VERSION "dbc-export 1 2026.26.6.5"

NS_ :

BS_:

BU_: ADSP APB APP APS APSB BB BMS CC CMP CMPD CP DAS DI DIF DIR DPB EPAS3P EPAS3S EPASTP EPASTS EPBL EPBR ESP EVSE FC GTW HCML HCMR HVP IBST ICR IDB LS OCS1P ODIN PARK PCS PCS2 PLG PM PMF PMR PNCD PTC RADC RCM RCM2 RCM3 RCU SCCM SCM SCS SDCR TAS TCU TCU2 TPMS TRCM UDS UI UIS UMC USM V2G VC VCBATT VCBATT0 VCBATT1 VCBATT2 VCCC VCFRONT VCFRONT1 VCFRONT2 VCLEFT VCRIGHT VCSEAT2L VCSEAT2R VCSEC VEH

BO_ 1056 UIS_log: 8 UIS
 SG_ UIS_logMux M : 0|32@1+ (1,0) [0|4294967295] "" Vector__XXX
 SG_ UIS_zramWriteTicks m0 : 32|32@1+ (1,0) [0|4294967295] "" Vector__XXX
 SG_ UIS_zramWriteIO m1 : 32|32@1+ (1,0) [0|4294967295] "" Vector__XXX
 SG_ UIS_zramReadTicks m2 : 32|32@1+ (1,0) [0|4294967295] "" Vector__XXX
 SG_ UIS_zramReadIO m3 : 32|32@1+ (1,0) [0|4294967295] "" Vector__XXX
 SG_ UIS_zramOriginalSize m4 : 32|32@1+ (1,0) [0|4294967295] "" Vector__XXX
 SG_ UIS_zramNotifyFree m5 : 32|32@1+ (1,0) [0|4294967295] "" Vector__XXX
 SG_ UIS_zramInvalidIO m6 : 32|32@1+ (1,0) [0|4294967295] "" Vector__XXX
 SG_ UIS_zramFailedWrites m7 : 32|32@1+ (1,0) [0|4294967295] "" Vector__XXX
 SG_ UIS_zramFailedReads m8 : 32|32@1+ (1,0) [0|4294967295] "" Vector__XXX
 SG_ UIS_zramCompressionRatio m9 : 32|32@1+ (1,0) [0|4294967295] "" Vector__XXX
 SG_ UIS_zramCompressedSize m10 : 32|32@1+ (1,0) [0|4294967295] "" Vector__XXX
 SG_ UIS_wifiTemperature m11 : 32|32@1+ (1,0) [0|4294967295] "" Vector__XXX
 SG_ UIS_wifiStackState m12 : 32|32@1+ (1,0) [0|4294967295] "" Vector__XXX
 SG_ UIS_wifiStackReady m13 : 32|32@1+ (1,0) [0|4294967295] "" Vector__XXX
 SG_ UIS_wifiBars m14 : 32|32@1+ (1,0) [0|4294967295] "" Vector__XXX
 SG_ UIS_wifiAutoJoinLowRSSI m15 : 32|32@1+ (1,0) [0|1] "" Vector__XXX
 SG_ UIS_webbrowserMemUsage m16 : 32|32@1+ (1,0) [0|4294967295] "" Vector__XXX
 SG_ UIS_webbrowserCPUUsage m17 : 32|32@1+ (1,0) [0|4294967295] "" Vector__XXX
 SG_ UIS_vmtouchMemUsage m18 : 32|32@1+ (1,0) [0|4294967295] "" Vector__XXX
 SG_ UIS_vmtouchCPUUsage m19 : 32|32@1+ (1,0) [0|4294967295] "" Vector__XXX
 SG_ UIS_videodMemUsage m20 : 32|32@1+ (1,0) [0|4294967295] "" Vector__XXX
 SG_ UIS_videodCPUUsage m21 : 32|32@1+ (1,0) [0|4294967295] "" Vector__XXX
 SG_ UIS_vehicleMemUsage m22 : 32|32@1+ (1,0) [0|4294967295] "" Vector__XXX
 SG_ UIS_vehicleCPUUsage m23 : 32|32@1+ (1,0) [0|4294967295] "" Vector__XXX
 SG_ UIS_valhallaserverMemUsage m24 : 32|32@1+ (1,0) [0|4294967295] "" Vector__XXX
 SG_ UIS_valhallaserverCPUUsage m25 : 32|32@1+ (1,0) [0|4294967295] "" Vector__XXX
 SG_ UIS_valetMode m26 : 32|32@1+ (1,0) [0|1] "" Vector__XXX
 SG_ UIS_uiQtCarUptime m27 : 32|32@1+ (1,0) [0|4294967295] "" Vector__XXX
 SG_ UIS_uiQtCarSwapUsage m28 : 32|32@1+ (1,0) [0|4294967295] "" Vector__XXX
 SG_ UIS_uiMeanFPS m29 : 32|32@1+ (1,0) [0|4294967295] "" Vector__XXX
 SG_ UIS_uiMaxFrametime m30 : 32|32@1+ (1,0) [0|4294967295] "" Vector__XXX
 SG_ UIS_uiFrametimeGearShiftPToR m31 : 32|32@1+ (1,0) [0|4294967295] "" Vector__XXX
 SG_ UIS_uiFrametimeGearShiftDToR m32 : 32|32@1+ (1,0) [0|4294967295] "" Vector__XXX
 SG_ UIS_uiFramesOver200Ms m33 : 32|32@1+ (1,0) [0|4294967295] "" Vector__XXX
 SG_ UIS_uiFramesOver100Ms m34 : 32|32@1+ (1,0) [0|4294967295] "" Vector__XXX
 SG_ UIS_tunerVoltageUBatt m35 : 32|32@1+ (1,0) [0|4294967295] "" Vector__XXX
 SG_ UIS_tunerVoltageOperation m36 : 32|32@1+ (1,0) [0|4294967295] "" Vector__XXX
 SG_ UIS_tunerVoltageMQS m37 : 32|32@1+ (1,0) [0|4294967295] "" Vector__XXX
 SG_ UIS_tunerVoltageAntenna2 m38 : 32|32@1+ (1,0) [0|4294967295] "" Vector__XXX
 SG_ UIS_tunerVoltageAntenna1 m39 : 32|32@1+ (1,0) [0|4294967295] "" Vector__XXX
 SG_ UIS_tunerVoltage3V3 m40 : 32|32@1+ (1,0) [0|4294967295] "" Vector__XXX
 SG_ UIS_tunerVoltage1V8 m41 : 32|32@1+ (1,0) [0|4294967295] "" Vector__XXX
 SG_ UIS_tunerTemperatureFahrenheit m42 : 32|32@1+ (1,0) [0|4294967295] "" Vector__XXX
 SG_ UIS_tunerTemperatureCelsius m43 : 32|32@1+ (1,0) [0|4294967295] "" Vector__XXX
 SG_ UIS_tunerCurrentAntenna2 m44 : 32|32@1+ (1,0) [0|4294967295] "" Vector__XXX
 SG_ UIS_tunerCurrentAntenna1 m45 : 32|32@1+ (1,0) [0|4294967295] "" Vector__XXX
 SG_ UIS_touchEventsAggCount m46 : 32|32@1+ (1,0) [0|4294967295] "" Vector__XXX
 SG_ UIS_tmserverMemUsage m47 : 32|32@1+ (1,0) [0|4294967295] "" Vector__XXX
 SG_ UIS_tmserverCPUUsage m48 : 32|32@1+ (1,0) [0|4294967295] "" Vector__XXX
 SG_ UIS_thermalResistance m49 : 32|32@1+ (1,0) [0|4294967295] "C/W" Vector__XXX
 SG_ UIS_thermalProfile m50 : 32|32@1+ (1,0) [1|4294967295] "" Vector__XXX
 SG_ UIS_testDriveMode m51 : 32|32@1+ (1,0) [0|4294967295] "" Vector__XXX
 SG_ UIS_teslachromiumMemUsage m52 : 32|32@1+ (1,0) [0|4294967295] "" Vector__XXX
 SG_ UIS_teslachromiumCPUUsage m53 : 32|32@1+ (1,0) [0|4294967295] "" Vector__XXX
 SG_ UIS_teslaMediaCacheSize m54 : 32|32@1+ (1,0) [0|4294967295] "" Vector__XXX
 SG_ UIS_teslaMediaCacheCost m55 : 32|32@1+ (1,0) [0|4294967295] "" Vector__XXX
 SG_ UIS_teleopStreamXrunCount m56 : 32|32@1+ (1,0) [0|4294967295] "" Vector__XXX
 SG_ UIS_teleopPhoneCallActive m57 : 32|32@1+ (1,0) [0|4294967295] "" Vector__XXX
 SG_ UIS_teleopPacketDrops m58 : 32|32@1+ (1,0) [0|4294967295] "" Vector__XXX
 SG_ UIS_teleopMinPacketDelta m59 : 32|32@1+ (0.0001,0) [0|429496.7295] "ms" Vector__XXX
 SG_ UIS_teleopMaxPacketDelta m60 : 32|32@1+ (0.0001,0) [0|429496.7295] "ms" Vector__XXX
 SG_ UIS_teleopAvgPacketDelta m61 : 32|32@1+ (0.0001,0) [0|429496.7295] "ms" Vector__XXX
 SG_ UIS_tegraModemManState m62 : 32|32@1+ (1,0) [0|4294967295] "" Vector__XXX
 SG_ UIS_systemWakeTime m63 : 32|32@1+ (1,0) [0|4294967295] "" Vector__XXX
 SG_ UIS_systemUptime m64 : 32|32@1+ (1,0) [0|4294967295] "" Vector__XXX
 SG_ UIS_systemMemSwapUsage m65 : 32|32@1+ (1,0) [0|4294967295] "" Vector__XXX
 SG_ UIS_suspensionGeofence m66 : 32|32@1+ (1,0) [0|1] "" Vector__XXX
 SG_ UIS_superchargePaymentNeeded m67 : 32|32@1+ (1,0) [0|4294967295] "" Vector__XXX
 SG_ UIS_sudokuMemUsage m68 : 32|32@1+ (1,0) [0|4294967295] "" Vector__XXX
 SG_ UIS_sudokuCPUUsage m69 : 32|32@1+ (1,0) [0|4294967295] "" Vector__XXX
 SG_ UIS_spotifyserverMemUsage m70 : 32|32@1+ (1,0) [0|4294967295] "" Vector__XXX
 SG_ UIS_spotifyserverCPUUsage m71 : 32|32@1+ (1,0) [0|4294967295] "" Vector__XXX
 SG_ UIS_speechrecoMemUsage m72 : 32|32@1+ (1,0) [0|4294967295] "" Vector__XXX
 SG_ UIS_speechrecoCPUUsage m73 : 32|32@1+ (1,0) [0|4294967295] "" Vector__XXX
 SG_ UIS_solitaireMemUsage m74 : 32|32@1+ (1,0) [0|4294967295] "" Vector__XXX
 SG_ UIS_solitaireCPUUsage m75 : 32|32@1+ (1,0) [0|4294967295] "" Vector__XXX
 SG_ UIS_softwareUpdateState m76 : 32|32@1+ (1,0) [0|4294967295] "" Vector__XXX
 SG_ UIS_softwareUpdatePrimDownload m77 : 32|32@1+ (1,0) [0|4294967295] "" Vector__XXX
 SG_ UIS_softwareInstallPopupStatus m78 : 32|32@1+ (1,0) [0|4294967295] "" Vector__XXX
 SG_ UIS_sleepType m79 : 32|32@1+ (1,0) [0|4294967295] "" Vector__XXX
 SG_ UIS_sleepTime m80 : 32|32@1+ (1,0) [0|4294967295] "" Vector__XXX
 SG_ UIS_sleepState m81 : 32|32@1+ (1,0) [0|4294967295] "" Vector__XXX
 SG_ UIS_sleepCount m82 : 32|32@1+ (1,0) [0|4294967295] "" Vector__XXX
 SG_ UIS_slackerLoginResult m83 : 32|32@1+ (1,0) [0|4294967295] "" Vector__XXX
 SG_ UIS_settingsAutoTurnSignal m84 : 32|32@1+ (1,0) [0|4294967295] "" Vector__XXX
 SG_ UIS_serviceModePlus m85 : 32|32@1+ (1,0) [0|4294967295] "" Vector__XXX
 SG_ UIS_serviceMode m86 : 32|32@1+ (1,0) [0|4294967295] "" Vector__XXX
 SG_ UIS_serverMemUsage m87 : 32|32@1+ (1,0) [0|4294967295] "" Vector__XXX
 SG_ UIS_serverCPUUsage m88 : 32|32@1+ (1,0) [0|4294967295] "" Vector__XXX
 SG_ UIS_sentryState m89 : 32|32@1+ (1,0) [0|4294967295] "" Vector__XXX
 SG_ UIS_sentryNeedsNap m90 : 32|32@1+ (1,0) [0|4294967295] "" Vector__XXX
 SG_ UIS_sentryIncidentCount m91 : 32|32@1+ (1,0) [0|4294967295] "" Vector__XXX
 SG_ UIS_scheduledChargingMode m92 : 32|32@1+ (1,0) [0|4294967295] "" Vector__XXX
 SG_ UIS_scheduleChargeStartTime m93 : 32|32@1+ (1,0) [0|4294967295] "" Vector__XXX
 SG_ UIS_scheduleChargeEndTime m94 : 32|32@1+ (1,0) [0|4294967295] "" Vector__XXX
 SG_ UIS_robotaxiModeActive m95 : 32|32@1+ (1,0) [0|4294967295] "" Vector__XXX
 SG_ UIS_remoteRequestType m96 : 32|32@1+ (1,0) [0|4294967295] "" Vector__XXX
 SG_ UIS_releasenotesMemUsage m97 : 32|32@1+ (1,0) [0|4294967295] "" Vector__XXX
 SG_ UIS_releasenotesCPUUsage m98 : 32|32@1+ (1,0) [0|4294967295] "" Vector__XXX
 SG_ UIS_rearDisplayUserPresent m99 : 32|32@1+ (1,0) [0|1] "" Vector__XXX
 SG_ UIS_rearDisplayState m100 : 32|32@1+ (1,0) [0|4294967295] "" Vector__XXX
 SG_ UIS_radioserveMemUsage m101 : 32|32@1+ (1,0) [0|4294967295] "" Vector__XXX
 SG_ UIS_radioserveCPUUsage m102 : 32|32@1+ (1,0) [0|4294967295] "" Vector__XXX
 SG_ UIS_qtcarMemUsage m103 : 32|32@1+ (1,0) [0|4294967295] "" Vector__XXX
 SG_ UIS_qtcarCPUUsage m104 : 32|32@1+ (1,0) [0|4294967295] "" Vector__XXX
 SG_ UIS_psiMemSome m105 : 32|32@1+ (1,0) [0|4294967295] "" Vector__XXX
 SG_ UIS_psiMemFull m106 : 32|32@1+ (1,0) [0|4294967295] "" Vector__XXX
 SG_ UIS_psiIOSome m107 : 32|32@1+ (1,0) [0|4294967295] "" Vector__XXX
 SG_ UIS_psiIOFull m108 : 32|32@1+ (1,0) [0|4294967295] "" Vector__XXX
 SG_ UIS_psiCpuSome m109 : 32|32@1+ (1,0) [0|4294967295] "" Vector__XXX
 SG_ UIS_powerManagerState m110 : 32|5@1+ (1,0) [0|31] "" Vector__XXX
 SG_ UIS_polytopiax8664MemUsage m111 : 32|32@1+ (1,0) [0|4294967295] "" Vector__XXX
 SG_ UIS_polytopiax8664CPUUsage m112 : 32|32@1+ (1,0) [0|4294967295] "" Vector__XXX
 SG_ UIS_odinStatusCmdResult m113 : 32|32@1+ (1,0) [0|4294967295] "" Vector__XXX
 SG_ UIS_odinStatusCmdDurationMs m114 : 32|32@1+ (1,0) [0|4294967295] "" Vector__XXX
 SG_ UIS_odinProcessState m115 : 32|32@1+ (1,0) [0|4294967295] "" Vector__XXX
 SG_ UIS_odinPeriodicTaskState m116 : 32|32@1+ (1,0) [0|4294967295] "" Vector__XXX
 SG_ UIS_odinOrchestratorStartCount m117 : 32|32@1+ (1,0) [0|4294967295] "" Vector__XXX
 SG_ UIS_odinOrchestratorFailCount m118 : 32|32@1+ (1,0) [0|4294967295] "" Vector__XXX
 SG_ UIS_odinNetworkStartCount m119 : 32|32@1+ (1,0) [0|4294967295] "" Vector__XXX
 SG_ UIS_odinNetworkFailCount m120 : 32|32@1+ (1,0) [0|4294967295] "" Vector__XXX
 SG_ UIS_odinMemUsage m121 : 32|32@1+ (1,0) [0|4294967295] "" Vector__XXX
 SG_ UIS_odinListTasksCmdResult m122 : 32|32@1+ (1,0) [0|4294967295] "" Vector__XXX
 SG_ UIS_odinListTasksCmdDurationMs m123 : 32|32@1+ (1,0) [0|4294967295] "" Vector__XXX
 SG_ UIS_odinHrlUploadLimits m124 : 32|32@1+ (1,0) [0|4294967295] "" Vector__XXX
 SG_ UIS_odinHrlLogUploadState m125 : 32|32@1+ (1,0) [0|4294967295] "" Vector__XXX
 SG_ UIS_odinHermesConnectionState m126 : 32|32@1+ (1,0) [0|4294967295] "" Vector__XXX
 SG_ UIS_odinGatewayConnectionState m127 : 32|32@1+ (1,0) [0|4294967295] "" Vector__XXX
 SG_ UIS_odinFileSystemState m128 : 32|32@1+ (1,0) [0|4294967295] "" Vector__XXX
 SG_ UIS_odinEcuLogUploadState m129 : 32|32@1+ (1,0) [0|4294967295] "" Vector__XXX
 SG_ UIS_odinEcuLogForceTriggerUpload m130 : 32|32@1+ (1,0) [0|4294967295] "" Vector__XXX
 SG_ UIS_odinCPUUsage m131 : 32|32@1+ (1,0) [0|4294967295] "" Vector__XXX
 SG_ UIS_odinAuthFailCount m132 : 32|32@1+ (1,0) [0|4294967295] "" Vector__XXX
 SG_ UIS_odinAuthCount m133 : 32|32@1+ (1,0) [0|4294967295] "" Vector__XXX
 SG_ UIS_nvmeTemperature m134 : 32|32@1+ (1,0) [0|4294967295] "" Vector__XXX
 SG_ UIS_nvmePercentLifetimeUsed m135 : 32|32@1+ (1,0) [0|4294967295] "" Vector__XXX
 SG_ UIS_nvmeDataUnitsWritten100mb m136 : 32|32@1+ (1,0) [0|4294967295] "" Vector__XXX
 SG_ UIS_numUncorrMemErrorsECC m137 : 32|32@1+ (1,0) [0|4294967295] "" Vector__XXX
 SG_ UIS_numCorrMemErrorsECC m138 : 32|32@1+ (1,0) [0|4294967295] "" Vector__XXX
 SG_ UIS_nuanceserverMemUsage m139 : 32|32@1+ (1,0) [0|4294967295] "" Vector__XXX
 SG_ UIS_nuanceserverCPUUsage m140 : 32|32@1+ (1,0) [0|4294967295] "" Vector__XXX
 SG_ UIS_netWifiTxRate m141 : 32|32@1+ (0.001,0) [0|4294967.295] "Megabytes per second (MBps)" Vector__XXX
 SG_ UIS_netWifiTxCount m142 : 32|32@1+ (0.001,0) [0|4294967.295] "Megabytes" Vector__XXX
 SG_ UIS_netWifiRxRate m143 : 32|32@1+ (0.001,0) [0|4294967.295] "Megabytes per second (MBps)" Vector__XXX
 SG_ UIS_netWifiRxCount m144 : 32|32@1+ (0.001,0) [0|4294967.295] "Megabytes" Vector__XXX
 SG_ UIS_netEthTxRate m145 : 32|32@1+ (0.001,0) [0|4294967.295] "Megabytes per second (MBps)" Vector__XXX
 SG_ UIS_netEthTxCount m146 : 32|32@1+ (0.001,0) [0|4294967.295] "Megabytes" Vector__XXX
 SG_ UIS_netEthRxRate m147 : 32|32@1+ (0.001,0) [0|4294967.295] "Megabytes per second (MBps)" Vector__XXX
 SG_ UIS_netEthRxErrorRate m148 : 32|32@1+ (1,0) [0|4294967295] "" Vector__XXX
 SG_ UIS_netEthRxErrorCount m149 : 32|32@1+ (1,0) [0|4294967295] "" Vector__XXX
 SG_ UIS_netEthRxDroppedRate m150 : 32|32@1+ (1,0) [0|4294967295] "" Vector__XXX
 SG_ UIS_netEthRxDroppedCount m151 : 32|32@1+ (1,0) [0|4294967295] "" Vector__XXX
 SG_ UIS_netEthRxCount m152 : 32|32@1+ (0.001,0) [0|4294967.295] "Megabytes" Vector__XXX
 SG_ UIS_netCellTxRate m153 : 32|32@1+ (0.001,0) [0|4294967.295] "Megabytes per second (MBps)" Vector__XXX
 SG_ UIS_netCellTxCount m154 : 32|32@1+ (0.001,0) [0|4294967.295] "Megabytes" Vector__XXX
 SG_ UIS_netCellRxRate m155 : 32|32@1+ (0.001,0) [0|4294967.295] "Megabytes per second (MBps)" Vector__XXX
 SG_ UIS_netCellRxCount m156 : 32|32@1+ (0.001,0) [0|4294967.295] "Megabytes" Vector__XXX
 SG_ UIS_navServiceError m157 : 32|32@1+ (1,0) [0|4294967295] "" Vector__XXX
 SG_ UIS_navAudioVolume m158 : 32|32@1+ (1,0) [0|4294967295] "" Vector__XXX
 SG_ UIS_muteNavVolume m159 : 32|32@1+ (1,0) [0|4294967295] "" Vector__XXX
 SG_ UIS_mounterdState m160 : 32|32@1+ (1,0) [0|4294967295] "" Vector__XXX
 SG_ UIS_mounterdMountCountTotal m161 : 32|32@1+ (1,0) [0|4294967295] "" Vector__XXX
 SG_ UIS_mounterdFrontHubDisconnected m162 : 32|32@1+ (1,0) [0|4294967295] "" Vector__XXX
 SG_ UIS_mounterdFrontHubConnected m163 : 32|32@1+ (1,0) [0|4294967295] "" Vector__XXX
 SG_ UIS_mounterdFilesystemCountFat32 m164 : 32|32@1+ (1,0) [0|4294967295] "" Vector__XXX
 SG_ UIS_mounterdFilesystemCountExt4 m165 : 32|32@1+ (1,0) [0|4294967295] "" Vector__XXX
 SG_ UIS_mounterdFilesystemCountExt3 m166 : 32|32@1+ (1,0) [0|4294967295] "" Vector__XXX
 SG_ UIS_mounterdFilesystemCountExfat m167 : 32|32@1+ (1,0) [0|4294967295] "" Vector__XXX
 SG_ UIS_mounterdEncryptionCapacityGB m168 : 32|32@1+ (1,0) [0|4294967295] "" Vector__XXX
 SG_ UIS_mounterdDeviceCount m169 : 32|32@1+ (1,0) [0|4294967295] "" Vector__XXX
 SG_ UIS_mounterdDashcamCapacityGB m170 : 32|32@1+ (1,0) [0|4294967295] "" Vector__XXX
 SG_ UIS_modemECallppAvail m171 : 32|32@1+ (1,0) [0|1] "" Vector__XXX
 SG_ UIS_modemBusyActive m172 : 32|32@1+ (1,0) [0|1] "" Vector__XXX
 SG_ UIS_mirrorGeofenceActive m173 : 32|32@1+ (1,0) [0|1] "" Vector__XXX
 SG_ UIS_mediaserveMemUsage m174 : 32|32@1+ (1,0) [0|4294967295] "" Vector__XXX
 SG_ UIS_mediaserveCPUUsage m175 : 32|32@1+ (1,0) [0|4294967295] "" Vector__XXX
 SG_ UIS_mediaPlaybackStatus m176 : 32|32@1+ (1,0) [0|4294967295] "" Vector__XXX
 SG_ UIS_mediaNeedAuthToken m177 : 32|32@1+ (1,0) [0|1] "" Vector__XXX
 SG_ UIS_mediaImageCacheSize m178 : 32|32@1+ (1,0) [0|4294967295] "" Vector__XXX
 SG_ UIS_mediaImageCacheCost m179 : 32|32@1+ (1,0) [0|4294967295] "" Vector__XXX
 SG_ UIS_limex8664MemUsage m180 : 32|32@1+ (1,0) [0|4294967295] "" Vector__XXX
 SG_ UIS_limex8664CPUUsage m181 : 32|32@1+ (1,0) [0|4294967295] "" Vector__XXX
 SG_ UIS_inSuperchargerGeofence m182 : 32|32@1+ (1,0) [0|1] "" Vector__XXX
 SG_ UIS_igpuTemperature m183 : 32|32@1+ (1,0) [0|4294967295] "" Vector__XXX
 SG_ UIS_homelinkState m184 : 32|32@1+ (1,0) [0|4294967295] "" Vector__XXX
 SG_ UIS_hicarServiceState m185 : 32|32@1+ (1,0) [0|4294967295] "" Vector__XXX
 SG_ UIS_hicarEventCode m186 : 32|32@1+ (1,0) [0|4294967295] "" Vector__XXX
 SG_ UIS_hicarErrorCode m187 : 32|32@1+ (1,0) [0|4294967295] "" Vector__XXX
 SG_ UIS_hicarDataReceiveType m188 : 32|32@1+ (1,0) [0|4294967295] "" Vector__XXX
 SG_ UIS_hicarConnectionState m189 : 32|32@1+ (1,0) [0|4294967295] "" Vector__XXX
 SG_ UIS_hicarCallState m190 : 32|32@1+ (1,0) [0|4294967295] "" Vector__XXX
 SG_ UIS_hicarAudioTeardownState m191 : 32|32@1+ (1,0) [0|4294967295] "" Vector__XXX
 SG_ UIS_hicarAudioSetupState m192 : 32|32@1+ (1,0) [0|4294967295] "" Vector__XXX
 SG_ UIS_hermesdynamicMemUsage m193 : 32|32@1+ (1,0) [0|4294967295] "" Vector__XXX
 SG_ UIS_hermesdynamicCPUUsage m194 : 32|32@1+ (1,0) [0|4294967295] "" Vector__XXX
 SG_ UIS_hermesclientMemUsage m195 : 32|32@1+ (1,0) [0|4294967295] "" Vector__XXX
 SG_ UIS_hermesclientCPUUsage m196 : 32|32@1+ (1,0) [0|4294967295] "" Vector__XXX
 SG_ UIS_headsetPairResult m197 : 32|32@1+ (1,0) [0|4294967295] "" Vector__XXX
 SG_ UIS_headsetConnectionState m198 : 32|32@1+ (1,0) [0|4294967295] "" Vector__XXX
 SG_ UIS_gtwSocUartTxStatTimeouts m199 : 32|32@1+ (1,0) [0|4294967295] "" Vector__XXX
 SG_ UIS_gtwSocUartTxStatPackets m200 : 32|32@1+ (1,0) [0|4294967295] "" Vector__XXX
 SG_ UIS_gtwSocUartTxStatNacks m201 : 32|32@1+ (1,0) [0|4294967295] "" Vector__XXX
 SG_ UIS_gtwSocUartTxStatBadTooBig m202 : 32|32@1+ (1,0) [0|4294967295] "" Vector__XXX
 SG_ UIS_gtwSocUartTxStatAnsMismatch m203 : 32|32@1+ (1,0) [0|4294967295] "" Vector__XXX
 SG_ UIS_gtwSocUartRxStatValidPackets m204 : 32|32@1+ (1,0) [0|4294967295] "" Vector__XXX
 SG_ UIS_gtwSocUartRxStatUnhandled m205 : 32|32@1+ (1,0) [0|4294967295] "" Vector__XXX
 SG_ UIS_gtwSocUartRxStatMsgErr m206 : 32|32@1+ (1,0) [0|4294967295] "" Vector__XXX
 SG_ UIS_gtwSocUartRxStatHeartbeats m207 : 32|32@1+ (1,0) [0|4294967295] "" Vector__XXX
 SG_ UIS_gtwSocUartRxStatHandleErr m208 : 32|32@1+ (1,0) [0|4294967295] "" Vector__XXX
 SG_ UIS_gtwSocUartRxStatBadTooSmall m209 : 32|32@1+ (1,0) [0|4294967295] "" Vector__XXX
 SG_ UIS_gtwSocUartRxStatBadTooBig m210 : 32|32@1+ (1,0) [0|4294967295] "" Vector__XXX
 SG_ UIS_gtwSocUartRxStatBadChecksum m211 : 32|32@1+ (1,0) [0|4294967295] "" Vector__XXX
 SG_ UIS_gpsmanagerMemUsage m212 : 32|32@1+ (1,0) [0|4294967295] "" Vector__XXX
 SG_ UIS_gpsmanagerCPUUsage m213 : 32|32@1+ (1,0) [0|4294967295] "" Vector__XXX
 SG_ UIS_godot_TIME_PROCESS m214 : 32|32@1+ (1,0) [0|4294967295] "" Vector__XXX
 SG_ UIS_godot_TIME_FPS m215 : 32|32@1+ (1,0) [0|4294967295] "" Vector__XXX
 SG_ UIS_godot_MEMORY_STATIC m216 : 32|32@1+ (1,0) [0|4294967295] "" Vector__XXX
 SG_ UIS_godot_MEMORY_DYNAMIC m217 : 32|32@1+ (1,0) [0|4294967295] "" Vector__XXX
 SG_ UIS_godotMemUsage m218 : 32|32@1+ (1,0) [0|4294967295] "" Vector__XXX
 SG_ UIS_godotCPUUsage m219 : 32|32@1+ (1,0) [0|4294967295] "" Vector__XXX
 SG_ UIS_firmwareReleaseScope m220 : 32|32@1+ (1,0) [0|4294967295] "" Vector__XXX
 SG_ UIS_featureSuperchargingEnabled m221 : 32|32@1+ (1,0) [0|4294967295] "" Vector__XXX
 SG_ UIS_estimatedOccupancyCount m222 : 32|32@1+ (1,0) [0|4294967295] "" Vector__XXX
 SG_ UIS_embeddedGameState m223 : 32|32@1+ (1,0) [0|4294967295] "" Vector__XXX
 SG_ UIS_embeddedGameName m224 : 32|32@1+ (1,0) [0|4294967295] "" Vector__XXX
 SG_ UIS_dynamicTriggersTelemetryServ m225 : 32|32@1+ (1,0) [0|4294967295] "" Vector__XXX
 SG_ UIS_dynamicTriggersOutputManager m226 : 32|32@1+ (1,0) [0|4294967295] "" Vector__XXX
 SG_ UIS_dynamicTriggersHRLServiceSta m227 : 32|32@1+ (1,0) [0|4294967295] "" Vector__XXX
 SG_ UIS_dynamicTriggersCampaignState m228 : 32|32@1+ (1,0) [1|4294967295] "" Vector__XXX
 SG_ UIS_dumTclipUploadState m229 : 32|32@1+ (1,0) [0|4294967295] "" Vector__XXX
 SG_ UIS_dumTclipUploadActive m230 : 32|32@1+ (1,0) [0|4294967295] "" Vector__XXX
 SG_ UIS_dumTclipTransferCount m231 : 32|32@1+ (1,0) [0|4294967295] "" Vector__XXX
 SG_ UIS_dumTclipSuccessfulUploadCoun m232 : 32|32@1+ (1,0) [0|4294967295] "" Vector__XXX
 SG_ UIS_dumTclipClipCount m233 : 32|32@1+ (1,0) [0|4294967295] "" Vector__XXX
 SG_ UIS_dmRearTouchDeviceExists m234 : 32|32@1+ (1,0) [0|4294967295] "" Vector__XXX
 SG_ UIS_dmRearPowerState m235 : 32|32@1+ (1,0) [0|1] "" Vector__XXX
 SG_ UIS_dmRearLinkCheckOk m236 : 32|32@1+ (1,0) [0|1] "" Vector__XXX
 SG_ UIS_dmRearEnabled m237 : 32|32@1+ (1,0) [0|4294967295] "" Vector__XXX
 SG_ UIS_dmRearConnected m238 : 32|32@1+ (1,0) [0|4294967295] "" Vector__XXX
 SG_ UIS_dmRearBacklightPowerLevel m239 : 32|32@1+ (1,0) [0|4294967295] "" Vector__XXX
 SG_ UIS_dmRearBacklightNits m240 : 32|32@1+ (1,0) [0|4294967295] "" Vector__XXX
 SG_ UIS_dmRearBacklightFault m241 : 32|32@1+ (1,0) [0|4294967295] "" Vector__XXX
 SG_ UIS_dmRearBacklightDutyCycle m242 : 32|32@1+ (1,0) [0|4294967295] "" Vector__XXX
 SG_ UIS_dmRearBacklightDevExists m243 : 32|32@1+ (1,0) [0|1] "" Vector__XXX
 SG_ UIS_dmRearAsilStatusMsb m244 : 32|32@1+ (1,0) [0|4294967295] "" Vector__XXX
 SG_ UIS_dmRearAsilStatusLsb m245 : 32|32@1+ (1,0) [0|4294967295] "" Vector__XXX
 SG_ UIS_dmIcuTouchIrqCount m246 : 32|32@1+ (1,0) [0|4294967295] "" Vector__XXX
 SG_ UIS_dmIcuPowerState m247 : 32|32@1+ (1,0) [0|1] "" Vector__XXX
 SG_ UIS_dmIcuLinkCheckOk m248 : 32|32@1+ (1,0) [0|1] "" Vector__XXX
 SG_ UIS_dmIcuEnabled m249 : 32|32@1+ (1,0) [0|4294967295] "" Vector__XXX
 SG_ UIS_dmIcuConnected m250 : 32|32@1+ (1,0) [0|4294967295] "" Vector__XXX
 SG_ UIS_dmIcuBacklightPowerLevel m251 : 32|32@1+ (1,0) [0|4294967295] "" Vector__XXX
 SG_ UIS_dmIcuBacklightNits m252 : 32|32@1+ (1,0) [0|4294967295] "" Vector__XXX
 SG_ UIS_dmIcuBacklightFault m253 : 32|32@1+ (1,0) [0|4294967295] "" Vector__XXX
 SG_ UIS_dmIcuBacklightDutyCycle m254 : 32|32@1+ (1,0) [0|4294967295] "" Vector__XXX
 SG_ UIS_dmIcuBacklightDevExists m255 : 32|32@1+ (1,0) [0|1] "" Vector__XXX
 SG_ UIS_dmIcuAsilShortFlag m256 : 32|32@1+ (1,0) [0|4294967295] "" Vector__XXX
 SG_ UIS_dmIcuAsilResumeFlag m257 : 32|32@1+ (1,0) [0|4294967295] "" Vector__XXX
 SG_ UIS_dmIcuAsilOpenFlag m258 : 32|32@1+ (1,0) [0|4294967295] "" Vector__XXX
 SG_ UIS_dmIcuAsilFirmwareStatus m259 : 32|32@1+ (1,0) [0|4294967295] "" Vector__XXX
 SG_ UIS_dmGatewayLinkWedged m260 : 32|32@1+ (1,0) [0|4294967295] "" Vector__XXX
 SG_ UIS_dmCenterTouchIrqCount m261 : 32|32@1+ (1,0) [0|4294967295] "" Vector__XXX
 SG_ UIS_dmCenterTouchDeviceExists m262 : 32|32@1+ (1,0) [0|4294967295] "" Vector__XXX
 SG_ UIS_dmCenterSOsdVideoCrcData m263 : 32|32@1+ (1,0) [0|4294967295] "" Vector__XXX
 SG_ UIS_dmCenterSOsdExactCrcCheck m264 : 32|32@1+ (1,0) [0|4294967295] "" Vector__XXX
 SG_ UIS_dmCenterPowerState m265 : 32|32@1+ (1,0) [0|1] "" Vector__XXX
 SG_ UIS_dmCenterOsdDisplayedState m266 : 32|32@1+ (1,0) [0|1] "" Vector__XXX
 SG_ UIS_dmCenterOsdDayNightState m267 : 32|32@1+ (1,0) [0|4294967295] "" Vector__XXX
 SG_ UIS_dmCenterModeSettingStatus m268 : 32|32@1+ (1,0) [0|4294967295] "" Vector__XXX
 SG_ UIS_dmCenterMOsdVideoCrcData m269 : 32|32@1+ (1,0) [0|4294967295] "" Vector__XXX
 SG_ UIS_dmCenterMOsdExactCrcCheck m270 : 32|32@1+ (1,0) [0|4294967295] "" Vector__XXX
 SG_ UIS_dmCenterLinkCheckOk m271 : 32|32@1+ (1,0) [0|1] "" Vector__XXX
 SG_ UIS_dmCenterEnabled m272 : 32|32@1+ (1,0) [0|4294967295] "" Vector__XXX
 SG_ UIS_dmCenterConnected m273 : 32|32@1+ (1,0) [0|4294967295] "" Vector__XXX
 SG_ UIS_dmCenterBacklightPowerLevel m274 : 32|32@1+ (1,0) [0|4294967295] "" Vector__XXX
 SG_ UIS_dmCenterBacklightNits m275 : 32|32@1+ (1,0) [0|4294967295] "" Vector__XXX
 SG_ UIS_dmCenterBacklightFault m276 : 32|32@1+ (1,0) [0|4294967295] "" Vector__XXX
 SG_ UIS_dmCenterBacklightDutyCycle m277 : 32|32@1+ (1,0) [0|4294967295] "" Vector__XXX
 SG_ UIS_dmCenterBacklightDevExists m278 : 32|32@1+ (1,0) [0|1] "" Vector__XXX
 SG_ UIS_dmCenterBacklightControlDefe m279 : 32|32@1+ (1,0) [0|4294967295] "" Vector__XXX
 SG_ UIS_dmCenterAsilShortFlag m280 : 32|32@1+ (1,0) [0|4294967295] "" Vector__XXX
 SG_ UIS_dmCenterAsilResumeFlag m281 : 32|32@1+ (1,0) [0|4294967295] "" Vector__XXX
 SG_ UIS_dmCenterAsilOpenFlag m282 : 32|32@1+ (1,0) [0|4294967295] "" Vector__XXX
 SG_ UIS_dmCenterAsilFirmwareStatus m283 : 32|32@1+ (1,0) [0|4294967295] "" Vector__XXX
 SG_ UIS_dmCenterAsilCalibrationSync m284 : 32|32@1+ (1,0) [0|4294967295] "" Vector__XXX
 SG_ UIS_dgpuTemperature m285 : 32|32@1+ (1,0) [0|4294967295] "" Vector__XXX
 SG_ UIS_developerMode m286 : 32|32@1+ (1,0) [0|4294967295] "" Vector__XXX
 SG_ UIS_dashcamviewerMemUsage m287 : 32|32@1+ (1,0) [0|4294967295] "" Vector__XXX
 SG_ UIS_dashcamviewerCPUUsage m288 : 32|32@1+ (1,0) [0|4294967295] "" Vector__XXX
 SG_ UIS_dashcamTransferTimeMs m289 : 32|32@1+ (1,0) [0|4294967295] "" Vector__XXX
 SG_ UIS_dashcamTransferSizeMB m290 : 32|32@1+ (1,0) [0|4294967295] "" Vector__XXX
 SG_ UIS_dashcamTransferRateMBps m291 : 32|32@1+ (1,0) [0|4294967295] "" Vector__XXX
 SG_ UIS_dashcamTransferFileCount m292 : 32|32@1+ (1,0) [0|4294967295] "" Vector__XXX
 SG_ UIS_dashcamTransferCount m293 : 32|32@1+ (1,0) [0|4294967295] "" Vector__XXX
 SG_ UIS_dashcamStorageState m294 : 32|32@1+ (1,0) [0|4294967295] "" Vector__XXX
 SG_ UIS_dashcamStorageSentryMB m295 : 32|32@1+ (1,0) [0|4294967295] "" Vector__XXX
 SG_ UIS_dashcamStorageSavedMB m296 : 32|32@1+ (1,0) [0|4294967295] "" Vector__XXX
 SG_ UIS_dashcamStorageRecentMB m297 : 32|32@1+ (1,0) [0|4294967295] "" Vector__XXX
 SG_ UIS_dashcamStorageAvailableMB m298 : 32|32@1+ (1,0) [0|4294967295] "" Vector__XXX
 SG_ UIS_dashcamState m299 : 32|32@1+ (1,0) [0|4294967295] "" Vector__XXX
 SG_ UIS_dashcamSavedToSentryCount m300 : 32|32@1+ (1,0) [0|4294967295] "" Vector__XXX
 SG_ UIS_dashcamSavedToSavedCount m301 : 32|32@1+ (1,0) [0|4294967295] "" Vector__XXX
 SG_ UIS_dashcamSavedToOnboardCount m302 : 32|32@1+ (1,0) [0|4294967295] "" Vector__XXX
 SG_ UIS_dashcamOnboardTransferCount m303 : 32|32@1+ (1,0) [0|4294967295] "" Vector__XXX
 SG_ UIS_dashcamOnboardSavePressCount m304 : 32|32@1+ (1,0) [0|4294967295] "" Vector__XXX
 SG_ UIS_dashcamOnboardMB m305 : 32|32@1+ (1,0) [0|4294967295] "" Vector__XXX
 SG_ UIS_dashcamOnboardAvailableMB m306 : 32|32@1+ (1,0) [0|4294967295] "" Vector__XXX
 SG_ UIS_dasAutonomyControlMessageMia m307 : 32|32@1+ (1,0) [0|4294967295] "" Vector__XXX
 SG_ UIS_cpuTemperature m308 : 32|32@1+ (1,0) [0|4294967295] "" Vector__XXX
 SG_ UIS_connectedToInternet m309 : 32|32@1+ (1,0) [0|4294967295] "" Vector__XXX
 SG_ UIS_compositorRenderMinRenderTim m310 : 32|32@1+ (1,0) [0|4294967295] "" Vector__XXX
 SG_ UIS_compositorRenderMinFrameTime m311 : 32|32@1+ (1,0) [0|4294967295] "" Vector__XXX
 SG_ UIS_compositorRenderMaxRenderTim m312 : 32|32@1+ (1,0) [0|4294967295] "" Vector__XXX
 SG_ UIS_compositorRenderMaxFrameTime m313 : 32|32@1+ (1,0) [0|4294967295] "" Vector__XXX
 SG_ UIS_compositorRenderGpuPercentag m314 : 32|32@1+ (1,0) [0|4294967295] "" Vector__XXX
 SG_ UIS_compositorRenderFrameRate m315 : 32|32@1+ (1,0) [0|4294967295] "" Vector__XXX
 SG_ UIS_compositorRenderFrameCount m316 : 32|32@1+ (1,0) [0|4294967295] "" Vector__XXX
 SG_ UIS_compositorRenderAvgRenderTim m317 : 32|32@1+ (1,0) [0|4294967295] "" Vector__XXX
 SG_ UIS_compositorFrameMonitorState m318 : 32|32@1+ (1,0) [0|4294967295] "" Vector__XXX
 SG_ UIS_cobaltlinuxMemUsage m319 : 32|32@1+ (1,0) [0|4294967295] "" Vector__XXX
 SG_ UIS_cobaltlinuxCPUUsage m320 : 32|32@1+ (1,0) [0|4294967295] "" Vector__XXX
 SG_ UIS_clusterMemUsage m321 : 32|32@1+ (1,0) [0|4294967295] "" Vector__XXX
 SG_ UIS_clusterMeanFPS m322 : 32|32@1+ (1,0) [0|4294967295] "" Vector__XXX
 SG_ UIS_clusterMaxFrametime m323 : 32|32@1+ (1,0) [0|4294967295] "" Vector__XXX
 SG_ UIS_clusterFramesOver200Ms m324 : 32|32@1+ (1,0) [0|4294967295] "" Vector__XXX
 SG_ UIS_clusterFramesOver100Ms m325 : 32|32@1+ (1,0) [0|4294967295] "" Vector__XXX
 SG_ UIS_clusterDisplayState m326 : 32|32@1+ (1,0) [0|4294967295] "" Vector__XXX
 SG_ UIS_clusterCPUUsage m327 : 32|32@1+ (1,0) [0|4294967295] "" Vector__XXX
 SG_ UIS_chromiumadapterMemUsage m328 : 32|32@1+ (1,0) [0|4294967295] "" Vector__XXX
 SG_ UIS_chromiumadapterCPUUsage m329 : 32|32@1+ (1,0) [0|4294967295] "" Vector__XXX
 SG_ UIS_chargeOnSolarNoChargeReason m330 : 32|32@1+ (1,0) [0|4294967295] "" Vector__XXX
 SG_ UIS_chargeLocationId m331 : 32|32@1+ (1,0) [0|4294967295] "" Vector__XXX
 SG_ UIS_ceruleanx8664MemUsage m332 : 32|32@1+ (1,0) [0|4294967295] "" Vector__XXX
 SG_ UIS_ceruleanx8664CPUUsage m333 : 32|32@1+ (1,0) [0|4294967295] "" Vector__XXX
 SG_ UIS_centerDisplayState m334 : 32|32@1+ (1,0) [0|4294967295] "" Vector__XXX
 SG_ UIS_centerDisplayEvent m335 : 32|32@1+ (1,0) [0|4294967295] "" Vector__XXX
 SG_ UIS_centerDispAsilB_msb m336 : 32|32@1+ (1,0) [0|4294967295] "" Vector__XXX
 SG_ UIS_centerDispAsilB_lsb m337 : 32|32@1+ (1,0) [0|4294967295] "" Vector__XXX
 SG_ UIS_centerDispAsilA_msb m338 : 32|32@1+ (1,0) [0|4294967295] "" Vector__XXX
 SG_ UIS_centerDispAsilA_lsb m339 : 32|32@1+ (1,0) [0|4294967295] "" Vector__XXX
 SG_ UIS_cellularLinkManagerState m340 : 32|32@1+ (1,0) [0|4294967295] "" Vector__XXX
 SG_ UIS_cellularConnectivityStatus m341 : 32|32@1+ (1,0) [0|1] "" Vector__XXX
 SG_ UIS_carAssistState m369 : 32|32@1+ (1,0) [0|4294967295] "" Vector__XXX
 SG_ UIS_carAssistSessionCount m370 : 32|32@1+ (1,0) [0|4294967295] "" Vector__XXX
 SG_ UIS_carAssistMicMuted m371 : 32|32@1+ (1,0) [0|1] "" Vector__XXX
 SG_ UIS_carAssistMicAlsaRms m372 : 32|32@1+ (1,0) [0|4294967295] "" Vector__XXX
 SG_ UIS_carAssistErrorCode m373 : 32|32@1+ (1,0) [0|4294967295] "" Vector__XXX
 SG_ UIS_cameraSelectableRenderState m374 : 32|32@1+ (1,0) [0|4294967295] "" Vector__XXX
 SG_ UIS_cameraSelectablePipeline m375 : 32|32@1+ (1,0) [0|4294967295] "" Vector__XXX
 SG_ UIS_cameraSelectablePacketState m376 : 32|32@1+ (1,0) [0|4294967295] "" Vector__XXX
 SG_ UIS_cameraRearViewStreamMissing m377 : 32|32@1+ (1,0) [0|4294967295] "" Vector__XXX
 SG_ UIS_cameraRearViewRenderState m378 : 32|32@1+ (1,0) [0|4294967295] "" Vector__XXX
 SG_ UIS_cameraRearViewPopup m379 : 32|32@1+ (1,0) [0|4294967295] "" Vector__XXX
 SG_ UIS_cameraRearViewPipeline m380 : 32|32@1+ (1,0) [0|4294967295] "" Vector__XXX
 SG_ UIS_cameraRearViewPacketState m381 : 32|32@1+ (1,0) [0|4294967295] "" Vector__XXX
 SG_ UIS_cameraRRepeaterStreamMissing m382 : 32|32@1+ (1,0) [0|1] "" Vector__XXX
 SG_ UIS_cameraRRepeaterRenderState m383 : 32|32@1+ (1,0) [0|4294967295] "" Vector__XXX
 SG_ UIS_cameraRRepeaterPopup m384 : 32|32@1+ (1,0) [0|1] "" Vector__XXX
 SG_ UIS_cameraRRepeaterPipeline m385 : 32|32@1+ (1,0) [0|4294967295] "" Vector__XXX
 SG_ UIS_cameraRRepeaterPacketState m386 : 32|32@1+ (1,0) [0|4294967295] "" Vector__XXX
 SG_ UIS_cameraRRepeaterMaxFrametime m387 : 32|32@1+ (1,0) [0|4294967295] "" Vector__XXX
 SG_ UIS_cameraRRepeaterLateFrames m388 : 32|32@1+ (1,0) [0|4294967295] "" Vector__XXX
 SG_ UIS_cameraRRepeaterFramerate m389 : 32|32@1+ (1,0) [0|4294967295] "" Vector__XXX
 SG_ UIS_cameraRDownwardRenderState m390 : 32|32@1+ (1,0) [0|4294967295] "" Vector__XXX
 SG_ UIS_cameraRDownwardPipeline m391 : 32|32@1+ (1,0) [0|4294967295] "" Vector__XXX
 SG_ UIS_cameraRDownwardPacketState m392 : 32|32@1+ (1,0) [0|4294967295] "" Vector__XXX
 SG_ UIS_cameraLRepeaterStreamMissing m393 : 32|32@1+ (1,0) [0|1] "" Vector__XXX
 SG_ UIS_cameraLRepeaterRenderState m394 : 32|32@1+ (1,0) [0|4294967295] "" Vector__XXX
 SG_ UIS_cameraLRepeaterPopup m395 : 32|32@1+ (1,0) [0|1] "" Vector__XXX
 SG_ UIS_cameraLRepeaterPipeline m396 : 32|32@1+ (1,0) [0|4294967295] "" Vector__XXX
 SG_ UIS_cameraLRepeaterPacketState m397 : 32|32@1+ (1,0) [0|4294967295] "" Vector__XXX
 SG_ UIS_cameraLRepeaterMaxFrametime m398 : 32|32@1+ (1,0) [0|4294967295] "" Vector__XXX
 SG_ UIS_cameraLRepeaterLateFrames m399 : 32|32@1+ (1,0) [0|4294967295] "" Vector__XXX
 SG_ UIS_cameraLRepeaterFramerate m400 : 32|32@1+ (1,0) [0|4294967295] "" Vector__XXX
 SG_ UIS_cameraLDownwardRenderState m401 : 32|32@1+ (1,0) [0|4294967295] "" Vector__XXX
 SG_ UIS_cameraLDownwardPipeline m402 : 32|32@1+ (1,0) [0|4294967295] "" Vector__XXX
 SG_ UIS_cameraLDownwardPacketState m403 : 32|32@1+ (1,0) [0|4294967295] "" Vector__XXX
 SG_ UIS_cameraFrontStreamMissing m404 : 32|32@1+ (1,0) [0|4294967295] "" Vector__XXX
 SG_ UIS_cameraFrontRenderState m405 : 32|32@1+ (1,0) [0|4294967295] "" Vector__XXX
 SG_ UIS_cameraFrontPopup m406 : 32|32@1+ (1,0) [0|4294967295] "" Vector__XXX
 SG_ UIS_cameraFrontPipeline m407 : 32|32@1+ (1,0) [0|4294967295] "" Vector__XXX
 SG_ UIS_cameraFrontPacketState m408 : 32|32@1+ (1,0) [0|4294967295] "" Vector__XXX
 SG_ UIS_cameraBackupStreamQuality m409 : 32|32@1+ (1,0) [0|4294967295] "" Vector__XXX
 SG_ UIS_cameraBackupStreamMissing m410 : 32|32@1+ (1,0) [0|1] "" Vector__XXX
 SG_ UIS_cameraBackupRenderState m411 : 32|32@1+ (1,0) [0|4294967295] "" Vector__XXX
 SG_ UIS_cameraBackupPopup m412 : 32|32@1+ (1,0) [0|1] "" Vector__XXX
 SG_ UIS_cameraBackupPipeline m413 : 32|32@1+ (1,0) [0|4294967295] "" Vector__XXX
 SG_ UIS_cameraBackupPacketState m414 : 32|32@1+ (1,0) [0|4294967295] "" Vector__XXX
 SG_ UIS_cameraBackupMaxFrametime m415 : 32|32@1+ (1,0) [0|4294967295] "" Vector__XXX
 SG_ UIS_pmSuspendHookIndex m416 : 32|32@1+ (1,0) [0|4294967295] "" Vector__XXX
 SG_ UIS_cameraBackupLateFrames m417 : 32|32@1+ (1,0) [0|4294967295] "" Vector__XXX
 SG_ UIS_cameraBackupFramerate m418 : 32|32@1+ (1,0) [0|4294967295] "" Vector__XXX
 SG_ UIS_camBackupDecodeMinFrametime m419 : 32|32@1+ (1,0) [0|4294967295] "" Vector__XXX
 SG_ UIS_camBackupDecodeMaxFrametime m420 : 32|32@1+ (1,0) [0|4294967295] "" Vector__XXX
 SG_ UIS_camBackupDecodeFramecount m421 : 32|32@1+ (1,0) [0|4294967295] "" Vector__XXX
 SG_ UIS_camBackupDecodeAvgFrametime m422 : 32|32@1+ (1,0) [0|4294967295] "" Vector__XXX
 SG_ UIS_bootCount m423 : 32|32@1+ (1,0) [0|4294967295] "" Vector__XXX
 SG_ UIS_boardTemperature m424 : 32|32@1+ (1,0) [0|4294967295] "" Vector__XXX
 SG_ UIS_bluetoothState m425 : 32|32@1+ (1,0) [0|4294967295] "" Vector__XXX
 SG_ UIS_bluetoothStackState m426 : 32|32@1+ (1,0) [0|4294967295] "" Vector__XXX
 SG_ UIS_bluetoothStackRearState m427 : 32|32@1+ (1,0) [0|4294967295] "" Vector__XXX
 SG_ UIS_bluetoothPairResult m428 : 32|32@1+ (1,0) [0|4294967295] "" Vector__XXX
 SG_ UIS_bluetoothMemUsage m429 : 32|32@1+ (1,0) [0|4294967295] "" Vector__XXX
 SG_ UIS_bluetoothConnectionState m430 : 32|32@1+ (1,0) [0|4294967295] "" Vector__XXX
 SG_ UIS_bluetoothCPUUsage m431 : 32|32@1+ (1,0) [0|4294967295] "" Vector__XXX
 SG_ UIS_bluetoothAutoconnectAttempts m432 : 32|32@1+ (1,0) [0|4294967295] "" Vector__XXX
 SG_ UIS_bluetoothAutoconnectActive m433 : 32|32@1+ (1,0) [0|4294967295] "" Vector__XXX
 SG_ UIS_bluetoothAutoConnectionState m434 : 32|32@1+ (1,0) [0|4294967295] "" Vector__XXX
 SG_ UIS_bifrostOdinEngineUp m435 : 32|32@1+ (1,0) [0|4294967295] "" Vector__XXX
 SG_ UIS_bifrostOdinEngineRequests m436 : 32|32@1+ (1,0) [0|4294967295] "" Vector__XXX
 SG_ UIS_bifrostMemUsage m437 : 32|32@1+ (1,0) [0|4294967295] "" Vector__XXX
 SG_ UIS_bifrostCPUUsage m438 : 32|32@1+ (1,0) [0|4294967295] "" Vector__XXX
 SG_ UIS_backlightUserRequest m439 : 32|32@1+ (1,0) [0|4294967295] "" Vector__XXX
 SG_ UIS_audioVolumeLevel m440 : 32|32@1+ (1,0) [0|4294967295] "" Vector__XXX
 SG_ UIS_audioType m441 : 32|32@1+ (1,0) [0|4294967295] "" Vector__XXX
 SG_ UIS_audioState m442 : 32|32@1+ (1,0) [0|4294967295] "" Vector__XXX
 SG_ UIS_audioSource m443 : 32|32@1+ (1,0) [0|4294967295] "" Vector__XXX
 SG_ UIS_audioPWSGain m444 : 32|32@1+ (1,0) [0|4294967295] "" Vector__XXX
 SG_ UIS_audioMediaPlaying m445 : 32|32@1+ (1,0) [0|4294967295] "" Vector__XXX
 SG_ UIS_audioMediaBrowsing m446 : 32|32@1+ (1,0) [0|4294967295] "" Vector__XXX
 SG_ UIS_audioA2BRediscoveryCount m447 : 32|32@1+ (1,0) [0|4294967295] "" Vector__XXX
 SG_ UIS_apeHardwareMinorVersion m448 : 32|32@1+ (1,0) [0|4294967295] "" Vector__XXX
 SG_ UIS_amdSocPkgPower m449 : 32|32@1+ (1,0) [0|4294967295] "" Vector__XXX
 SG_ UIS_activeAppView m450 : 32|32@1+ (1,0) [0|4294967295] "" Vector__XXX
 SG_ UIS_CamViewerServiceEnabled m451 : 32|32@1+ (1,0) [0|4294967295] "" Vector__XXX

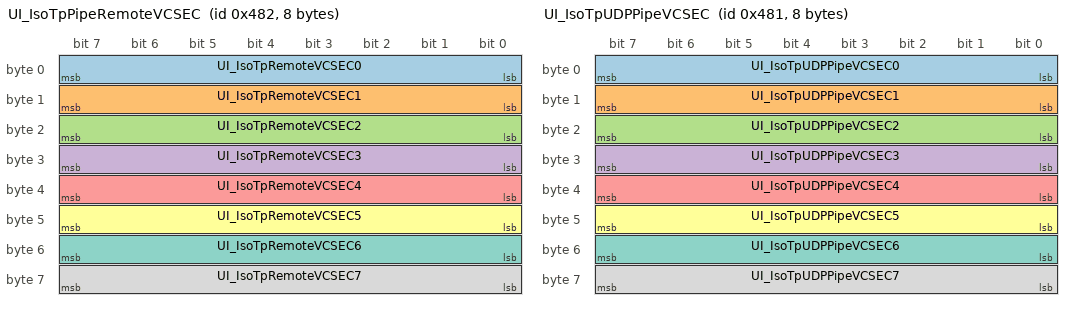
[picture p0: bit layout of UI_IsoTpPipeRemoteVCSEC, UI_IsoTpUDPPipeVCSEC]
BO_ 1154 UI_IsoTpPipeRemoteVCSEC: 8 UI
 SG_ UI_IsoTpRemoteVCSEC0 : 0|8@1+ (1,0) [0|255] "" Vector__XXX
 SG_ UI_IsoTpRemoteVCSEC1 : 8|8@1+ (1,0) [0|255] "" Vector__XXX
 SG_ UI_IsoTpRemoteVCSEC2 : 16|8@1+ (1,0) [0|255] "" Vector__XXX
 SG_ UI_IsoTpRemoteVCSEC3 : 24|8@1+ (1,0) [0|255] "" Vector__XXX
 SG_ UI_IsoTpRemoteVCSEC4 : 32|8@1+ (1,0) [0|255] "" Vector__XXX
 SG_ UI_IsoTpRemoteVCSEC5 : 40|8@1+ (1,0) [0|255] "" Vector__XXX
 SG_ UI_IsoTpRemoteVCSEC6 : 48|8@1+ (1,0) [0|255] "" Vector__XXX
 SG_ UI_IsoTpRemoteVCSEC7 : 56|8@1+ (1,0) [0|255] "" Vector__XXX

BO_ 1153 UI_IsoTpUDPPipeVCSEC: 8 UI
 SG_ UI_IsoTpUDPPipeVCSEC0 : 0|8@1+ (1,0) [0|255] "" Vector__XXX
 SG_ UI_IsoTpUDPPipeVCSEC1 : 8|8@1+ (1,0) [0|255] "" Vector__XXX
 SG_ UI_IsoTpUDPPipeVCSEC2 : 16|8@1+ (1,0) [0|255] "" Vector__XXX
 SG_ UI_IsoTpUDPPipeVCSEC3 : 24|8@1+ (1,0) [0|255] "" Vector__XXX
 SG_ UI_IsoTpUDPPipeVCSEC4 : 32|8@1+ (1,0) [0|255] "" Vector__XXX
 SG_ UI_IsoTpUDPPipeVCSEC5 : 40|8@1+ (1,0) [0|255] "" Vector__XXX
 SG_ UI_IsoTpUDPPipeVCSEC6 : 48|8@1+ (1,0) [0|255] "" Vector__XXX
 SG_ UI_IsoTpUDPPipeVCSEC7 : 56|8@1+ (1,0) [0|255] "" Vector__XXX

BO_ 979 UI_airbagCutoffStatus: 1 UI
 SG_ UI_airbagCutoffSwState : 0|2@1+ (1,0) [0|3] "" Vector__XXX
 SG_ UI_warningIndicatorStatus : 2|2@1+ (1,0) [0|2] "" Vector__XXX

BO_ 1523 UI_alertLog: 8 UI
 SG_ UI_alertID M : 0|9@1+ (1,0) [0|511] "" Vector__XXX
 SG_ UI_alertState : 15|1@1+ (1,0) [0|1] "" Vector__XXX
 SG_ UI_a006_remoteServiceAlertCode m6 : 16|32@1+ (1,0) [0|4294967295] "" Vector__XXX
 SG_ UI_a009_squashfsDevice m9 : 16|4@1+ (1,0) [0|15] "" Vector__XXX
 SG_ UI_a009_squashfsErrorCount m9 : 24|16@1+ (1,0) [0|65535] "" Vector__XXX
 SG_ UI_a034_BackupCamera m34 : 16|1@1+ (1,0) [0|1] "" Vector__XXX
 SG_ UI_a034_Tuner m34 : 17|1@1+ (1,0) [0|1] "" Vector__XXX
 SG_ UI_a034_Bluetooth m34 : 18|1@1+ (1,0) [0|1] "" Vector__XXX
 SG_ UI_a034_WiFi m34 : 19|1@1+ (1,0) [0|1] "" Vector__XXX
 SG_ UI_a034_Cellular m34 : 20|1@1+ (1,0) [0|1] "" Vector__XXX
 SG_ UI_a034_TouchScreen m34 : 21|1@1+ (1,0) [0|1] "" Vector__XXX
 SG_ UI_a034_Display m34 : 22|1@1+ (1,0) [0|1] "" Vector__XXX
 SG_ UI_a034_Audio m34 : 23|1@1+ (1,0) [0|1] "" Vector__XXX
 SG_ UI_a034_FatalWakeup m34 : 24|1@1+ (1,0) [0|1] "" Vector__XXX
 SG_ UI_a034_UnknownWakeupError m34 : 25|1@1+ (1,0) [0|1] "" Vector__XXX
 SG_ UI_a036_audioWatchdogReason m36 : 16|8@1+ (1,0) [0|255] "" Vector__XXX
 SG_ UI_a045_ManualECallDisabled m45 : 16|1@1+ (1,0) [0|1] "" Vector__XXX
 SG_ UI_a045_ManualECallButtonDisconn m45 : 17|1@1+ (1,0) [0|1] "" Vector__XXX
 SG_ UI_a045_CellAntenna m45 : 18|1@1+ (1,0) [0|1] "" Vector__XXX
 SG_ UI_a045_GPSAntenna m45 : 19|1@1+ (1,0) [0|1] "" Vector__XXX
 SG_ UI_a045_ECallSpeaker m45 : 20|1@1+ (1,0) [0|1] "" Vector__XXX
 SG_ UI_a045_ECallMic m45 : 21|1@1+ (1,0) [0|1] "" Vector__XXX
 SG_ UI_a045_SIMTest m45 : 22|1@1+ (1,0) [0|1] "" Vector__XXX
 SG_ UI_a045_ENSTest m45 : 23|1@1+ (1,0) [0|1] "" Vector__XXX
 SG_ UI_a045_CellularTest m45 : 24|1@1+ (1,0) [0|1] "" Vector__XXX
 SG_ UI_a045_ModemFirmwareTest m45 : 25|1@1+ (1,0) [0|1] "" Vector__XXX
 SG_ UI_a052_kernelPanicSignature m52 : 16|32@1+ (1,0) [0|4294967295] "" Vector__XXX
 SG_ UI_a065_wifiRecoveryReason m65 : 16|8@1+ (1,0) [0|255] "" Vector__XXX
 SG_ UI_a066_ProcessId m66 : 16|8@1+ (1,0) [0|255] "" Vector__XXX
 SG_ UI_a066_RingBlitter m66 : 24|1@1+ (1,0) [0|1] "" Vector__XXX
 SG_ UI_a066_RingBSD m66 : 25|1@1+ (1,0) [0|1] "" Vector__XXX
 SG_ UI_a066_RingRender m66 : 26|1@1+ (1,0) [0|1] "" Vector__XXX
 SG_ UI_a066_RingVideoEnhancement m66 : 27|1@1+ (1,0) [0|1] "" Vector__XXX
 SG_ UI_a066_EnginesHung m66 : 28|1@1+ (1,0) [0|1] "" Vector__XXX
 SG_ UI_a066_EnginesWedged m66 : 29|1@1+ (1,0) [0|1] "" Vector__XXX
 SG_ UI_a066_RecoveryFailed m66 : 30|1@1+ (1,0) [0|1] "" Vector__XXX
 SG_ UI_a066_FlipDoneTimedOut m66 : 31|1@1+ (1,0) [0|1] "" Vector__XXX
 SG_ UI_a066_TimedoutSoftRecovered m66 : 32|1@1+ (1,0) [0|1] "" Vector__XXX
 SG_ UI_a087_BmpResetType m87 : 16|3@1+ (1,0) [0|7] "" Vector__XXX
 SG_ UI_a096_PipelineId m96 : 16|8@1+ (1,0) [0|255] "" Vector__XXX
 SG_ UI_a096_UdpTimeout m96 : 24|1@1+ (1,0) [0|1] "" Vector__XXX
 SG_ UI_a096_PipelineWarning m96 : 25|1@1+ (1,0) [0|1] "" Vector__XXX
 SG_ UI_a096_PipelineError m96 : 26|1@1+ (1,0) [0|1] "" Vector__XXX
 SG_ UI_a096_UnexpectedExit m96 : 27|1@1+ (1,0) [0|1] "" Vector__XXX
 SG_ UI_a096_PipelineOverrun m96 : 28|1@1+ (1,0) [0|1] "" Vector__XXX
 SG_ UI_a096_MissingXWindow m96 : 29|1@1+ (1,0) [0|1] "" Vector__XXX
 SG_ UI_a099_emmcStatusRegister m99 : 16|32@1+ (1,0) [0|4294967295] "" Vector__XXX
 SG_ UI_a100_emmcFTLCounter m100 : 16|32@1+ (1,0) [0|4294967295] "" Vector__XXX
 SG_ UI_a131_DisplayPortFailureType m131 : 16|1@1+ (1,0) [0|1] "" Vector__XXX
 SG_ UI_a147_whichASIL m147 : 16|1@1+ (1,0) [0|1] "" Vector__XXX
 SG_ UI_a147_errorCode m147 : 24|8@1+ (1,0) [0|255] "" Vector__XXX
 SG_ UI_a148_sleepType m148 : 16|3@1+ (1,0) [0|7] "" Vector__XXX
 SG_ UI_a148_lastFailedDev m148 : 24|32@1+ (1,0) [0|4294967295] "" Vector__XXX
 SG_ UI_a148_lastFailedPmSuspendDev m148 : 56|5@1+ (1,0) [0|31] "" Vector__XXX
 SG_ UI_a149_displayType m149 : 16|8@1+ (1,0) [0|255] "" Vector__XXX
 SG_ UI_a149_displaySeat m149 : 24|4@1+ (1,0) [0|15] "" Vector__XXX
 SG_ UI_a149_errorCode m149 : 32|32@1+ (1,0) [0|4294967295] "" Vector__XXX
 SG_ UI_a151_cpuAmbientDeltaTemp m151 : 16|16@1+ (1,0) [0|65535] "" Vector__XXX
 SG_ UI_a151_socThermalResistance m151 : 32|16@1+ (1,0) [0|65535] "" Vector__XXX
 SG_ UI_a153_processName m153 : 16|8@1+ (1,0) [0|255] "" Vector__XXX
 SG_ UI_a153_restartReason m153 : 24|8@1+ (1,0) [0|255] "" Vector__XXX
 SG_ UI_a158_UsbDeviceMountErrorCode m158 : 16|32@1+ (1,0) [0|4294967295] "" Vector__XXX
 SG_ UI_a160_WatchdogStarving m160 : 16|1@1+ (1,0) [0|1] "" Vector__XXX
 SG_ UI_a160_MemoryPressureCritical m160 : 17|1@1+ (1,0) [0|1] "" Vector__XXX
 SG_ UI_a160_MemoryUsageCritical m160 : 18|1@1+ (1,0) [0|1] "" Vector__XXX
 SG_ UI_a160_SlabUsageCritical m160 : 19|1@1+ (1,0) [0|1] "" Vector__XXX
 SG_ UI_a165_fsCorruptedDevice m165 : 16|4@1+ (1,0) [0|15] "" Vector__XXX
 SG_ UI_a166_fsErrorDevice m166 : 16|4@1+ (1,0) [0|15] "" Vector__XXX
 SG_ UI_a167_processId m167 : 16|5@1+ (1,0) [0|31] "" Vector__XXX
 SG_ UI_a173_errorCode m173 : 16|2@1+ (1,0) [0|3] "" Vector__XXX
 SG_ UI_a173_hookIndex m173 : 18|4@1+ (1,0) [0|15] "" Vector__XXX
 SG_ UI_a173_lastFailedPmSuspendDev m173 : 24|5@1+ (1,0) [0|31] "" Vector__XXX
 SG_ UI_a176_PrimaryAntenna m176 : 16|3@1+ (1,0) [0|7] "" Vector__XXX
 SG_ UI_a176_SecondaryAntenna m176 : 19|3@1+ (1,0) [0|7] "" Vector__XXX
 SG_ UI_a176_TertiaryAntenna m176 : 24|3@1+ (1,0) [0|7] "" Vector__XXX
 SG_ UI_a177_errorCode m177 : 16|5@1+ (1,0) [0|31] "" Vector__XXX
 SG_ UI_a177_errorSource m177 : 24|6@1+ (1,0) [0|63] "" Vector__XXX
 SG_ UI_a178_irqNumber m178 : 16|16@1+ (1,0) [0|65535] "" Vector__XXX
 SG_ UI_a178_irqSourceId m178 : 32|32@1+ (1,0) [0|4294967295] "" Vector__XXX
 SG_ UI_a192_AudioRebootState m192 : 16|4@1+ (1,0) [0|15] "" Vector__XXX
 SG_ UI_a204_ModemSleepFailureReason m204 : 16|3@1+ (1,0) [0|7] "" Vector__XXX
 SG_ UI_a208_mqttClientDisconnectReas m208 : 16|8@1+ (1,0) [0|255] "" Vector__XXX
 SG_ UI_a214_errorCode m214 : 16|8@1+ (1,0) [0|255] "" Vector__XXX
 SG_ UI_a214_lastFailedDev m214 : 24|32@1+ (1,0) [0|4294967295] "" Vector__XXX
 SG_ UI_a214_lastFailedPmSuspendDev m214 : 56|5@1+ (1,0) [0|31] "" Vector__XXX
 SG_ UI_a216_circuitProblem m216 : 16|8@1+ (1,0) [0|255] "" Vector__XXX
 SG_ UI_a216_circuitNode m216 : 24|8@1+ (1,0) [0|255] "" Vector__XXX
 SG_ UI_a217_cgroupName m217 : 16|5@1+ (1,0) [0|31] "" Vector__XXX
 SG_ UI_a220_errorCode m220 : 16|4@1+ (1,0) [0|15] "" Vector__XXX
 SG_ UI_a221_errorCode m221 : 16|4@1+ (1,0) [0|15] "" Vector__XXX
 SG_ UI_a221_networkErrorCode m221 : 20|9@1+ (1,0) [0|511] "" Vector__XXX
 SG_ UI_a221_serverErrorCode m221 : 32|16@1+ (1,0) [0|65535] "" Vector__XXX
 SG_ UI_a222_errorCode m222 : 16|4@1+ (1,0) [0|15] "" Vector__XXX
 SG_ UI_a223_database m223 : 16|6@1+ (1,0) [0|63] "" Vector__XXX
 SG_ UI_a226_count m226 : 16|16@1+ (1,0) [0|65535] "" Vector__XXX
 SG_ UI_a229_errorCode m229 : 16|8@1+ (1,0) [0|255] "" Vector__XXX
 SG_ UI_a231_sleepType m231 : 16|3@1+ (1,0) [0|7] "" Vector__XXX
 SG_ UI_a232_processExited m232 : 16|8@1+ (1,0) [0|255] "" Vector__XXX
 SG_ UI_a232_processSignal m232 : 24|8@1+ (1,0) [0|255] "" Vector__XXX
 SG_ UI_a240_ethErrorType m240 : 16|8@1+ (1,0) [0|255] "" Vector__XXX
 SG_ UI_a241_errorCode m241 : 16|8@1+ (1,0) [0|255] "" Vector__XXX
 SG_ UI_a242_CenterDispFaultInjected m242 : 16|1@1+ (1,0) [0|1] "" Vector__XXX
 SG_ UI_a242_ConnectivityFaultInjecte m242 : 17|1@1+ (1,0) [0|1] "" Vector__XXX
 SG_ UI_a242_ConnectivityHWFaultInjec m242 : 18|1@1+ (1,0) [0|1] "" Vector__XXX
 SG_ UI_a242_QtCarFaultInjected m242 : 19|1@1+ (1,0) [0|1] "" Vector__XXX
 SG_ UI_a242_RearDispFaultInjected m242 : 20|1@1+ (1,0) [0|1] "" Vector__XXX
 SG_ UI_a242_QtCarRearFaultInjected m242 : 21|1@1+ (1,0) [0|1] "" Vector__XXX
 SG_ UI_a242_DASServerFaultInjected m242 : 22|1@1+ (1,0) [0|1] "" Vector__XXX
 SG_ UI_a242_CenterDispStatusFaultInj m242 : 23|1@1+ (1,0) [0|1] "" Vector__XXX
 SG_ UI_a242_FaultCode m242 : 24|16@1+ (1,0) [0|65535] "" Vector__XXX
 SG_ UI_a247_displayType m247 : 16|8@1+ (1,0) [0|255] "" Vector__XXX
 SG_ UI_a247_displaySeat m247 : 24|4@1+ (1,0) [0|15] "" Vector__XXX
 SG_ UI_a253_correctionCode m253 : 16|48@1+ (1,0) [0|281474976710655] "" Vector__XXX
 SG_ UI_a257_ModemRebootReason m257 : 16|3@1+ (1,0) [0|7] "" Vector__XXX
 SG_ UI_a257_ModemRebootEthPresent m257 : 19|1@1+ (1,0) [0|1] "" Vector__XXX
 SG_ UI_a261_bluetoothStackPanicReaso m261 : 16|6@1+ (1,0) [0|63] "" Vector__XXX
 SG_ UI_a263_hermesUploadFailure m263 : 16|1@1+ (1,0) [0|1] "" Vector__XXX
 SG_ UI_a263_udsUploadFailure m263 : 17|1@1+ (1,0) [0|1] "" Vector__XXX
 SG_ UI_a274_hintCardType m274 : 16|4@1+ (1,0) [0|15] "" Vector__XXX
 SG_ UI_a274_hintCardDismissOutcome m274 : 20|3@1+ (1,0) [0|7] "" Vector__XXX

BO_ 291 UI_alertMatrix1: 8 UI
 SG_ UI_a001_DriverDoorOpen : 0|1@1+ (1,0) [0|1] "" Vector__XXX
 SG_ UI_a002_DoorOpen : 1|1@1+ (1,0) [0|1] "" Vector__XXX
 SG_ UI_a003_TrunkOpen : 2|1@1+ (1,0) [0|1] "" Vector__XXX
 SG_ UI_a004_FrunkOpen : 3|1@1+ (1,0) [0|1] "" Vector__XXX
 SG_ UI_a005_HeadlightsOnDoorOpen : 4|1@1+ (1,0) [0|1] "" Vector__XXX
 SG_ UI_a006_RemoteServiceAlert : 5|1@1+ (1,0) [0|1] "" Vector__XXX
 SG_ UI_a007_SoftPackConfigMismatch : 6|1@1+ (1,0) [0|1] "" Vector__XXX
 SG_ UI_a008_TouchScreenError : 7|1@1+ (1,0) [0|1] "" Vector__XXX
 SG_ UI_a009_SquashfsError : 8|1@1+ (1,0) [0|1] "" Vector__XXX
 SG_ UI_a010_MapsMissing : 9|1@1+ (1,0) [0|1] "" Vector__XXX
 SG_ UI_a011_IncorrectMap : 10|1@1+ (1,0) [0|1] "" Vector__XXX
 SG_ UI_a012_NotOnPrivateProperty : 11|1@1+ (1,0) [0|1] "" Vector__XXX
 SG_ UI_a013_TPMSHardWarning : 12|1@1+ (1,0) [0|1] "" Vector__XXX
 SG_ UI_a014_TPMSSoftWarning : 13|1@1+ (1,0) [0|1] "" Vector__XXX
 SG_ UI_a015_TPMSOverPressureWarning : 14|1@1+ (1,0) [0|1] "" Vector__XXX
 SG_ UI_a016_TPMSTemperatureWarning : 15|1@1+ (1,0) [0|1] "" Vector__XXX
 SG_ UI_a017_TPMSSystemFault : 16|1@1+ (1,0) [0|1] "" Vector__XXX
 SG_ UI_a018_SlipStartOn : 17|1@1+ (1,0) [0|1] "" Vector__XXX
 SG_ UI_a019_ParkBrakeFault : 18|1@1+ (1,0) [0|1] "" Vector__XXX
 SG_ UI_a020_SteeringReduced : 19|1@1+ (1,0) [0|1] "" Vector__XXX
 SG_ UI_a021_RearSeatbeltUnbuckled : 20|1@1+ (1,0) [0|1] "" Vector__XXX
 SG_ UI_a022_ApeFusesEtc : 21|1@1+ (1,0) [0|1] "" Vector__XXX
 SG_ UI_a023_CellInternetCheckFailed : 22|1@1+ (1,0) [0|1] "" Vector__XXX
 SG_ UI_a024_WifiInternetCheckFailed : 23|1@1+ (1,0) [0|1] "" Vector__XXX
 SG_ UI_a026_ModemResetLoopDetected : 25|1@1+ (1,0) [0|1] "" Vector__XXX
 SG_ UI_a027_AutoSteerMIA : 26|1@1+ (1,0) [0|1] "" Vector__XXX
 SG_ UI_a028_FrontTrunkPopupClosed : 27|1@1+ (1,0) [0|1] "" Vector__XXX
 SG_ UI_a029_ModemMIA : 28|1@1+ (1,0) [0|1] "" Vector__XXX
 SG_ UI_a030_ModemVMCrash : 29|1@1+ (1,0) [0|1] "" Vector__XXX
 SG_ UI_a031_BrakeFluidLow : 30|1@1+ (1,0) [0|1] "" Vector__XXX
 SG_ UI_a032_CellModemRecoveryResets : 31|1@1+ (1,0) [0|1] "" Vector__XXX
 SG_ UI_a033_ApTrialExpired : 32|1@1+ (1,0) [0|1] "" Vector__XXX
 SG_ UI_a034_WakeupProblem : 33|1@1+ (1,0) [0|1] "" Vector__XXX
 SG_ UI_a035_FrunkOpenChime : 34|1@1+ (1,0) [0|1] "" Vector__XXX
 SG_ UI_a036_AudioWatchdog : 35|1@1+ (1,0) [0|1] "" Vector__XXX
 SG_ UI_a037_AudioWatchdogXrunStormEr : 36|1@1+ (1,0) [0|1] "" Vector__XXX
 SG_ UI_a038_AudioWatchdogA2bI2cLocku : 37|1@1+ (1,0) [0|1] "" Vector__XXX
 SG_ UI_a039_AudioA2bNeedRediscovery : 38|1@1+ (1,0) [0|1] "" Vector__XXX
 SG_ UI_a040_HomelinkTransmit : 39|1@1+ (1,0) [0|1] "" Vector__XXX
 SG_ UI_a041_AudioDmesgXrun : 40|1@1+ (1,0) [0|1] "" Vector__XXX
 SG_ UI_a042_AudioDmesgRtThrottling : 41|1@1+ (1,0) [0|1] "" Vector__XXX
 SG_ UI_a043_InvalidMapDataOverride : 42|1@1+ (1,0) [0|1] "" Vector__XXX
 SG_ UI_a044_AudioDmesgDspException : 43|1@1+ (1,0) [0|1] "" Vector__XXX
 SG_ UI_a045_ECallSystemCheckFailed : 44|1@1+ (1,0) [0|1] "" Vector__XXX
 SG_ UI_a046_BackupCameraStreamError : 45|1@1+ (1,0) [0|1] "" Vector__XXX
 SG_ UI_a047_CellRoamingDisallowed : 46|1@1+ (1,0) [0|1] "" Vector__XXX
 SG_ UI_a048_AudioPremiumAmpCheckFail : 47|1@1+ (1,0) [0|1] "" Vector__XXX
 SG_ UI_a049_BrakeShiftRequired : 48|1@1+ (1,0) [0|1] "" Vector__XXX
 SG_ UI_a050_BackupCameraIPUTimeout : 49|1@1+ (1,0) [0|1] "" Vector__XXX
 SG_ UI_a051_BackupCameraFrameTimeout : 50|1@1+ (1,0) [0|1] "" Vector__XXX
 SG_ UI_a052_KernelPanicReported : 51|1@1+ (1,0) [0|1] "" Vector__XXX
 SG_ UI_a053_QtCarExitError : 52|1@1+ (1,0) [0|1] "" Vector__XXX
 SG_ UI_a054_AudioBoostPowerBad : 53|1@1+ (1,0) [0|1] "" Vector__XXX
 SG_ UI_a055_ManualECallDisabled : 54|1@1+ (1,0) [0|1] "" Vector__XXX
 SG_ UI_a056_ManualECallButtonDisconn : 55|1@1+ (1,0) [0|1] "" Vector__XXX
 SG_ UI_a057_CellAntennaDisconnected : 56|1@1+ (1,0) [0|1] "" Vector__XXX
 SG_ UI_a058_GPSAntennaDisconnected : 57|1@1+ (1,0) [0|1] "" Vector__XXX
 SG_ UI_a059_ECallSpeakerDisconnected : 58|1@1+ (1,0) [0|1] "" Vector__XXX
 SG_ UI_a060_ECallMicDisconnected : 59|1@1+ (1,0) [0|1] "" Vector__XXX
 SG_ UI_a061_SIMTestFailed : 60|1@1+ (1,0) [0|1] "" Vector__XXX
 SG_ UI_a062_ENSTestFailed : 61|1@1+ (1,0) [0|1] "" Vector__XXX
 SG_ UI_a063_CellularTestFailed : 62|1@1+ (1,0) [0|1] "" Vector__XXX
 SG_ UI_a064_ModemFirmwareTestFailed : 63|1@1+ (1,0) [0|1] "" Vector__XXX

BO_ 292 UI_alertMatrix2: 8 UI
 SG_ UI_a065_WiFiRecoveryReset : 0|1@1+ (1,0) [0|1] "" Vector__XXX
 SG_ UI_a066_GpuHangDetected : 1|1@1+ (1,0) [0|1] "" Vector__XXX
 SG_ UI_a067_WarnOnI915 : 2|1@1+ (1,0) [0|1] "" Vector__XXX
 SG_ UI_a068_VideoUnexpectedExit : 3|1@1+ (1,0) [0|1] "" Vector__XXX
 SG_ UI_a069_VideoUDPTimeout : 4|1@1+ (1,0) [0|1] "" Vector__XXX
 SG_ UI_a070_VideoPipelineWarning : 5|1@1+ (1,0) [0|1] "" Vector__XXX
 SG_ UI_a071_VideoPipelineError : 6|1@1+ (1,0) [0|1] "" Vector__XXX
 SG_ UI_a072_ECallAnalogMicFailed : 7|1@1+ (1,0) [0|1] "" Vector__XXX
 SG_ UI_a073_ECallDigitalMicFailed : 8|1@1+ (1,0) [0|1] "" Vector__XXX
 SG_ UI_a074_EMMCHangDetected : 9|1@1+ (1,0) [0|1] "" Vector__XXX
 SG_ UI_a075_BackupCameraInitError : 10|1@1+ (1,0) [0|1] "" Vector__XXX
 SG_ UI_a076_NumFalseManualECalls : 11|1@1+ (1,0) [0|1] "" Vector__XXX
 SG_ UI_a077_AudioA2bMicChannelSwap : 12|1@1+ (1,0) [0|1] "" Vector__XXX
 SG_ UI_a078_DashcamUsbDriveUnmountab : 13|1@1+ (1,0) [0|1] "" Vector__XXX
 SG_ UI_a079_DashcamUsbDriveFull : 14|1@1+ (1,0) [0|1] "" Vector__XXX
 SG_ UI_a080_DashcamUsbDriveSlow : 15|1@1+ (1,0) [0|1] "" Vector__XXX
 SG_ UI_a081_CellModemSearchExpired : 16|1@1+ (1,0) [0|1] "" Vector__XXX
 SG_ UI_a082_NumModemRebootStuckInECa : 17|1@1+ (1,0) [0|1] "" Vector__XXX
 SG_ UI_a083_ECallProxyWatchdogTrigge : 18|1@1+ (1,0) [0|1] "" Vector__XXX
 SG_ UI_a084_SerializerError : 19|1@1+ (1,0) [0|1] "" Vector__XXX
 SG_ UI_a085_DeserializerError : 20|1@1+ (1,0) [0|1] "" Vector__XXX
 SG_ UI_a086_TouchEnumerationError : 21|1@1+ (1,0) [0|1] "" Vector__XXX
 SG_ UI_a087_BmpReset : 22|1@1+ (1,0) [0|1] "" Vector__XXX
 SG_ UI_a088_CellRemovableSimMissing : 23|1@1+ (1,0) [0|1] "" Vector__XXX
 SG_ UI_a089_RadioReset : 24|1@1+ (1,0) [0|1] "" Vector__XXX
 SG_ UI_a090_RadioPingFailError : 25|1@1+ (1,0) [0|1] "" Vector__XXX
 SG_ UI_a091_VehicleLinkStall : 26|1@1+ (1,0) [0|1] "" Vector__XXX
 SG_ UI_a092_updateStarted : 27|1@1+ (1,0) [0|1] "" Vector__XXX
 SG_ UI_a093_updateEnded : 28|1@1+ (1,0) [0|1] "" Vector__XXX
 SG_ UI_a094_ModemPowerOnFailure : 29|1@1+ (1,0) [0|1] "" Vector__XXX
 SG_ UI_a095_CidStorageRunningLow : 30|1@1+ (1,0) [0|1] "" Vector__XXX
 SG_ UI_a096_VideodPipelineIssueDetec : 31|1@1+ (1,0) [0|1] "" Vector__XXX
 SG_ UI_a097_AudiodRestarted : 32|1@1+ (1,0) [0|1] "" Vector__XXX
 SG_ UI_a098_DiskCheckFailure : 33|1@1+ (1,0) [0|1] "" Vector__XXX
 SG_ UI_a099_eMMCStatusError : 34|1@1+ (1,0) [0|1] "" Vector__XXX
 SG_ UI_a100_eMMCFTLError : 35|1@1+ (1,0) [0|1] "" Vector__XXX
 SG_ UI_a101_wifiStackProblem : 36|1@1+ (1,0) [0|1] "" Vector__XXX
 SG_ UI_a102_A2bDiscoveryFailed : 37|1@1+ (1,0) [0|1] "" Vector__XXX
 SG_ UI_a103_UsbHubNotEnumerating : 38|1@1+ (1,0) [0|1] "" Vector__XXX
 SG_ UI_a104_DashcamUsbDriveMissing : 39|1@1+ (1,0) [0|1] "" Vector__XXX
 SG_ UI_a105_firmwareReinstallRequest : 40|1@1+ (1,0) [0|1] "" Vector__XXX
 SG_ UI_a106_rebootBackstopTriggered : 41|1@1+ (1,0) [0|1] "" Vector__XXX
 SG_ UI_a107_DashcamUsbDriveTooBigFor : 42|1@1+ (1,0) [0|1] "" Vector__XXX
 SG_ UI_a108_DashcamUsbDriveGettingFu : 43|1@1+ (1,0) [0|1] "" Vector__XXX
 SG_ UI_a109_DashcamUsbDriveTooSmall : 44|1@1+ (1,0) [0|1] "" Vector__XXX
 SG_ UI_a110_DashcamUsbDriveCorrupt : 45|1@1+ (1,0) [0|1] "" Vector__XXX
 SG_ UI_a111_DashcamUsbDriveNotSuperS : 46|1@1+ (1,0) [0|1] "" Vector__XXX
 SG_ UI_a112_badUSBDevice : 47|1@1+ (1,0) [0|1] "" Vector__XXX
 SG_ UI_a113_DashcamHasOnboardSentryC : 48|1@1+ (1,0) [0|1] "" Vector__XXX
 SG_ UI_a114_drivingVisualizationDegr : 49|1@1+ (1,0) [0|1] "" Vector__XXX
 SG_ UI_a115_IrisEDLMode : 50|1@1+ (1,0) [0|1] "" Vector__XXX
 SG_ UI_a116_UncorrectableMemoryError : 51|1@1+ (1,0) [0|1] "" Vector__XXX
 SG_ UI_a117_VehicleSelfTestRunning : 52|1@1+ (1,0) [0|1] "" Vector__XXX
 SG_ UI_a118_NVMeReset : 53|1@1+ (1,0) [0|1] "" Vector__XXX
 SG_ UI_a119_nvmeBlockDeviceMissing : 54|1@1+ (1,0) [0|1] "" Vector__XXX
 SG_ UI_a120_nvmePCIeLinkErrorDetecte : 55|1@1+ (1,0) [0|1] "" Vector__XXX
 SG_ UI_a121_nvmeSmartLogCritical : 56|1@1+ (1,0) [0|1] "" Vector__XXX
 SG_ UI_a122_AMDI2C0LostArbitration : 57|1@1+ (1,0) [0|1] "" Vector__XXX
 SG_ UI_a123_AMDI2C1LostArbitration : 58|1@1+ (1,0) [0|1] "" Vector__XXX
 SG_ UI_a124_AMDI2C0TxRxAborted : 59|1@1+ (1,0) [0|1] "" Vector__XXX
 SG_ UI_a125_AMDI2C1TxRxAborted : 60|1@1+ (1,0) [0|1] "" Vector__XXX
 SG_ UI_a126_UsbErrorDriveCorrupt : 61|1@1+ (1,0) [0|1] "" Vector__XXX
 SG_ UI_a128_dgpuNotDetected : 63|1@1+ (1,0) [0|1] "" Vector__XXX

BO_TX_BU_ 1056 : UIS;
BO_TX_BU_ 1154 : UI;
BO_TX_BU_ 1153 : UI;
BO_TX_BU_ 979 : UI;
BO_TX_BU_ 1523 : UI;
BO_TX_BU_ 291 : UI;
BO_TX_BU_ 292 : UI;
CM_ BO_ 1056 "UIS ECU message: log";
CM_ SG_ 1056 UIS_logMux "UIS ECU: log mux";
CM_ SG_ 1056 UIS_zramWriteTicks "UIS ECU: zram write ticks";
CM_ SG_ 1056 UIS_zramWriteIO "UIS ECU: zram write IO";
CM_ SG_ 1056 UIS_zramReadTicks "UIS ECU: zram read ticks";
CM_ SG_ 1056 UIS_zramReadIO "UIS ECU: zram read IO";
CM_ SG_ 1056 UIS_zramOriginalSize "UIS ECU: zram original size";
CM_ SG_ 1056 UIS_zramNotifyFree "UIS ECU: zram notify free";
CM_ SG_ 1056 UIS_zramInvalidIO "UIS ECU: zram invalid IO";
CM_ SG_ 1056 UIS_zramFailedWrites "UIS ECU: zram failed writes";
CM_ SG_ 1056 UIS_zramFailedReads "UIS ECU: zram failed reads";
CM_ SG_ 1056 UIS_zramCompressionRatio "UIS ECU: zram compression ratio";
CM_ SG_ 1056 UIS_zramCompressedSize "UIS ECU: zram compressed size";
CM_ SG_ 1056 UIS_wifiTemperature "Current temperature reported for wifi";
CM_ SG_ 1056 UIS_wifiStackState "WiFi stack state description";
CM_ SG_ 1056 UIS_wifiStackReady "UIS ECU: wifi stack ready";
CM_ SG_ 1056 UIS_wifiBars "WiFi bars for connected network";
CM_ SG_ 1056 UIS_wifiAutoJoinLowRSSI "Indicates an attempt to auto-join a known network with low Received Signal Strength Indicator (RSSI).";
CM_ SG_ 1056 UIS_webbrowserMemUsage "UIS ECU: webbrowser mem usage";
CM_ SG_ 1056 UIS_webbrowserCPUUsage "UIS ECU: webbrowser CPU usage";
CM_ SG_ 1056 UIS_vmtouchMemUsage "UIS ECU: vmtouch mem usage";
CM_ SG_ 1056 UIS_vmtouchCPUUsage "UIS ECU: vmtouch CPU usage";
CM_ SG_ 1056 UIS_videodMemUsage "UIS ECU: videod mem usage";
CM_ SG_ 1056 UIS_videodCPUUsage "UIS ECU: videod CPU usage";
CM_ SG_ 1056 UIS_vehicleMemUsage "UIS ECU: vehicle mem usage";
CM_ SG_ 1056 UIS_vehicleCPUUsage "UIS ECU: vehicle CPU usage";
CM_ SG_ 1056 UIS_valhallaserverMemUsage "UIS ECU: valhallaserver mem usage";
CM_ SG_ 1056 UIS_valhallaserverCPUUsage "UIS ECU: valhallaserver CPU usage";
CM_ SG_ 1056 UIS_valetMode "UI Valet Mode state";
CM_ SG_ 1056 UIS_uiQtCarUptime "Touchscreen UI software uptime";
CM_ SG_ 1056 UIS_uiQtCarSwapUsage "Signal reported by UIS ECU";
CM_ SG_ 1056 UIS_uiMeanFPS "UI mean frames per second over a 60s period";
CM_ SG_ 1056 UIS_uiMaxFrametime "UIS ECU: ui max frametime";
CM_ SG_ 1056 UIS_uiFrametimeGearShiftPToR "UIS ECU: ui frametime gear shift p to r";
CM_ SG_ 1056 UIS_uiFrametimeGearShiftDToR "UIS ECU: ui frametime gear shift d to r";
CM_ SG_ 1056 UIS_uiFramesOver200Ms "UIS ECU: ui frames over200 ms";
CM_ SG_ 1056 UIS_uiFramesOver100Ms "UIS ECU: ui frames over100 ms";
CM_ SG_ 1056 UIS_tunerVoltageUBatt "UIS ECU: tuner voltage u batt";
CM_ SG_ 1056 UIS_tunerVoltageOperation "Radio tuner operating voltage (mV)";
CM_ SG_ 1056 UIS_tunerVoltageMQS "UIS ECU: tuner voltage MQS";
CM_ SG_ 1056 UIS_tunerVoltageAntenna2 "Radio tuner voltage (mV) for antenna 2";
CM_ SG_ 1056 UIS_tunerVoltageAntenna1 "Radio tuner voltage (mV) for antenna 1";
CM_ SG_ 1056 UIS_tunerVoltage3V3 "UIS ECU: tuner voltage3 V3";
CM_ SG_ 1056 UIS_tunerVoltage1V8 "UIS ECU: tuner voltage1 V8";
CM_ SG_ 1056 UIS_tunerTemperatureFahrenheit "UIS ECU: tuner temperature fahrenheit";
CM_ SG_ 1056 UIS_tunerTemperatureCelsius "UIS ECU: tuner temperature celsius";
CM_ SG_ 1056 UIS_tunerCurrentAntenna2 "Radio tuner current (mA) for antenna 2";
CM_ SG_ 1056 UIS_tunerCurrentAntenna1 "Radio tuner current (mA) for antenna 1";
CM_ SG_ 1056 UIS_touchEventsAggCount "UIS ECU: touch events agg count";
CM_ SG_ 1056 UIS_tmserverMemUsage "UIS ECU: tmserver mem usage";
CM_ SG_ 1056 UIS_tmserverCPUUsage "UIS ECU: tmserver CPU usage";
CM_ SG_ 1056 UIS_thermalResistance "UIS ECU: thermal resistance";
CM_ SG_ 1056 UIS_thermalProfile "UIS ECU: thermal profile; raw 0 = signal not available (SNA)";
CM_ SG_ 1056 UIS_testDriveMode "UIS ECU: test drive mode";
CM_ SG_ 1056 UIS_teslachromiumMemUsage "UIS ECU: teslachromium mem usage";
CM_ SG_ 1056 UIS_teslachromiumCPUUsage "UIS ECU: teslachromium CPU usage";
CM_ SG_ 1056 UIS_teslaMediaCacheSize "UIS ECU: tesla media cache size";
CM_ SG_ 1056 UIS_teslaMediaCacheCost "UIS ECU: tesla media cache cost";
CM_ SG_ 1056 UIS_teleopStreamXrunCount "UIS ECU: teleop stream xrun count";
CM_ SG_ 1056 UIS_teleopPhoneCallActive "UIS ECU: teleop phone call active";
CM_ SG_ 1056 UIS_teleopPacketDrops "UIS ECU: teleop packet drops";
CM_ SG_ 1056 UIS_teleopMinPacketDelta "UIS ECU: teleop min packet delta";
CM_ SG_ 1056 UIS_teleopMaxPacketDelta "UIS ECU: teleop max packet delta";
CM_ SG_ 1056 UIS_teleopAvgPacketDelta "UIS ECU: teleop avg packet delta";
CM_ SG_ 1056 UIS_tegraModemManState "Tegra Cellular Modem Manager state";
CM_ SG_ 1056 UIS_systemWakeTime "Length of time since wake or boot if UI has not slept (seconds)";
CM_ SG_ 1056 UIS_systemUptime "Reports the system uptime duration.";
CM_ SG_ 1056 UIS_systemMemSwapUsage "UIS ECU: system mem swap usage";
CM_ SG_ 1056 UIS_suspensionGeofence "Status of suspension geofence add or remove";
CM_ SG_ 1056 UIS_superchargePaymentNeeded "Reports that Supercharging payment is needed.";
CM_ SG_ 1056 UIS_sudokuMemUsage "UIS ECU: sudoku mem usage";
CM_ SG_ 1056 UIS_sudokuCPUUsage "UIS ECU: sudoku CPU usage";
CM_ SG_ 1056 UIS_spotifyserverMemUsage "UIS ECU: spotifyserver mem usage";
CM_ SG_ 1056 UIS_spotifyserverCPUUsage "UIS ECU: spotifyserver CPU usage";
CM_ SG_ 1056 UIS_speechrecoMemUsage "UIS ECU: speechreco mem usage";
CM_ SG_ 1056 UIS_speechrecoCPUUsage "UIS ECU: speechreco CPU usage";
CM_ SG_ 1056 UIS_solitaireMemUsage "UIS ECU: solitaire mem usage";
CM_ SG_ 1056 UIS_solitaireCPUUsage "UIS ECU: solitaire CPU usage";
CM_ SG_ 1056 UIS_softwareUpdateState "UIS ECU: software update state";
CM_ SG_ 1056 UIS_softwareUpdatePrimDownload "UIS ECU: software update prim download";
CM_ SG_ 1056 UIS_softwareInstallPopupStatus "UIS ECU: software install popup status";
CM_ SG_ 1056 UIS_sleepType "Reports the system sleep type.";
CM_ SG_ 1056 UIS_sleepTime "Reports the system sleep duration.";
CM_ SG_ 1056 UIS_sleepState "Reports the system sleep state.";
CM_ SG_ 1056 UIS_sleepCount "UIS ECU: sleep count";
CM_ SG_ 1056 UIS_slackerLoginResult "Reports Slacker Media login events";
CM_ SG_ 1056 UIS_settingsAutoTurnSignal "UIS ECU: settings auto turn signal";
CM_ SG_ 1056 UIS_serviceModePlus "Signal reported by UIS ECU";
CM_ SG_ 1056 UIS_serviceMode "Signal reported by UIS ECU";
CM_ SG_ 1056 UIS_serverMemUsage "UIS ECU: server mem usage";
CM_ SG_ 1056 UIS_serverCPUUsage "UIS ECU: server CPU usage";
CM_ SG_ 1056 UIS_sentryState "Sentry Mode state";
CM_ SG_ 1056 UIS_sentryNeedsNap "Sentry Mode sleep indicator, max uptime reached";
CM_ SG_ 1056 UIS_sentryIncidentCount "Sentry Mode incident count, initializes to 0";
CM_ SG_ 1056 UIS_scheduledChargingMode "Scheduled charging mode";
CM_ SG_ 1056 UIS_scheduleChargeStartTime "Reports the scheduled charging start date time in MMDDHHMM format.";
CM_ SG_ 1056 UIS_scheduleChargeEndTime "Reports the scheduled charging end date time in MMDDHHMM format.";
CM_ SG_ 1056 UIS_robotaxiModeActive "UIS ECU: robotaxi mode active";
CM_ SG_ 1056 UIS_remoteRequestType "Reports the signed remote request type sent to vehicle, excluding closures and start requests.";
CM_ SG_ 1056 UIS_releasenotesMemUsage "UIS ECU: releasenotes mem usage";
CM_ SG_ 1056 UIS_releasenotesCPUUsage "UIS ECU: releasenotes CPU usage";
CM_ SG_ 1056 UIS_rearDisplayUserPresent "Indicates if a user is present in the rear seat based on seat occupancy and rear display usage";
CM_ SG_ 1056 UIS_rearDisplayState "Reports the rear display state.";
CM_ SG_ 1056 UIS_radioserveMemUsage "UIS ECU: radioserve mem usage";
CM_ SG_ 1056 UIS_radioserveCPUUsage "UIS ECU: radioserve CPU usage";
CM_ SG_ 1056 UIS_qtcarMemUsage "Signal reported by UIS ECU";
CM_ SG_ 1056 UIS_qtcarCPUUsage "Signal reported by UIS ECU";
CM_ SG_ 1056 UIS_psiMemSome "UIS ECU: psi mem some";
CM_ SG_ 1056 UIS_psiMemFull "UIS ECU: psi mem full";
CM_ SG_ 1056 UIS_psiIOSome "UIS ECU: psi IO some";
CM_ SG_ 1056 UIS_psiIOFull "UIS ECU: psi IO full";
CM_ SG_ 1056 UIS_psiCpuSome "UIS ECU: psi cpu some";
CM_ SG_ 1056 UIS_powerManagerState "UI power manager state signal; raw 18 = signal not available (SNA)";
CM_ SG_ 1056 UIS_polytopiax8664MemUsage "polytopiax8664's Resident Memory usage in MB";
CM_ SG_ 1056 UIS_polytopiax8664CPUUsage "polytopiax8664's CPU usage in CPU usage %";
CM_ SG_ 1056 UIS_odinStatusCmdResult "Signal reported by UIS ECU";
CM_ SG_ 1056 UIS_odinStatusCmdDurationMs "Signal reported by UIS ECU";
CM_ SG_ 1056 UIS_odinProcessState "Signal reported by UIS ECU";
CM_ SG_ 1056 UIS_odinPeriodicTaskState "Signal reported by UIS ECU";
CM_ SG_ 1056 UIS_odinOrchestratorStartCount "Signal reported by UIS ECU";
CM_ SG_ 1056 UIS_odinOrchestratorFailCount "Signal reported by UIS ECU";
CM_ SG_ 1056 UIS_odinNetworkStartCount "Signal reported by UIS ECU";
CM_ SG_ 1056 UIS_odinNetworkFailCount "Signal reported by UIS ECU";
CM_ SG_ 1056 UIS_odinMemUsage "Signal reported by UIS ECU";
CM_ SG_ 1056 UIS_odinListTasksCmdResult "Signal reported by UIS ECU";
CM_ SG_ 1056 UIS_odinListTasksCmdDurationMs "Signal reported by UIS ECU";
CM_ SG_ 1056 UIS_odinHrlUploadLimits "Signal reported by UIS ECU";
CM_ SG_ 1056 UIS_odinHrlLogUploadState "Signal reported by UIS ECU";
CM_ SG_ 1056 UIS_odinHermesConnectionState "Signal reported by UIS ECU";
CM_ SG_ 1056 UIS_odinGatewayConnectionState "Signal reported by UIS ECU";
CM_ SG_ 1056 UIS_odinFileSystemState "Signal reported by UIS ECU";
CM_ SG_ 1056 UIS_odinEcuLogUploadState "Signal reported by UIS ECU";
CM_ SG_ 1056 UIS_odinEcuLogForceTriggerUpload "Signal reported by UIS ECU";
CM_ SG_ 1056 UIS_odinCPUUsage "Signal reported by UIS ECU";
CM_ SG_ 1056 UIS_odinAuthFailCount "Signal reported by UIS ECU";
CM_ SG_ 1056 UIS_odinAuthCount "Signal reported by UIS ECU";
CM_ SG_ 1056 UIS_nvmeTemperature "UIS ECU: nvme temperature";
CM_ SG_ 1056 UIS_nvmePercentLifetimeUsed "UIS ECU: nvme percent lifetime used";
CM_ SG_ 1056 UIS_nvmeDataUnitsWritten100mb "UIS ECU: nvme data units written100mb";
CM_ SG_ 1056 UIS_numUncorrMemErrorsECC "UIS ECU: num uncorr mem errors ECC";
CM_ SG_ 1056 UIS_numCorrMemErrorsECC "UIS ECU: num corr mem errors ECC";
CM_ SG_ 1056 UIS_nuanceserverMemUsage "UIS ECU: nuanceserver mem usage";
CM_ SG_ 1056 UIS_nuanceserverCPUUsage "UIS ECU: nuanceserver CPU usage";
CM_ SG_ 1056 UIS_netWifiTxRate "UIS ECU: net wifi tx rate";
CM_ SG_ 1056 UIS_netWifiTxCount "UIS ECU: net wifi tx count";
CM_ SG_ 1056 UIS_netWifiRxRate "UIS ECU: net wifi rx rate";
CM_ SG_ 1056 UIS_netWifiRxCount "UIS ECU: net wifi rx count";
CM_ SG_ 1056 UIS_netEthTxRate "UIS ECU: net eth tx rate";
CM_ SG_ 1056 UIS_netEthTxCount "UIS ECU: net eth tx count";
CM_ SG_ 1056 UIS_netEthRxRate "UIS ECU: net eth rx rate";
CM_ SG_ 1056 UIS_netEthRxErrorRate "UIS ECU: net eth rx error rate";
CM_ SG_ 1056 UIS_netEthRxErrorCount "UIS ECU: net eth rx error count";
CM_ SG_ 1056 UIS_netEthRxDroppedRate "UIS ECU: net eth rx dropped rate";
CM_ SG_ 1056 UIS_netEthRxDroppedCount "UIS ECU: net eth rx dropped count";
CM_ SG_ 1056 UIS_netEthRxCount "UIS ECU: net eth rx count";
CM_ SG_ 1056 UIS_netCellTxRate "UIS ECU: net cell tx rate";
CM_ SG_ 1056 UIS_netCellTxCount "UIS ECU: net cell tx count";
CM_ SG_ 1056 UIS_netCellRxRate "UIS ECU: net cell rx rate";
CM_ SG_ 1056 UIS_netCellRxCount "UIS ECU: net cell rx count";
CM_ SG_ 1056 UIS_navServiceError "Reports the value of the navigation service error.";
CM_ SG_ 1056 UIS_navAudioVolume "Navigation audio volume level";
CM_ SG_ 1056 UIS_muteNavVolume "Mute state of the navigation audio";
CM_ SG_ 1056 UIS_mounterdState "UIS ECU: mounterd state";
CM_ SG_ 1056 UIS_mounterdMountCountTotal "UIS ECU: mounterd mount count total";
CM_ SG_ 1056 UIS_mounterdFrontHubDisconnected "UIS ECU: mounterd front hub disconnected";
CM_ SG_ 1056 UIS_mounterdFrontHubConnected "UIS ECU: mounterd front hub connected";
CM_ SG_ 1056 UIS_mounterdFilesystemCountFat32 "UIS ECU: mounterd filesystem count fat32";
CM_ SG_ 1056 UIS_mounterdFilesystemCountExt4 "UIS ECU: mounterd filesystem count ext4";
CM_ SG_ 1056 UIS_mounterdFilesystemCountExt3 "UIS ECU: mounterd filesystem count ext3";
CM_ SG_ 1056 UIS_mounterdFilesystemCountExfat "UIS ECU: mounterd filesystem count exfat";
CM_ SG_ 1056 UIS_mounterdEncryptionCapacityGB "UIS ECU: mounterd encryption capacity GB";
CM_ SG_ 1056 UIS_mounterdDeviceCount "UIS ECU: mounterd device count";
CM_ SG_ 1056 UIS_mounterdDashcamCapacityGB "UIS ECU: mounterd dashcam capacity GB";
CM_ SG_ 1056 UIS_modemECallppAvail "Reports whether eCall++ is enabled and is running on Telematics Control Unit (TCU).";
CM_ SG_ 1056 UIS_modemBusyActive "Reports whether the modem busy logic is requested to be active on the modem application processor.";
CM_ SG_ 1056 UIS_mirrorGeofenceActive "Folding mirror geofence active status";
CM_ SG_ 1056 UIS_mediaserveMemUsage "UIS ECU: mediaserve mem usage";
CM_ SG_ 1056 UIS_mediaserveCPUUsage "UIS ECU: mediaserve CPU usage";
CM_ SG_ 1056 UIS_mediaPlaybackStatus "Media Current Playback Status";
CM_ SG_ 1056 UIS_mediaNeedAuthToken "Indicates whether the media system needs a new authentication token.";
CM_ SG_ 1056 UIS_mediaImageCacheSize "UIS ECU: media image cache size";
CM_ SG_ 1056 UIS_mediaImageCacheCost "UIS ECU: media image cache cost";
CM_ SG_ 1056 UIS_limex8664MemUsage "UIS ECU: limex8664 mem usage";
CM_ SG_ 1056 UIS_limex8664CPUUsage "UIS ECU: limex8664 CPU usage";
CM_ SG_ 1056 UIS_inSuperchargerGeofence "Vehicle inside Supercharger Geofence";
CM_ SG_ 1056 UIS_igpuTemperature "UIS ECU: igpu temperature";
CM_ SG_ 1056 UIS_homelinkState "State of Homelink sate machine";
CM_ SG_ 1056 UIS_hicarServiceState "UIS ECU: hicar service state";
CM_ SG_ 1056 UIS_hicarEventCode "UIS ECU: hicar event code";
CM_ SG_ 1056 UIS_hicarErrorCode "UIS ECU: hicar error code";
CM_ SG_ 1056 UIS_hicarDataReceiveType "UIS ECU: hicar data receive type";
CM_ SG_ 1056 UIS_hicarConnectionState "UIS ECU: hicar connection state";
CM_ SG_ 1056 UIS_hicarCallState "UIS ECU: hicar call state";
CM_ SG_ 1056 UIS_hicarAudioTeardownState "UIS ECU: hicar audio teardown state";
CM_ SG_ 1056 UIS_hicarAudioSetupState "UIS ECU: hicar audio setup state";
CM_ SG_ 1056 UIS_hermesdynamicMemUsage "UIS ECU: hermesdynamic mem usage";
CM_ SG_ 1056 UIS_hermesdynamicCPUUsage "UIS ECU: hermesdynamic CPU usage";
CM_ SG_ 1056 UIS_hermesclientMemUsage "UIS ECU: hermesclient mem usage";
CM_ SG_ 1056 UIS_hermesclientCPUUsage "UIS ECU: hermesclient CPU usage";
CM_ SG_ 1056 UIS_headsetPairResult "Bluetooth headset pairing result";
CM_ SG_ 1056 UIS_headsetConnectionState "Bluetooth headset connection state";
CM_ SG_ 1056 UIS_gtwSocUartTxStatTimeouts "UIS ECU: gtw soc uart tx stat timeouts";
CM_ SG_ 1056 UIS_gtwSocUartTxStatPackets "UIS ECU: gtw soc uart tx stat packets";
CM_ SG_ 1056 UIS_gtwSocUartTxStatNacks "UIS ECU: gtw soc uart tx stat nacks";
CM_ SG_ 1056 UIS_gtwSocUartTxStatBadTooBig "UIS ECU: gtw soc uart tx stat bad too big";
CM_ SG_ 1056 UIS_gtwSocUartTxStatAnsMismatch "UIS ECU: gtw soc uart tx stat ans mismatch";
CM_ SG_ 1056 UIS_gtwSocUartRxStatValidPackets "UIS ECU: gtw soc uart rx stat valid packets";
CM_ SG_ 1056 UIS_gtwSocUartRxStatUnhandled "UIS ECU: gtw soc uart rx stat unhandled";
CM_ SG_ 1056 UIS_gtwSocUartRxStatMsgErr "UIS ECU: gtw soc uart rx stat msg err";
CM_ SG_ 1056 UIS_gtwSocUartRxStatHeartbeats "UIS ECU: gtw soc uart rx stat heartbeats";
CM_ SG_ 1056 UIS_gtwSocUartRxStatHandleErr "UIS ECU: gtw soc uart rx stat handle err";
CM_ SG_ 1056 UIS_gtwSocUartRxStatBadTooSmall "UIS ECU: gtw soc uart rx stat bad too small";
CM_ SG_ 1056 UIS_gtwSocUartRxStatBadTooBig "UIS ECU: gtw soc uart rx stat bad too big";
CM_ SG_ 1056 UIS_gtwSocUartRxStatBadChecksum "UIS ECU: gtw soc uart rx stat bad checksum";
CM_ SG_ 1056 UIS_gpsmanagerMemUsage "gpsManager's Resident Memory usage in MB";
CM_ SG_ 1056 UIS_gpsmanagerCPUUsage "gpsManager's CPU usage in CPU usage %";
CM_ SG_ 1056 UIS_godot_TIME_PROCESS "UIS ECU: godot TIME PROCESS";
CM_ SG_ 1056 UIS_godot_TIME_FPS "UIS ECU: godot TIME FPS";
CM_ SG_ 1056 UIS_godot_MEMORY_STATIC "UIS ECU: godot MEMORY STATIC";
CM_ SG_ 1056 UIS_godot_MEMORY_DYNAMIC "UIS ECU: godot MEMORY DYNAMIC";
CM_ SG_ 1056 UIS_godotMemUsage "UIS ECU: godot mem usage";
CM_ SG_ 1056 UIS_godotCPUUsage "UIS ECU: godot CPU usage";
CM_ SG_ 1056 UIS_firmwareReleaseScope "UIS ECU: firmware release scope";
CM_ SG_ 1056 UIS_featureSuperchargingEnabled "Reports the Supercharging enabled feature status.";
CM_ SG_ 1056 UIS_estimatedOccupancyCount "UIS ECU: estimated occupancy count";
CM_ SG_ 1056 UIS_embeddedGameState "UIS ECU: embedded game state";
CM_ SG_ 1056 UIS_embeddedGameName "UIS ECU: embedded game name";
CM_ SG_ 1056 UIS_dynamicTriggersTelemetryServ "UIS ECU: dynamic triggers telemetry service state";
CM_ SG_ 1056 UIS_dynamicTriggersOutputManager "UIS ECU: dynamic triggers output manager service state";
CM_ SG_ 1056 UIS_dynamicTriggersHRLServiceSta "UIS ECU: dynamic triggers HRL service state";
CM_ SG_ 1056 UIS_dynamicTriggersCampaignState "UIS ECU: dynamic triggers campaign state; raw 0 = signal not available (SNA)";
CM_ SG_ 1056 UIS_dumTclipUploadState "UIS ECU: dum tclip upload state";
CM_ SG_ 1056 UIS_dumTclipUploadActive "UIS ECU: dum tclip upload active";
CM_ SG_ 1056 UIS_dumTclipTransferCount "UIS ECU: dum tclip transfer count";
CM_ SG_ 1056 UIS_dumTclipSuccessfulUploadCoun "UIS ECU: dum tclip successful upload count";
CM_ SG_ 1056 UIS_dumTclipClipCount "UIS ECU: dum tclip clip count";
CM_ SG_ 1056 UIS_dmRearTouchDeviceExists "Reports status of rear display power state.";
CM_ SG_ 1056 UIS_dmRearPowerState "Logs rear display power state status";
CM_ SG_ 1056 UIS_dmRearLinkCheckOk "Logs whether rear display-hardware-init was successful";
CM_ SG_ 1056 UIS_dmRearEnabled "Rear display is enabled";
CM_ SG_ 1056 UIS_dmRearConnected "Rear display is connected";
CM_ SG_ 1056 UIS_dmRearBacklightPowerLevel "UIS ECU: dm rear backlight power level";
CM_ SG_ 1056 UIS_dmRearBacklightNits "UIS ECU: dm rear backlight nits";
CM_ SG_ 1056 UIS_dmRearBacklightFault "UIS ECU: dm rear backlight fault";
CM_ SG_ 1056 UIS_dmRearBacklightDutyCycle "Logs rear backlight duty cycle status";
CM_ SG_ 1056 UIS_dmRearBacklightDevExists "Logs whether rear backlight device exists and was successfully detected";
CM_ SG_ 1056 UIS_dmRearAsilStatusMsb "UIS ECU: dm rear asil status msb";
CM_ SG_ 1056 UIS_dmRearAsilStatusLsb "UIS ECU: dm rear asil status lsb";
CM_ SG_ 1056 UIS_dmIcuTouchIrqCount "UIS ECU: dm icu touch irq count";
CM_ SG_ 1056 UIS_dmIcuPowerState "Logs cluster display power state status";
CM_ SG_ 1056 UIS_dmIcuLinkCheckOk "Logs whether cluster display-hardware-init was successful";
CM_ SG_ 1056 UIS_dmIcuEnabled "Cluster display is enabled";
CM_ SG_ 1056 UIS_dmIcuConnected "Cluster display is connected";
CM_ SG_ 1056 UIS_dmIcuBacklightPowerLevel "UIS ECU: dm icu backlight power level";
CM_ SG_ 1056 UIS_dmIcuBacklightNits "UIS ECU: dm icu backlight nits";
CM_ SG_ 1056 UIS_dmIcuBacklightFault "UIS ECU: dm icu backlight fault";
CM_ SG_ 1056 UIS_dmIcuBacklightDutyCycle "Logs cluster backlight duty cycle status";
CM_ SG_ 1056 UIS_dmIcuBacklightDevExists "Logs whether cluster backlight device exists and was successfully detected";
CM_ SG_ 1056 UIS_dmIcuAsilShortFlag "UIS ECU: dm icu asil short flag";
CM_ SG_ 1056 UIS_dmIcuAsilResumeFlag "UIS ECU: dm icu asil resume flag";
CM_ SG_ 1056 UIS_dmIcuAsilOpenFlag "UIS ECU: dm icu asil open flag";
CM_ SG_ 1056 UIS_dmIcuAsilFirmwareStatus "UIS ECU: dm icu asil firmware status";
CM_ SG_ 1056 UIS_dmGatewayLinkWedged "Indicates whether the center display gateway link is stuck.";
CM_ SG_ 1056 UIS_dmCenterTouchIrqCount "UIS ECU: dm center touch irq count";
CM_ SG_ 1056 UIS_dmCenterTouchDeviceExists "Detects whether the center display touch input device is present.";
CM_ SG_ 1056 UIS_dmCenterSOsdVideoCrcData "UIS ECU: dm center s osd video crc data";
CM_ SG_ 1056 UIS_dmCenterSOsdExactCrcCheck "UIS ECU: dm center s osd exact crc check";
CM_ SG_ 1056 UIS_dmCenterPowerState "Logs center display power state status";
CM_ SG_ 1056 UIS_dmCenterOsdDisplayedState "Reports the center display On-Screen Display (OSD) shown state.";
CM_ SG_ 1056 UIS_dmCenterOsdDayNightState "UIS ECU: dm center osd day night state";
CM_ SG_ 1056 UIS_dmCenterModeSettingStatus "UIS ECU: dm center mode setting status";
CM_ SG_ 1056 UIS_dmCenterMOsdVideoCrcData "UIS ECU: dm center m osd video crc data";
CM_ SG_ 1056 UIS_dmCenterMOsdExactCrcCheck "UIS ECU: dm center m osd exact crc check";
CM_ SG_ 1056 UIS_dmCenterLinkCheckOk "Logs whether center display-hardware-init was successful";
CM_ SG_ 1056 UIS_dmCenterEnabled "Center display is enabled";
CM_ SG_ 1056 UIS_dmCenterConnected "Center display is connected";
CM_ SG_ 1056 UIS_dmCenterBacklightPowerLevel "Logs backlight power level for center display";
CM_ SG_ 1056 UIS_dmCenterBacklightNits "UIS ECU: dm center backlight nits";
CM_ SG_ 1056 UIS_dmCenterBacklightFault "UIS ECU: dm center backlight fault";
CM_ SG_ 1056 UIS_dmCenterBacklightDutyCycle "Logs center backlight duty cycle status";
CM_ SG_ 1056 UIS_dmCenterBacklightDevExists "Logs whether center backlight device exists and was successfully detected";
CM_ SG_ 1056 UIS_dmCenterBacklightControlDefe "Indicates whether the center display backlight request to the gateway was deferred to the User Datagram Protocol Application Programming Interface (UDP API) or converged within 1 second.";
CM_ SG_ 1056 UIS_dmCenterAsilShortFlag "UIS ECU: dm center asil short flag";
CM_ SG_ 1056 UIS_dmCenterAsilResumeFlag "UIS ECU: dm center asil resume flag";
CM_ SG_ 1056 UIS_dmCenterAsilOpenFlag "UIS ECU: dm center asil open flag";
CM_ SG_ 1056 UIS_dmCenterAsilFirmwareStatus "UIS ECU: dm center asil firmware status";
CM_ SG_ 1056 UIS_dmCenterAsilCalibrationSync "UIS ECU: dm center asil calibration sync";
CM_ SG_ 1056 UIS_dgpuTemperature "Current temperature reported for dgpu";
CM_ SG_ 1056 UIS_developerMode "UIS ECU: developer mode";
CM_ SG_ 1056 UIS_dashcamviewerMemUsage "dashcamViewer's Resident Memory usage in MB";
CM_ SG_ 1056 UIS_dashcamviewerCPUUsage "dashcamViewer's CPU usage in CPU usage %";
CM_ SG_ 1056 UIS_dashcamTransferTimeMs "UIS ECU: dashcam transfer time ms";
CM_ SG_ 1056 UIS_dashcamTransferSizeMB "UIS ECU: dashcam transfer size MB";
CM_ SG_ 1056 UIS_dashcamTransferRateMBps "UIS ECU: dashcam transfer rate m bps";
CM_ SG_ 1056 UIS_dashcamTransferFileCount "UIS ECU: dashcam transfer file count";
CM_ SG_ 1056 UIS_dashcamTransferCount "UIS ECU: dashcam transfer count";
CM_ SG_ 1056 UIS_dashcamStorageState "Internal state of the dashcam storage";
CM_ SG_ 1056 UIS_dashcamStorageSentryMB "Dashcam USB storage used by Sentry Clips in MB";
CM_ SG_ 1056 UIS_dashcamStorageSavedMB "Dashcam USB storage used by Saved Clips in MB";
CM_ SG_ 1056 UIS_dashcamStorageRecentMB "Dashcam USB storage used by Recent Clips in MB";
CM_ SG_ 1056 UIS_dashcamStorageAvailableMB "Dashcam USB storage that is Available in MB";
CM_ SG_ 1056 UIS_dashcamState "Internal state for the dashcam state machine";
CM_ SG_ 1056 UIS_dashcamSavedToSentryCount "UIS ECU: dashcam saved to sentry count";
CM_ SG_ 1056 UIS_dashcamSavedToSavedCount "UIS ECU: dashcam saved to saved count";
CM_ SG_ 1056 UIS_dashcamSavedToOnboardCount "UIS ECU: dashcam saved to onboard count";
CM_ SG_ 1056 UIS_dashcamOnboardTransferCount "UIS ECU: dashcam onboard transfer count";
CM_ SG_ 1056 UIS_dashcamOnboardSavePressCount "UIS ECU: dashcam onboard save press count";
CM_ SG_ 1056 UIS_dashcamOnboardMB "UIS ECU: dashcam onboard MB";
CM_ SG_ 1056 UIS_dashcamOnboardAvailableMB "UIS ECU: dashcam onboard available MB";
CM_ SG_ 1056 UIS_dasAutonomyControlMessageMia "UIS ECU: das autonomy control message mia in driverless takeover";
CM_ SG_ 1056 UIS_cpuTemperature "Current temperature reported for cpu";
CM_ SG_ 1056 UIS_connectedToInternet "UIS ECU: connected to internet";
CM_ SG_ 1056 UIS_compositorRenderMinRenderTim "UIS ECU: compositor render min render time";
CM_ SG_ 1056 UIS_compositorRenderMinFrameTime "UIS ECU: compositor render min frame time";
CM_ SG_ 1056 UIS_compositorRenderMaxRenderTim "UIS ECU: compositor render max render time";
CM_ SG_ 1056 UIS_compositorRenderMaxFrameTime "UIS ECU: compositor render max frame time";
CM_ SG_ 1056 UIS_compositorRenderGpuPercentag "UIS ECU: compositor render gpu percentage";
CM_ SG_ 1056 UIS_compositorRenderFrameRate "UIS ECU: compositor render frame rate";
CM_ SG_ 1056 UIS_compositorRenderFrameCount "UIS ECU: compositor render frame count";
CM_ SG_ 1056 UIS_compositorRenderAvgRenderTim "UIS ECU: compositor render avg render time";
CM_ SG_ 1056 UIS_compositorFrameMonitorState "UIS ECU: compositor frame monitor state";
CM_ SG_ 1056 UIS_cobaltlinuxMemUsage "UIS ECU: cobaltlinux mem usage";
CM_ SG_ 1056 UIS_cobaltlinuxCPUUsage "UIS ECU: cobaltlinux CPU usage";
CM_ SG_ 1056 UIS_clusterMemUsage "cluster's Resident Memory usage in MB";
CM_ SG_ 1056 UIS_clusterMeanFPS "UIS ECU: cluster mean FPS";
CM_ SG_ 1056 UIS_clusterMaxFrametime "UIS ECU: cluster max frametime";
CM_ SG_ 1056 UIS_clusterFramesOver200Ms "UIS ECU: cluster frames over200 ms";
CM_ SG_ 1056 UIS_clusterFramesOver100Ms "UIS ECU: cluster frames over100 ms";
CM_ SG_ 1056 UIS_clusterDisplayState "Reports the instrument cluster display state.";
CM_ SG_ 1056 UIS_clusterCPUUsage "cluster's CPU usage in CPU usage %";
CM_ SG_ 1056 UIS_chromiumadapterMemUsage "UIS ECU: chromiumadapter mem usage";
CM_ SG_ 1056 UIS_chromiumadapterCPUUsage "UIS ECU: chromiumadapter CPU usage";
CM_ SG_ 1056 UIS_chargeOnSolarNoChargeReason "Reason car is not charging on solar";
CM_ SG_ 1056 UIS_chargeLocationId "Privacy-respecting region identifier for charge location (1.1km accuracy, requires user consent via Software > Controls > Data Sharing)";
CM_ SG_ 1056 UIS_ceruleanx8664MemUsage "UIS ECU: ceruleanx8664 mem usage";
CM_ SG_ 1056 UIS_ceruleanx8664CPUUsage "UIS ECU: ceruleanx8664 CPU usage";
CM_ SG_ 1056 UIS_centerDisplayState "Reports the center display state.";
CM_ SG_ 1056 UIS_centerDisplayEvent "Reports the events that cause center display state transitions.";
CM_ SG_ 1056 UIS_centerDispAsilB_msb "UIS ECU: center disp asil b msb";
CM_ SG_ 1056 UIS_centerDispAsilB_lsb "UIS ECU: center disp asil b lsb";
CM_ SG_ 1056 UIS_centerDispAsilA_msb "UIS ECU: center disp asil a msb";
CM_ SG_ 1056 UIS_centerDispAsilA_lsb "UIS ECU: center disp asil a lsb";
CM_ SG_ 1056 UIS_cellularLinkManagerState "CellLink Manager state";
CM_ SG_ 1056 UIS_cellularConnectivityStatus "Reports the abstracted status of overall connectivity on the infotainment.";
CM_ SG_ 1056 UIS_carAssistState "Car Assist State";
CM_ SG_ 1056 UIS_carAssistSessionCount "Car Assist Session Count";
CM_ SG_ 1056 UIS_carAssistMicMuted "Reports whether the car assist microphone is muted or unmuted.";
CM_ SG_ 1056 UIS_carAssistMicAlsaRms "Monitors the car assist microphone Advanced Linux Sound Architecture (ALSA) Root Mean Squared (RMS).";
CM_ SG_ 1056 UIS_carAssistErrorCode "Car Assist Error Code";
CM_ SG_ 1056 UIS_cameraSelectableRenderState "Indicates if the touchscreen UI software has composited at least one new selectable stream camera window frame.";
CM_ SG_ 1056 UIS_cameraSelectablePipeline "Reports the selectable stream camera pipeline state.";
CM_ SG_ 1056 UIS_cameraSelectablePacketState "Indicates if Infotainment detects selectable stream camera UDP packets from Autopilot.";
CM_ SG_ 1056 UIS_cameraRearViewStreamMissing "UIS ECU: camera rear view stream missing";
CM_ SG_ 1056 UIS_cameraRearViewRenderState "Indicates if the touchscreen UI software has composited at least one new rear view camera window frame.";
CM_ SG_ 1056 UIS_cameraRearViewPopup "UIS ECU: camera rear view popup";
CM_ SG_ 1056 UIS_cameraRearViewPipeline "UIS ECU: camera rear view pipeline";
CM_ SG_ 1056 UIS_cameraRearViewPacketState "Indicates if Infotainment detects rear view camera UDP packets from Autopilot.";
CM_ SG_ 1056 UIS_cameraRRepeaterStreamMissing "Signal representing if left repeater camera stream is active within videod";
CM_ SG_ 1056 UIS_cameraRRepeaterRenderState "Indicates if the touchscreen UI software has composited at least one new right repeater camera window frame.";
CM_ SG_ 1056 UIS_cameraRRepeaterPopup "Right repeater camera popup state";
CM_ SG_ 1056 UIS_cameraRRepeaterPipeline "Right repeater videod pipeline state";
CM_ SG_ 1056 UIS_cameraRRepeaterPacketState "Indicates if Infotainment detects right repeater camera UDP packets from Autopilot.";
CM_ SG_ 1056 UIS_cameraRRepeaterMaxFrametime "UIS ECU: camera r repeater max frametime";
CM_ SG_ 1056 UIS_cameraRRepeaterLateFrames "UIS ECU: camera r repeater late frames";
CM_ SG_ 1056 UIS_cameraRRepeaterFramerate "UIS ECU: camera r repeater framerate";
CM_ SG_ 1056 UIS_cameraRDownwardRenderState "Indicates if the touchscreen UI software has composited at least one new right downward camera window frame.";
CM_ SG_ 1056 UIS_cameraRDownwardPipeline "UIS ECU: camera r downward pipeline";
CM_ SG_ 1056 UIS_cameraRDownwardPacketState "Indicates if Infotainment detects right downward camera UDP packets from Autopilot.";
CM_ SG_ 1056 UIS_cameraLRepeaterStreamMissing "Signal representing if left repeater camera stream is active within videod";
CM_ SG_ 1056 UIS_cameraLRepeaterRenderState "Indicates if the touchscreen UI software has composited at least one new left repeater camera window frame.";
CM_ SG_ 1056 UIS_cameraLRepeaterPopup "Left repeater camera popup state";
CM_ SG_ 1056 UIS_cameraLRepeaterPipeline "Left repeater videod pipeline state";
CM_ SG_ 1056 UIS_cameraLRepeaterPacketState "Indicates if Infotainment detects left repeater camera UDP packets from Autopilot.";
CM_ SG_ 1056 UIS_cameraLRepeaterMaxFrametime "UIS ECU: camera l repeater max frametime";
CM_ SG_ 1056 UIS_cameraLRepeaterLateFrames "UIS ECU: camera l repeater late frames";
CM_ SG_ 1056 UIS_cameraLRepeaterFramerate "UIS ECU: camera l repeater framerate";
CM_ SG_ 1056 UIS_cameraLDownwardRenderState "Indicates if the touchscreen UI software has composited at least one new left downward camera window frame.";
CM_ SG_ 1056 UIS_cameraLDownwardPipeline "UIS ECU: camera l downward pipeline";
CM_ SG_ 1056 UIS_cameraLDownwardPacketState "Indicates if Infotainment detects left downward camera UDP packets from Autopilot.";
CM_ SG_ 1056 UIS_cameraFrontStreamMissing "UIS ECU: camera front stream missing";
CM_ SG_ 1056 UIS_cameraFrontRenderState "Indicates if the touchscreen UI software has composited at least one new front fascia camera window frame.";
CM_ SG_ 1056 UIS_cameraFrontPopup "UIS ECU: camera front popup";
CM_ SG_ 1056 UIS_cameraFrontPipeline "UIS ECU: camera front pipeline";
CM_ SG_ 1056 UIS_cameraFrontPacketState "Indicates if Infotainment detects front fascia camera UDP packets from Autopilot.";
CM_ SG_ 1056 UIS_cameraBackupStreamQuality "UIS ECU: camera backup stream quality";
CM_ SG_ 1056 UIS_cameraBackupStreamMissing "Signal representing if backup camera stream is active within videod";
CM_ SG_ 1056 UIS_cameraBackupRenderState "Indicates if the touchscreen UI software has composited at least one new backup camera window frame.";
CM_ SG_ 1056 UIS_cameraBackupPopup "Reports the backup camera popup state.";
CM_ SG_ 1056 UIS_cameraBackupPipeline "Reports the backup camera video pipeline state.";
CM_ SG_ 1056 UIS_cameraBackupPacketState "Indicates if Infotainment detects backup camera UDP packets from Autopilot.";
CM_ SG_ 1056 UIS_cameraBackupMaxFrametime "UIS ECU: camera backup max frametime";
CM_ SG_ 1056 UIS_pmSuspendHookIndex "UIS ECU: pm suspend hook index";
CM_ SG_ 1056 UIS_cameraBackupLateFrames "UIS ECU: camera backup late frames";
CM_ SG_ 1056 UIS_cameraBackupFramerate "Reports the backup camera framerate.";
CM_ SG_ 1056 UIS_camBackupDecodeMinFrametime "UIS ECU: cam backup decode min frametime";
CM_ SG_ 1056 UIS_camBackupDecodeMaxFrametime "UIS ECU: cam backup decode max frametime";
CM_ SG_ 1056 UIS_camBackupDecodeFramecount "UIS ECU: cam backup decode framecount";
CM_ SG_ 1056 UIS_camBackupDecodeAvgFrametime "UIS ECU: cam backup decode avg frametime";
CM_ SG_ 1056 UIS_bootCount "UIS ECU: boot count";
CM_ SG_ 1056 UIS_boardTemperature "Current temperature reported for board";
CM_ SG_ 1056 UIS_bluetoothState "Reports bluetooth state.";
CM_ SG_ 1056 UIS_bluetoothStackState "Bluetooth stack state";
CM_ SG_ 1056 UIS_bluetoothStackRearState "Bluetooth rear stack state";
CM_ SG_ 1056 UIS_bluetoothPairResult "Bluetooth pairing result";
CM_ SG_ 1056 UIS_bluetoothMemUsage "Reports the Bluetooth process resident memory usage in megabytes.";
CM_ SG_ 1056 UIS_bluetoothConnectionState "Reports the Bluetooth connection state.";
CM_ SG_ 1056 UIS_bluetoothCPUUsage "Reports the Bluetooth process Central Processing Unit (CPU) usage percentage.";
CM_ SG_ 1056 UIS_bluetoothAutoconnectAttempts "Reports the number of Bluetooth auto-connect attempts for the most recent connection cycle.";
CM_ SG_ 1056 UIS_bluetoothAutoconnectActive "Indicates that Bluetooth auto-connect is active.";
CM_ SG_ 1056 UIS_bluetoothAutoConnectionState "Reports the Bluetooth auto-connection state.";
CM_ SG_ 1056 UIS_bifrostOdinEngineUp "Signal reported by UIS ECU";
CM_ SG_ 1056 UIS_bifrostOdinEngineRequests "Signal reported by UIS ECU";
CM_ SG_ 1056 UIS_bifrostMemUsage "UIS ECU: bifrost mem usage";
CM_ SG_ 1056 UIS_bifrostCPUUsage "UIS ECU: bifrost CPU usage";
CM_ SG_ 1056 UIS_backlightUserRequest "Reports the Graphical User Interface (GUI) backlight user request value.";
CM_ SG_ 1056 UIS_audioVolumeLevel "User facing volume level";
CM_ SG_ 1056 UIS_audioType "Shows which audio amplifier type is currently configured";
CM_ SG_ 1056 UIS_audioState "Shows the state of the audio system";
CM_ SG_ 1056 UIS_audioSource "Shows which internal audio source is currently active";
CM_ SG_ 1056 UIS_audioPWSGain "Reports the pedestrian warning system volume in decibels.";
CM_ SG_ 1056 UIS_audioMediaPlaying "Shows which media source is currently being played";
CM_ SG_ 1056 UIS_audioMediaBrowsing "Shows which media source is currently being viewed";
CM_ SG_ 1056 UIS_audioA2BRediscoveryCount "Shows the count of a2b rediscoveries that have occurred";
CM_ SG_ 1056 UIS_apeHardwareMinorVersion "APE hardware minor version from device tree";
CM_ SG_ 1056 UIS_amdSocPkgPower "UIS ECU: amd soc pkg power";
CM_ SG_ 1056 UIS_activeAppView "Shows the currently displayed app";
CM_ SG_ 1056 UIS_CamViewerServiceEnabled "Reports whether the cam-viewer service is enabled.";
CM_ BO_ 1154 "Touchscreen user interface computer message: iso tp pipe remote VCSEC";
CM_ SG_ 1154 UI_IsoTpRemoteVCSEC0 "Touchscreen user interface computer: iso tp remote VCSEC0";
CM_ SG_ 1154 UI_IsoTpRemoteVCSEC1 "Touchscreen user interface computer: iso tp remote VCSEC1";
CM_ SG_ 1154 UI_IsoTpRemoteVCSEC2 "Touchscreen user interface computer: iso tp remote VCSEC2";
CM_ SG_ 1154 UI_IsoTpRemoteVCSEC3 "Touchscreen user interface computer: iso tp remote VCSEC3";
CM_ SG_ 1154 UI_IsoTpRemoteVCSEC4 "Touchscreen user interface computer: iso tp remote VCSEC4";
CM_ SG_ 1154 UI_IsoTpRemoteVCSEC5 "Touchscreen user interface computer: iso tp remote VCSEC5";
CM_ SG_ 1154 UI_IsoTpRemoteVCSEC6 "Touchscreen user interface computer: iso tp remote VCSEC6";
CM_ SG_ 1154 UI_IsoTpRemoteVCSEC7 "Touchscreen user interface computer: iso tp remote VCSEC7";
CM_ BO_ 1153 "Touchscreen user interface computer message: iso tp UDP pipe VCSEC";
CM_ SG_ 1153 UI_IsoTpUDPPipeVCSEC0 "Touchscreen user interface computer: iso tp UDP pipe VCSEC0";
CM_ SG_ 1153 UI_IsoTpUDPPipeVCSEC1 "Touchscreen user interface computer: iso tp UDP pipe VCSEC1";
CM_ SG_ 1153 UI_IsoTpUDPPipeVCSEC2 "Touchscreen user interface computer: iso tp UDP pipe VCSEC2";
CM_ SG_ 1153 UI_IsoTpUDPPipeVCSEC3 "Touchscreen user interface computer: iso tp UDP pipe VCSEC3";
CM_ SG_ 1153 UI_IsoTpUDPPipeVCSEC4 "Touchscreen user interface computer: iso tp UDP pipe VCSEC4";
CM_ SG_ 1153 UI_IsoTpUDPPipeVCSEC5 "Touchscreen user interface computer: iso tp UDP pipe VCSEC5";
CM_ SG_ 1153 UI_IsoTpUDPPipeVCSEC6 "Touchscreen user interface computer: iso tp UDP pipe VCSEC6";
CM_ SG_ 1153 UI_IsoTpUDPPipeVCSEC7 "Touchscreen user interface computer: iso tp UDP pipe VCSEC7";
CM_ BO_ 979 "Touchscreen user interface computer message: airbag cutoff status";
CM_ SG_ 979 UI_airbagCutoffSwState "Reports the front passenger airbag cutoff switch request; raw 2 = signal not available (SNA)";
CM_ SG_ 979 UI_warningIndicatorStatus "Touchscreen user interface computer: warning indicator status; raw 3 = signal not available (SNA)";
CM_ BO_ 1523 "Touchscreen user interface computer message: alert log";
CM_ SG_ 1523 UI_alertID "Touchscreen user interface computer: alert ID";
CM_ SG_ 1523 UI_alertState "Touchscreen user interface computer: alert state";
CM_ SG_ 1523 UI_a006_remoteServiceAlertCode "Touchscreen user interface computer: a006 remote service alert code";
CM_ SG_ 1523 UI_a009_squashfsDevice "Touchscreen user interface computer: a009 squashfs device";
CM_ SG_ 1523 UI_a009_squashfsErrorCount "Touchscreen user interface computer: a009 squashfs error count";
CM_ SG_ 1523 UI_a034_BackupCamera "Touchscreen user interface computer: a034 backup camera";
CM_ SG_ 1523 UI_a034_Tuner "Touchscreen user interface computer: a034 tuner";
CM_ SG_ 1523 UI_a034_Bluetooth "Touchscreen user interface computer: a034 bluetooth";
CM_ SG_ 1523 UI_a034_WiFi "Touchscreen user interface computer: a034 wi fi";
CM_ SG_ 1523 UI_a034_Cellular "Touchscreen user interface computer: a034 cellular";
CM_ SG_ 1523 UI_a034_TouchScreen "Touchscreen user interface computer: a034 touch screen";
CM_ SG_ 1523 UI_a034_Display "Touchscreen user interface computer: a034 display";
CM_ SG_ 1523 UI_a034_Audio "Touchscreen user interface computer: a034 audio";
CM_ SG_ 1523 UI_a034_FatalWakeup "Touchscreen user interface computer: a034 fatal wakeup";
CM_ SG_ 1523 UI_a034_UnknownWakeupError "Touchscreen user interface computer: a034 unknown wakeup error";
CM_ SG_ 1523 UI_a036_audioWatchdogReason "Touchscreen user interface computer: a036 audio watchdog reason";
CM_ SG_ 1523 UI_a045_ManualECallDisabled "Touchscreen user interface computer: a045 manual e call disabled";
CM_ SG_ 1523 UI_a045_ManualECallButtonDisconn "Touchscreen user interface computer: a045 manual e call button disconnected";
CM_ SG_ 1523 UI_a045_CellAntenna "Touchscreen user interface computer: a045 cell antenna";
CM_ SG_ 1523 UI_a045_GPSAntenna "Touchscreen user interface computer: a045 GPS antenna";
CM_ SG_ 1523 UI_a045_ECallSpeaker "Touchscreen user interface computer: a045 e call speaker";
CM_ SG_ 1523 UI_a045_ECallMic "Touchscreen user interface computer: a045 e call mic";
CM_ SG_ 1523 UI_a045_SIMTest "Touchscreen user interface computer: a045 SIM test";
CM_ SG_ 1523 UI_a045_ENSTest "Touchscreen user interface computer: a045 ENS test";
CM_ SG_ 1523 UI_a045_CellularTest "Touchscreen user interface computer: a045 cellular test";
CM_ SG_ 1523 UI_a045_ModemFirmwareTest "Touchscreen user interface computer: a045 modem firmware test";
CM_ SG_ 1523 UI_a052_kernelPanicSignature "Touchscreen user interface computer: a052 kernel panic signature";
CM_ SG_ 1523 UI_a065_wifiRecoveryReason "Touchscreen user interface computer: a065 wifi recovery reason";
CM_ SG_ 1523 UI_a066_ProcessId "Touchscreen user interface computer: a066 process id";
CM_ SG_ 1523 UI_a066_RingBlitter "Touchscreen user interface computer: a066 ring blitter";
CM_ SG_ 1523 UI_a066_RingBSD "Touchscreen user interface computer: a066 ring BSD";
CM_ SG_ 1523 UI_a066_RingRender "Touchscreen user interface computer: a066 ring render";
CM_ SG_ 1523 UI_a066_RingVideoEnhancement "Touchscreen user interface computer: a066 ring video enhancement";
CM_ SG_ 1523 UI_a066_EnginesHung "Touchscreen user interface computer: a066 engines hung";
CM_ SG_ 1523 UI_a066_EnginesWedged "Touchscreen user interface computer: a066 engines wedged";
CM_ SG_ 1523 UI_a066_RecoveryFailed "Touchscreen user interface computer: a066 recovery failed";
CM_ SG_ 1523 UI_a066_FlipDoneTimedOut "Touchscreen user interface computer: a066 flip done timed out";
CM_ SG_ 1523 UI_a066_TimedoutSoftRecovered "Touchscreen user interface computer: a066 timedout soft recovered";
CM_ SG_ 1523 UI_a087_BmpResetType "Touchscreen user interface computer: a087 bmp reset type";
CM_ SG_ 1523 UI_a096_PipelineId "Touchscreen user interface computer: a096 pipeline id";
CM_ SG_ 1523 UI_a096_UdpTimeout "Touchscreen user interface computer: a096 udp timeout";
CM_ SG_ 1523 UI_a096_PipelineWarning "Touchscreen user interface computer: a096 pipeline warning";
CM_ SG_ 1523 UI_a096_PipelineError "Touchscreen user interface computer: a096 pipeline error";
CM_ SG_ 1523 UI_a096_UnexpectedExit "Touchscreen user interface computer: a096 unexpected exit";
CM_ SG_ 1523 UI_a096_PipelineOverrun "Touchscreen user interface computer: a096 pipeline overrun";
CM_ SG_ 1523 UI_a096_MissingXWindow "Touchscreen user interface computer: a096 missing x window";
CM_ SG_ 1523 UI_a099_emmcStatusRegister "Touchscreen user interface computer: a099 emmc status register";
CM_ SG_ 1523 UI_a100_emmcFTLCounter "Touchscreen user interface computer: a100 emmc FTL counter";
CM_ SG_ 1523 UI_a131_DisplayPortFailureType "Touchscreen user interface computer: a131 display port failure type";
CM_ SG_ 1523 UI_a147_whichASIL "Touchscreen user interface computer: a147 which ASIL";
CM_ SG_ 1523 UI_a147_errorCode "Touchscreen user interface computer: a147 error code";
CM_ SG_ 1523 UI_a148_sleepType "Touchscreen user interface computer: a148 sleep type";
CM_ SG_ 1523 UI_a148_lastFailedDev "Touchscreen user interface computer: a148 last failed dev";
CM_ SG_ 1523 UI_a148_lastFailedPmSuspendDev "Touchscreen user interface computer: a148 last failed pm suspend dev";
CM_ SG_ 1523 UI_a149_displayType "Touchscreen user interface computer: a149 display type";
CM_ SG_ 1523 UI_a149_displaySeat "Touchscreen user interface computer: a149 display seat";
CM_ SG_ 1523 UI_a149_errorCode "Touchscreen user interface computer: a149 error code";
CM_ SG_ 1523 UI_a151_cpuAmbientDeltaTemp "Touchscreen user interface computer: a151 cpu ambient delta temp";
CM_ SG_ 1523 UI_a151_socThermalResistance "Touchscreen user interface computer: a151 soc thermal resistance";
CM_ SG_ 1523 UI_a153_processName "Touchscreen user interface computer: a153 process name";
CM_ SG_ 1523 UI_a153_restartReason "Touchscreen user interface computer: a153 restart reason";
CM_ SG_ 1523 UI_a158_UsbDeviceMountErrorCode "Touchscreen user interface computer: a158 usb device mount error code";
CM_ SG_ 1523 UI_a160_WatchdogStarving "Touchscreen user interface computer: a160 watchdog starving";
CM_ SG_ 1523 UI_a160_MemoryPressureCritical "Touchscreen user interface computer: a160 memory pressure critical";
CM_ SG_ 1523 UI_a160_MemoryUsageCritical "Touchscreen user interface computer: a160 memory usage critical";
CM_ SG_ 1523 UI_a160_SlabUsageCritical "Touchscreen user interface computer: a160 slab usage critical";
CM_ SG_ 1523 UI_a165_fsCorruptedDevice "Touchscreen user interface computer: a165 fs corrupted device";
CM_ SG_ 1523 UI_a166_fsErrorDevice "Touchscreen user interface computer: a166 fs error device";
CM_ SG_ 1523 UI_a167_processId "Touchscreen user interface computer: a167 process id";
CM_ SG_ 1523 UI_a173_errorCode "Touchscreen user interface computer: a173 error code";
CM_ SG_ 1523 UI_a173_hookIndex "Touchscreen user interface computer: a173 hook index";
CM_ SG_ 1523 UI_a173_lastFailedPmSuspendDev "Touchscreen user interface computer: a173 last failed pm suspend dev";
CM_ SG_ 1523 UI_a176_PrimaryAntenna "Touchscreen user interface computer: a176 primary antenna";
CM_ SG_ 1523 UI_a176_SecondaryAntenna "Touchscreen user interface computer: a176 secondary antenna";
CM_ SG_ 1523 UI_a176_TertiaryAntenna "Touchscreen user interface computer: a176 tertiary antenna";
CM_ SG_ 1523 UI_a177_errorCode "Touchscreen user interface computer: a177 error code";
CM_ SG_ 1523 UI_a177_errorSource "Touchscreen user interface computer: a177 error source";
CM_ SG_ 1523 UI_a178_irqNumber "Touchscreen user interface computer: a178 irq number";
CM_ SG_ 1523 UI_a178_irqSourceId "Touchscreen user interface computer: a178 irq source id";
CM_ SG_ 1523 UI_a192_AudioRebootState "Touchscreen user interface computer: a192 audio reboot state";
CM_ SG_ 1523 UI_a204_ModemSleepFailureReason "Touchscreen user interface computer: a204 modem sleep failure reason";
CM_ SG_ 1523 UI_a208_mqttClientDisconnectReas "Touchscreen user interface computer: a208 mqtt client disconnect reason";
CM_ SG_ 1523 UI_a214_errorCode "Touchscreen user interface computer: a214 error code";
CM_ SG_ 1523 UI_a214_lastFailedDev "Touchscreen user interface computer: a214 last failed dev";
CM_ SG_ 1523 UI_a214_lastFailedPmSuspendDev "Touchscreen user interface computer: a214 last failed pm suspend dev";
CM_ SG_ 1523 UI_a216_circuitProblem "Touchscreen user interface computer: a216 circuit problem";
CM_ SG_ 1523 UI_a216_circuitNode "Touchscreen user interface computer: a216 circuit node";
CM_ SG_ 1523 UI_a217_cgroupName "Touchscreen user interface computer: a217 cgroup name";
CM_ SG_ 1523 UI_a220_errorCode "Touchscreen user interface computer: a220 error code";
CM_ SG_ 1523 UI_a221_errorCode "Touchscreen user interface computer: a221 error code";
CM_ SG_ 1523 UI_a221_networkErrorCode "Touchscreen user interface computer: a221 network error code; raw 500 = signal not available (SNA)";
CM_ SG_ 1523 UI_a221_serverErrorCode "Touchscreen user interface computer: a221 server error code";
CM_ SG_ 1523 UI_a222_errorCode "Touchscreen user interface computer: a222 error code";
CM_ SG_ 1523 UI_a223_database "Touchscreen user interface computer: a223 database";
CM_ SG_ 1523 UI_a226_count "Touchscreen user interface computer: a226 count";
CM_ SG_ 1523 UI_a229_errorCode "Touchscreen user interface computer: a229 error code";
CM_ SG_ 1523 UI_a231_sleepType "Touchscreen user interface computer: a231 sleep type";
CM_ SG_ 1523 UI_a232_processExited "Touchscreen user interface computer: a232 process exited";
CM_ SG_ 1523 UI_a232_processSignal "Touchscreen user interface computer: a232 process signal";
CM_ SG_ 1523 UI_a240_ethErrorType "Touchscreen user interface computer: a240 eth error type";
CM_ SG_ 1523 UI_a241_errorCode "Touchscreen user interface computer: a241 error code";
CM_ SG_ 1523 UI_a242_CenterDispFaultInjected "Touchscreen user interface computer: a242 center disp fault injected";
CM_ SG_ 1523 UI_a242_ConnectivityFaultInjecte "Touchscreen user interface computer: a242 connectivity fault injected";
CM_ SG_ 1523 UI_a242_ConnectivityHWFaultInjec "Touchscreen user interface computer: a242 connectivity HW fault injected";
CM_ SG_ 1523 UI_a242_QtCarFaultInjected "Signal reported by Touchscreen user interface computer";
CM_ SG_ 1523 UI_a242_RearDispFaultInjected "Touchscreen user interface computer: a242 rear disp fault injected";
CM_ SG_ 1523 UI_a242_QtCarRearFaultInjected "Signal reported by Touchscreen user interface computer";
CM_ SG_ 1523 UI_a242_DASServerFaultInjected "Touchscreen user interface computer: a242 DAS server fault injected";
CM_ SG_ 1523 UI_a242_CenterDispStatusFaultInj "Touchscreen user interface computer: a242 center disp status fault injected";
CM_ SG_ 1523 UI_a242_FaultCode "Touchscreen user interface computer: a242 fault code";
CM_ SG_ 1523 UI_a247_displayType "Touchscreen user interface computer: a247 display type";
CM_ SG_ 1523 UI_a247_displaySeat "Touchscreen user interface computer: a247 display seat";
CM_ SG_ 1523 UI_a253_correctionCode "Touchscreen user interface computer: a253 correction code";
CM_ SG_ 1523 UI_a257_ModemRebootReason "Touchscreen user interface computer: a257 modem reboot reason";
CM_ SG_ 1523 UI_a257_ModemRebootEthPresent "Touchscreen user interface computer: a257 modem reboot eth present";
CM_ SG_ 1523 UI_a261_bluetoothStackPanicReaso "Touchscreen user interface computer: a261 bluetooth stack panic reason";
CM_ SG_ 1523 UI_a263_hermesUploadFailure "Touchscreen user interface computer: a263 hermes upload failure";
CM_ SG_ 1523 UI_a263_udsUploadFailure "Touchscreen user interface computer: a263 uds upload failure";
CM_ SG_ 1523 UI_a274_hintCardType "Touchscreen user interface computer: a274 hint card type";
CM_ SG_ 1523 UI_a274_hintCardDismissOutcome "Touchscreen user interface computer: a274 hint card dismiss outcome";
CM_ BO_ 291 "Touchscreen user interface computer message: alert matrix1";
CM_ SG_ 291 UI_a001_DriverDoorOpen "Touchscreen user interface computer: a001 driver door open";
CM_ SG_ 291 UI_a002_DoorOpen "Touchscreen user interface computer: a002 door open";
CM_ SG_ 291 UI_a003_TrunkOpen "Touchscreen user interface computer: a003 trunk open";
CM_ SG_ 291 UI_a004_FrunkOpen "Touchscreen user interface computer: a004 frunk open";
CM_ SG_ 291 UI_a005_HeadlightsOnDoorOpen "Touchscreen user interface computer: a005 headlights on door open";
CM_ SG_ 291 UI_a006_RemoteServiceAlert "Touchscreen user interface computer: a006 remote service alert";
CM_ SG_ 291 UI_a007_SoftPackConfigMismatch "Touchscreen user interface computer: a007 soft pack config mismatch";
CM_ SG_ 291 UI_a008_TouchScreenError "Touchscreen user interface computer: a008 touch screen error";
CM_ SG_ 291 UI_a009_SquashfsError "Touchscreen user interface computer: a009 squashfs error";
CM_ SG_ 291 UI_a010_MapsMissing "Touchscreen user interface computer: a010 maps missing";
CM_ SG_ 291 UI_a011_IncorrectMap "Touchscreen user interface computer: a011 incorrect map";
CM_ SG_ 291 UI_a012_NotOnPrivateProperty "Touchscreen user interface computer: a012 not on private property";
CM_ SG_ 291 UI_a013_TPMSHardWarning "Touchscreen user interface computer: a013 TPMS hard warning";
CM_ SG_ 291 UI_a014_TPMSSoftWarning "Touchscreen user interface computer: a014 TPMS soft warning";
CM_ SG_ 291 UI_a015_TPMSOverPressureWarning "Touchscreen user interface computer: a015 TPMS over pressure warning";
CM_ SG_ 291 UI_a016_TPMSTemperatureWarning "Touchscreen user interface computer: a016 TPMS temperature warning";
CM_ SG_ 291 UI_a017_TPMSSystemFault "Touchscreen user interface computer: a017 TPMS system fault";
CM_ SG_ 291 UI_a018_SlipStartOn "Touchscreen user interface computer: a018 slip start on";
CM_ SG_ 291 UI_a019_ParkBrakeFault "Touchscreen user interface computer: a019 park brake fault";
CM_ SG_ 291 UI_a020_SteeringReduced "Touchscreen user interface computer: a020 steering reduced";
CM_ SG_ 291 UI_a021_RearSeatbeltUnbuckled "Touchscreen user interface computer: a021 rear seatbelt unbuckled";
CM_ SG_ 291 UI_a022_ApeFusesEtc "Touchscreen user interface computer: a022 ape fuses etc";
CM_ SG_ 291 UI_a023_CellInternetCheckFailed "Touchscreen user interface computer: a023 cell internet check failed";
CM_ SG_ 291 UI_a024_WifiInternetCheckFailed "Touchscreen user interface computer: a024 wifi internet check failed";
CM_ SG_ 291 UI_a026_ModemResetLoopDetected "Touchscreen user interface computer: a026 modem reset loop detected";
CM_ SG_ 291 UI_a027_AutoSteerMIA "Touchscreen user interface computer: a027 auto steer MIA";
CM_ SG_ 291 UI_a028_FrontTrunkPopupClosed "Touchscreen user interface computer: a028 front trunk popup closed";
CM_ SG_ 291 UI_a029_ModemMIA "Touchscreen user interface computer: a029 modem MIA";
CM_ SG_ 291 UI_a030_ModemVMCrash "Touchscreen user interface computer: a030 modem VM crash";
CM_ SG_ 291 UI_a031_BrakeFluidLow "Touchscreen user interface computer: a031 brake fluid low";
CM_ SG_ 291 UI_a032_CellModemRecoveryResets "Touchscreen user interface computer: a032 cell modem recovery resets";
CM_ SG_ 291 UI_a033_ApTrialExpired "Touchscreen user interface computer: a033 ap trial expired";
CM_ SG_ 291 UI_a034_WakeupProblem "Touchscreen user interface computer: a034 wakeup problem";
CM_ SG_ 291 UI_a035_FrunkOpenChime "Touchscreen user interface computer: a035 frunk open chime";
CM_ SG_ 291 UI_a036_AudioWatchdog "Touchscreen user interface computer: a036 audio watchdog";
CM_ SG_ 291 UI_a037_AudioWatchdogXrunStormEr "Touchscreen user interface computer: a037 audio watchdog xrun storm error";
CM_ SG_ 291 UI_a038_AudioWatchdogA2bI2cLocku "Touchscreen user interface computer: a038 audio watchdog a2b i2c lockup error";
CM_ SG_ 291 UI_a039_AudioA2bNeedRediscovery "Touchscreen user interface computer: a039 audio a2b need rediscovery";
CM_ SG_ 291 UI_a040_HomelinkTransmit "Touchscreen user interface computer: a040 homelink transmit";
CM_ SG_ 291 UI_a041_AudioDmesgXrun "Touchscreen user interface computer: a041 audio dmesg xrun";
CM_ SG_ 291 UI_a042_AudioDmesgRtThrottling "Touchscreen user interface computer: a042 audio dmesg rt throttling";
CM_ SG_ 291 UI_a043_InvalidMapDataOverride "Touchscreen user interface computer: a043 invalid map data override";
CM_ SG_ 291 UI_a044_AudioDmesgDspException "Touchscreen user interface computer: a044 audio dmesg dsp exception";
CM_ SG_ 291 UI_a045_ECallSystemCheckFailed "Touchscreen user interface computer: a045 e call system check failed";
CM_ SG_ 291 UI_a046_BackupCameraStreamError "Touchscreen user interface computer: a046 backup camera stream error";
CM_ SG_ 291 UI_a047_CellRoamingDisallowed "Touchscreen user interface computer: a047 cell roaming disallowed";
CM_ SG_ 291 UI_a048_AudioPremiumAmpCheckFail "Touchscreen user interface computer: a048 audio premium amp check failed";
CM_ SG_ 291 UI_a049_BrakeShiftRequired "Touchscreen user interface computer: a049 brake shift required";
CM_ SG_ 291 UI_a050_BackupCameraIPUTimeout "Touchscreen user interface computer: a050 backup camera IPU timeout";
CM_ SG_ 291 UI_a051_BackupCameraFrameTimeout "Touchscreen user interface computer: a051 backup camera frame timeout";
CM_ SG_ 291 UI_a052_KernelPanicReported "Touchscreen user interface computer: a052 kernel panic reported";
CM_ SG_ 291 UI_a053_QtCarExitError "Signal reported by Touchscreen user interface computer";
CM_ SG_ 291 UI_a054_AudioBoostPowerBad "Touchscreen user interface computer: a054 audio boost power bad";
CM_ SG_ 291 UI_a055_ManualECallDisabled "Touchscreen user interface computer: a055 manual e call disabled";
CM_ SG_ 291 UI_a056_ManualECallButtonDisconn "Touchscreen user interface computer: a056 manual e call button disconnected";
CM_ SG_ 291 UI_a057_CellAntennaDisconnected "Touchscreen user interface computer: a057 cell antenna disconnected";
CM_ SG_ 291 UI_a058_GPSAntennaDisconnected "Touchscreen user interface computer: a058 GPS antenna disconnected";
CM_ SG_ 291 UI_a059_ECallSpeakerDisconnected "Touchscreen user interface computer: a059 e call speaker disconnected";
CM_ SG_ 291 UI_a060_ECallMicDisconnected "Touchscreen user interface computer: a060 e call mic disconnected";
CM_ SG_ 291 UI_a061_SIMTestFailed "Touchscreen user interface computer: a061 SIM test failed";
CM_ SG_ 291 UI_a062_ENSTestFailed "Touchscreen user interface computer: a062 ENS test failed";
CM_ SG_ 291 UI_a063_CellularTestFailed "Touchscreen user interface computer: a063 cellular test failed";
CM_ SG_ 291 UI_a064_ModemFirmwareTestFailed "Touchscreen user interface computer: a064 modem firmware test failed";
CM_ BO_ 292 "Touchscreen user interface computer message: alert matrix2";
CM_ SG_ 292 UI_a065_WiFiRecoveryReset "Touchscreen user interface computer: a065 wi fi recovery reset";
CM_ SG_ 292 UI_a066_GpuHangDetected "Touchscreen user interface computer: a066 gpu hang detected";
CM_ SG_ 292 UI_a067_WarnOnI915 "Touchscreen user interface computer: a067 warn on I915";
CM_ SG_ 292 UI_a068_VideoUnexpectedExit "Touchscreen user interface computer: a068 video unexpected exit";
CM_ SG_ 292 UI_a069_VideoUDPTimeout "Touchscreen user interface computer: a069 video UDP timeout";
CM_ SG_ 292 UI_a070_VideoPipelineWarning "Touchscreen user interface computer: a070 video pipeline warning";
CM_ SG_ 292 UI_a071_VideoPipelineError "Touchscreen user interface computer: a071 video pipeline error";
CM_ SG_ 292 UI_a072_ECallAnalogMicFailed "Touchscreen user interface computer: a072 e call analog mic failed";
CM_ SG_ 292 UI_a073_ECallDigitalMicFailed "Touchscreen user interface computer: a073 e call digital mic failed";
CM_ SG_ 292 UI_a074_EMMCHangDetected "Touchscreen user interface computer: a074 EMMC hang detected";
CM_ SG_ 292 UI_a075_BackupCameraInitError "Touchscreen user interface computer: a075 backup camera init error";
CM_ SG_ 292 UI_a076_NumFalseManualECalls "Touchscreen user interface computer: a076 num false manual e calls";
CM_ SG_ 292 UI_a077_AudioA2bMicChannelSwap "Touchscreen user interface computer: a077 audio a2b mic channel swap";
CM_ SG_ 292 UI_a078_DashcamUsbDriveUnmountab "Touchscreen user interface computer: a078 dashcam usb drive unmountable";
CM_ SG_ 292 UI_a079_DashcamUsbDriveFull "Touchscreen user interface computer: a079 dashcam usb drive full";
CM_ SG_ 292 UI_a080_DashcamUsbDriveSlow "Touchscreen user interface computer: a080 dashcam usb drive slow";
CM_ SG_ 292 UI_a081_CellModemSearchExpired "Touchscreen user interface computer: a081 cell modem search expired";
CM_ SG_ 292 UI_a082_NumModemRebootStuckInECa "Touchscreen user interface computer: a082 num modem reboot stuck in e call";
CM_ SG_ 292 UI_a083_ECallProxyWatchdogTrigge "Touchscreen user interface computer: a083 e call proxy watchdog triggered";
CM_ SG_ 292 UI_a084_SerializerError "Touchscreen user interface computer: a084 serializer error";
CM_ SG_ 292 UI_a085_DeserializerError "Touchscreen user interface computer: a085 deserializer error";
CM_ SG_ 292 UI_a086_TouchEnumerationError "Touchscreen user interface computer: a086 touch enumeration error";
CM_ SG_ 292 UI_a087_BmpReset "Touchscreen user interface computer: a087 bmp reset";
CM_ SG_ 292 UI_a088_CellRemovableSimMissing "Touchscreen user interface computer: a088 cell removable sim missing";
CM_ SG_ 292 UI_a089_RadioReset "Touchscreen user interface computer: a089 radio reset";
CM_ SG_ 292 UI_a090_RadioPingFailError "Touchscreen user interface computer: a090 radio ping fail error";
CM_ SG_ 292 UI_a091_VehicleLinkStall "Touchscreen user interface computer: a091 vehicle link stall";
CM_ SG_ 292 UI_a092_updateStarted "Touchscreen user interface computer: a092 update started";
CM_ SG_ 292 UI_a093_updateEnded "Touchscreen user interface computer: a093 update ended";
CM_ SG_ 292 UI_a094_ModemPowerOnFailure "Touchscreen user interface computer: a094 modem power on failure";
CM_ SG_ 292 UI_a095_CidStorageRunningLow "Touchscreen user interface computer: a095 cid storage running low";
CM_ SG_ 292 UI_a096_VideodPipelineIssueDetec "Touchscreen user interface computer: a096 videod pipeline issue detected";
CM_ SG_ 292 UI_a097_AudiodRestarted "Touchscreen user interface computer: a097 audiod restarted";
CM_ SG_ 292 UI_a098_DiskCheckFailure "Touchscreen user interface computer: a098 disk check failure";
CM_ SG_ 292 UI_a099_eMMCStatusError "Touchscreen user interface computer: a099 e MMC status error";
CM_ SG_ 292 UI_a100_eMMCFTLError "Touchscreen user interface computer: a100 e MMCFTL error";
CM_ SG_ 292 UI_a101_wifiStackProblem "Touchscreen user interface computer: a101 wifi stack problem";
CM_ SG_ 292 UI_a102_A2bDiscoveryFailed "Touchscreen user interface computer: a102 a2b discovery failed";
CM_ SG_ 292 UI_a103_UsbHubNotEnumerating "Touchscreen user interface computer: a103 usb hub not enumerating";
CM_ SG_ 292 UI_a104_DashcamUsbDriveMissing "Touchscreen user interface computer: a104 dashcam usb drive missing";
CM_ SG_ 292 UI_a105_firmwareReinstallRequest "Touchscreen user interface computer: a105 firmware reinstall requested";
CM_ SG_ 292 UI_a106_rebootBackstopTriggered "Touchscreen user interface computer: a106 reboot backstop triggered";
CM_ SG_ 292 UI_a107_DashcamUsbDriveTooBigFor "Touchscreen user interface computer: a107 dashcam usb drive too big for vfat fsck";
CM_ SG_ 292 UI_a108_DashcamUsbDriveGettingFu "Touchscreen user interface computer: a108 dashcam usb drive getting full";
CM_ SG_ 292 UI_a109_DashcamUsbDriveTooSmall "Touchscreen user interface computer: a109 dashcam usb drive too small";
CM_ SG_ 292 UI_a110_DashcamUsbDriveCorrupt "Touchscreen user interface computer: a110 dashcam usb drive corrupt";
CM_ SG_ 292 UI_a111_DashcamUsbDriveNotSuperS "Touchscreen user interface computer: a111 dashcam usb drive not super speed";
CM_ SG_ 292 UI_a112_badUSBDevice "Touchscreen user interface computer: a112 bad USB device";
CM_ SG_ 292 UI_a113_DashcamHasOnboardSentryC "Touchscreen user interface computer: a113 dashcam has onboard sentry clips";
CM_ SG_ 292 UI_a114_drivingVisualizationDegr "Touchscreen user interface computer: a114 driving visualization degraded";
CM_ SG_ 292 UI_a115_IrisEDLMode "Touchscreen user interface computer: a115 iris EDL mode";
CM_ SG_ 292 UI_a116_UncorrectableMemoryError "Touchscreen user interface computer: a116 uncorrectable memory error";
CM_ SG_ 292 UI_a117_VehicleSelfTestRunning "Touchscreen user interface computer: a117 vehicle self test running";
CM_ SG_ 292 UI_a118_NVMeReset "Touchscreen user interface computer: a118 NV me reset";
CM_ SG_ 292 UI_a119_nvmeBlockDeviceMissing "Touchscreen user interface computer: a119 nvme block device missing";
CM_ SG_ 292 UI_a120_nvmePCIeLinkErrorDetecte "Touchscreen user interface computer: a120 nvme PC ie link error detected";
CM_ SG_ 292 UI_a121_nvmeSmartLogCritical "Touchscreen user interface computer: a121 nvme smart log critical";
CM_ SG_ 292 UI_a122_AMDI2C0LostArbitration "Touchscreen user interface computer: a122 AMDI2 C0 lost arbitration";
CM_ SG_ 292 UI_a123_AMDI2C1LostArbitration "Touchscreen user interface computer: a123 AMDI2 C1 lost arbitration";
CM_ SG_ 292 UI_a124_AMDI2C0TxRxAborted "Touchscreen user interface computer: a124 AMDI2 C0 tx rx aborted";
CM_ SG_ 292 UI_a125_AMDI2C1TxRxAborted "Touchscreen user interface computer: a125 AMDI2 C1 tx rx aborted";
CM_ SG_ 292 UI_a126_UsbErrorDriveCorrupt "Touchscreen user interface computer: a126 usb error drive corrupt";
CM_ SG_ 292 UI_a128_dgpuNotDetected "Touchscreen user interface computer: a128 dgpu not detected";
BA_DEF_ BO_ "GenMsgCycleTime" INT 0 3600000;
BA_DEF_ BO_ "GenMsgSendType" ENUM "Cyclic","NotUsed","NotUsed","NotUsed","NotUsed","NotUsed","NotUsed","IfActive","NoMsgSendType","NotUsed";
BA_DEF_ BO_ "VFrameFormat" ENUM "StandardCAN","ExtendedCAN","reserved","J1939PG","reserved","reserved","reserved","reserved","reserved","reserved","reserved","reserved","reserved","reserved","StandardCAN_FD","ExtendedCAN_FD";
BA_DEF_ BO_ "CANFD_BRS" ENUM "0","1";
BA_DEF_ SG_ "GenSigSNA" STRING;
BA_DEF_ SG_ "SystemSignalLongSymbol" STRING;
BA_DEF_ SG_ "Confidence" ENUM "validated","plausible","layout-only","contradicted";
BA_DEF_DEF_ "GenMsgCycleTime" 0;
BA_DEF_DEF_ "GenMsgSendType" "NoMsgSendType";
BA_DEF_DEF_ "VFrameFormat" "StandardCAN";
BA_DEF_DEF_ "CANFD_BRS" "1";
BA_DEF_DEF_ "GenSigSNA" "";
BA_DEF_DEF_ "SystemSignalLongSymbol" "";
BA_DEF_DEF_ "Confidence" "layout-only";
BA_ "GenMsgCycleTime" BO_ 979 500;
BA_ "GenMsgSendType" BO_ 979 0;
BA_ "GenMsgCycleTime" BO_ 291 1000;
BA_ "GenMsgSendType" BO_ 291 0;
BA_ "GenMsgCycleTime" BO_ 292 1000;
BA_ "GenMsgSendType" BO_ 292 0;
BA_ "Confidence" SG_ 1056 UIS_logMux 1;
BA_ "Confidence" SG_ 1056 UIS_wifiTemperature 0;
BA_ "Confidence" SG_ 1056 UIS_wifiStackState 0;
BA_ "Confidence" SG_ 1056 UIS_wifiStackReady 1;
BA_ "Confidence" SG_ 1056 UIS_wifiBars 0;
BA_ "Confidence" SG_ 1056 UIS_wifiAutoJoinLowRSSI 0;
BA_ "Confidence" SG_ 1056 UIS_valetMode 0;
BA_ "Confidence" SG_ 1056 UIS_uiQtCarUptime 0;
BA_ "Confidence" SG_ 1056 UIS_uiMeanFPS 0;
BA_ "Confidence" SG_ 1056 UIS_tunerVoltageOperation 0;
BA_ "Confidence" SG_ 1056 UIS_tunerVoltageAntenna2 0;
BA_ "Confidence" SG_ 1056 UIS_tunerVoltageAntenna1 0;
BA_ "Confidence" SG_ 1056 UIS_tunerCurrentAntenna2 0;
BA_ "Confidence" SG_ 1056 UIS_tunerCurrentAntenna1 0;
BA_ "Confidence" SG_ 1056 UIS_thermalResistance 1;
BA_ "Confidence" SG_ 1056 UIS_thermalProfile 1;
BA_ "GenSigSNA" SG_ 1056 UIS_thermalProfile "0";
BA_ "Confidence" SG_ 1056 UIS_testDriveMode 1;
BA_ "Confidence" SG_ 1056 UIS_teleopMinPacketDelta 1;
BA_ "Confidence" SG_ 1056 UIS_teleopMaxPacketDelta 1;
BA_ "Confidence" SG_ 1056 UIS_teleopAvgPacketDelta 1;
BA_ "Confidence" SG_ 1056 UIS_tegraModemManState 0;
BA_ "Confidence" SG_ 1056 UIS_systemWakeTime 0;
BA_ "Confidence" SG_ 1056 UIS_systemUptime 0;
BA_ "Confidence" SG_ 1056 UIS_suspensionGeofence 0;
BA_ "Confidence" SG_ 1056 UIS_superchargePaymentNeeded 0;
BA_ "Confidence" SG_ 1056 UIS_softwareUpdateState 1;
BA_ "Confidence" SG_ 1056 UIS_softwareUpdatePrimDownload 1;
BA_ "Confidence" SG_ 1056 UIS_softwareInstallPopupStatus 1;
BA_ "Confidence" SG_ 1056 UIS_sleepType 0;
BA_ "Confidence" SG_ 1056 UIS_sleepTime 0;
BA_ "Confidence" SG_ 1056 UIS_sleepState 0;
BA_ "Confidence" SG_ 1056 UIS_slackerLoginResult 0;
BA_ "Confidence" SG_ 1056 UIS_settingsAutoTurnSignal 1;
BA_ "Confidence" SG_ 1056 UIS_sentryState 0;
BA_ "Confidence" SG_ 1056 UIS_sentryNeedsNap 0;
BA_ "Confidence" SG_ 1056 UIS_sentryIncidentCount 0;
BA_ "Confidence" SG_ 1056 UIS_scheduledChargingMode 0;
BA_ "Confidence" SG_ 1056 UIS_scheduleChargeStartTime 0;
BA_ "Confidence" SG_ 1056 UIS_scheduleChargeEndTime 0;
BA_ "Confidence" SG_ 1056 UIS_remoteRequestType 0;
BA_ "Confidence" SG_ 1056 UIS_rearDisplayUserPresent 0;
BA_ "Confidence" SG_ 1056 UIS_rearDisplayState 0;
BA_ "Confidence" SG_ 1056 UIS_powerManagerState 0;
BA_ "GenSigSNA" SG_ 1056 UIS_powerManagerState "18";
BA_ "Confidence" SG_ 1056 UIS_polytopiax8664MemUsage 0;
BA_ "Confidence" SG_ 1056 UIS_polytopiax8664CPUUsage 0;
BA_ "Confidence" SG_ 1056 UIS_odinStatusCmdResult 1;
BA_ "Confidence" SG_ 1056 UIS_odinProcessState 1;
BA_ "Confidence" SG_ 1056 UIS_odinPeriodicTaskState 1;
BA_ "Confidence" SG_ 1056 UIS_odinListTasksCmdResult 1;
BA_ "Confidence" SG_ 1056 UIS_odinHrlUploadLimits 1;
BA_ "Confidence" SG_ 1056 UIS_odinHrlLogUploadState 1;
BA_ "Confidence" SG_ 1056 UIS_odinHermesConnectionState 1;
BA_ "Confidence" SG_ 1056 UIS_odinGatewayConnectionState 1;
BA_ "Confidence" SG_ 1056 UIS_odinFileSystemState 1;
BA_ "Confidence" SG_ 1056 UIS_odinEcuLogUploadState 1;
BA_ "Confidence" SG_ 1056 UIS_odinEcuLogForceTriggerUpload 1;
BA_ "SystemSignalLongSymbol" SG_ 1056 UIS_odinEcuLogForceTriggerUpload "UIS_odinEcuLogForceTriggerUploadState";
BA_ "Confidence" SG_ 1056 UIS_netWifiTxRate 1;
BA_ "Confidence" SG_ 1056 UIS_netWifiTxCount 1;
BA_ "Confidence" SG_ 1056 UIS_netWifiRxRate 1;
BA_ "Confidence" SG_ 1056 UIS_netWifiRxCount 1;
BA_ "Confidence" SG_ 1056 UIS_netEthTxRate 1;
BA_ "Confidence" SG_ 1056 UIS_netEthTxCount 1;
BA_ "Confidence" SG_ 1056 UIS_netEthRxRate 1;
BA_ "Confidence" SG_ 1056 UIS_netEthRxCount 1;
BA_ "Confidence" SG_ 1056 UIS_netCellTxRate 1;
BA_ "Confidence" SG_ 1056 UIS_netCellTxCount 1;
BA_ "Confidence" SG_ 1056 UIS_netCellRxRate 1;
BA_ "Confidence" SG_ 1056 UIS_netCellRxCount 1;
BA_ "Confidence" SG_ 1056 UIS_navServiceError 0;
BA_ "Confidence" SG_ 1056 UIS_navAudioVolume 0;
BA_ "Confidence" SG_ 1056 UIS_muteNavVolume 0;
BA_ "Confidence" SG_ 1056 UIS_mounterdState 1;
BA_ "Confidence" SG_ 1056 UIS_modemECallppAvail 0;
BA_ "Confidence" SG_ 1056 UIS_modemBusyActive 0;
BA_ "Confidence" SG_ 1056 UIS_mirrorGeofenceActive 0;
BA_ "Confidence" SG_ 1056 UIS_mediaPlaybackStatus 0;
BA_ "Confidence" SG_ 1056 UIS_mediaNeedAuthToken 0;
BA_ "Confidence" SG_ 1056 UIS_inSuperchargerGeofence 0;
BA_ "Confidence" SG_ 1056 UIS_homelinkState 0;
BA_ "Confidence" SG_ 1056 UIS_hicarEventCode 1;
BA_ "Confidence" SG_ 1056 UIS_hicarErrorCode 1;
BA_ "Confidence" SG_ 1056 UIS_hicarConnectionState 1;
BA_ "Confidence" SG_ 1056 UIS_hicarCallState 1;
BA_ "Confidence" SG_ 1056 UIS_hicarAudioTeardownState 1;
BA_ "Confidence" SG_ 1056 UIS_hicarAudioSetupState 1;
BA_ "Confidence" SG_ 1056 UIS_headsetPairResult 0;
BA_ "Confidence" SG_ 1056 UIS_headsetConnectionState 0;
BA_ "Confidence" SG_ 1056 UIS_gpsmanagerMemUsage 0;
BA_ "Confidence" SG_ 1056 UIS_gpsmanagerCPUUsage 0;
BA_ "Confidence" SG_ 1056 UIS_firmwareReleaseScope 1;
BA_ "Confidence" SG_ 1056 UIS_featureSuperchargingEnabled 0;
BA_ "Confidence" SG_ 1056 UIS_embeddedGameState 1;
BA_ "Confidence" SG_ 1056 UIS_embeddedGameName 1;
BA_ "Confidence" SG_ 1056 UIS_dynamicTriggersTelemetryServ 1;
BA_ "SystemSignalLongSymbol" SG_ 1056 UIS_dynamicTriggersTelemetryServ "UIS_dynamicTriggersTelemetryServiceState";
BA_ "Confidence" SG_ 1056 UIS_dynamicTriggersOutputManager 1;
BA_ "SystemSignalLongSymbol" SG_ 1056 UIS_dynamicTriggersOutputManager "UIS_dynamicTriggersOutputManagerServiceState";
BA_ "Confidence" SG_ 1056 UIS_dynamicTriggersHRLServiceSta 1;
BA_ "SystemSignalLongSymbol" SG_ 1056 UIS_dynamicTriggersHRLServiceSta "UIS_dynamicTriggersHRLServiceState";
BA_ "Confidence" SG_ 1056 UIS_dynamicTriggersCampaignState 1;
BA_ "GenSigSNA" SG_ 1056 UIS_dynamicTriggersCampaignState "0";
BA_ "Confidence" SG_ 1056 UIS_dumTclipUploadState 1;
BA_ "SystemSignalLongSymbol" SG_ 1056 UIS_dumTclipSuccessfulUploadCoun "UIS_dumTclipSuccessfulUploadCount";
BA_ "Confidence" SG_ 1056 UIS_dmRearTouchDeviceExists 0;
BA_ "Confidence" SG_ 1056 UIS_dmRearPowerState 0;
BA_ "Confidence" SG_ 1056 UIS_dmRearLinkCheckOk 0;
BA_ "Confidence" SG_ 1056 UIS_dmRearEnabled 0;
BA_ "Confidence" SG_ 1056 UIS_dmRearConnected 0;
BA_ "Confidence" SG_ 1056 UIS_dmRearBacklightPowerLevel 1;
BA_ "Confidence" SG_ 1056 UIS_dmRearBacklightDutyCycle 0;
BA_ "Confidence" SG_ 1056 UIS_dmRearBacklightDevExists 0;
BA_ "Confidence" SG_ 1056 UIS_dmIcuPowerState 0;
BA_ "Confidence" SG_ 1056 UIS_dmIcuLinkCheckOk 0;
BA_ "Confidence" SG_ 1056 UIS_dmIcuEnabled 0;
BA_ "Confidence" SG_ 1056 UIS_dmIcuConnected 0;
BA_ "Confidence" SG_ 1056 UIS_dmIcuBacklightPowerLevel 1;
BA_ "Confidence" SG_ 1056 UIS_dmIcuBacklightDutyCycle 0;
BA_ "Confidence" SG_ 1056 UIS_dmIcuBacklightDevExists 0;
BA_ "Confidence" SG_ 1056 UIS_dmIcuAsilResumeFlag 1;
BA_ "Confidence" SG_ 1056 UIS_dmIcuAsilFirmwareStatus 1;
BA_ "Confidence" SG_ 1056 UIS_dmGatewayLinkWedged 0;
BA_ "Confidence" SG_ 1056 UIS_dmCenterTouchDeviceExists 0;
BA_ "Confidence" SG_ 1056 UIS_dmCenterSOsdExactCrcCheck 1;
BA_ "Confidence" SG_ 1056 UIS_dmCenterPowerState 0;
BA_ "Confidence" SG_ 1056 UIS_dmCenterOsdDisplayedState 0;
BA_ "Confidence" SG_ 1056 UIS_dmCenterOsdDayNightState 1;
BA_ "Confidence" SG_ 1056 UIS_dmCenterModeSettingStatus 1;
BA_ "Confidence" SG_ 1056 UIS_dmCenterMOsdExactCrcCheck 1;
BA_ "Confidence" SG_ 1056 UIS_dmCenterLinkCheckOk 0;
BA_ "Confidence" SG_ 1056 UIS_dmCenterEnabled 0;
BA_ "Confidence" SG_ 1056 UIS_dmCenterConnected 0;
BA_ "Confidence" SG_ 1056 UIS_dmCenterBacklightPowerLevel 0;
BA_ "Confidence" SG_ 1056 UIS_dmCenterBacklightDutyCycle 0;
BA_ "Confidence" SG_ 1056 UIS_dmCenterBacklightDevExists 0;
BA_ "Confidence" SG_ 1056 UIS_dmCenterBacklightControlDefe 0;
BA_ "SystemSignalLongSymbol" SG_ 1056 UIS_dmCenterBacklightControlDefe "UIS_dmCenterBacklightControlDeferred";
BA_ "Confidence" SG_ 1056 UIS_dmCenterAsilResumeFlag 1;
BA_ "Confidence" SG_ 1056 UIS_dmCenterAsilFirmwareStatus 1;
BA_ "Confidence" SG_ 1056 UIS_dmCenterAsilCalibrationSync 1;
BA_ "Confidence" SG_ 1056 UIS_dgpuTemperature 0;
BA_ "Confidence" SG_ 1056 UIS_dashcamviewerMemUsage 0;
BA_ "Confidence" SG_ 1056 UIS_dashcamviewerCPUUsage 0;
BA_ "Confidence" SG_ 1056 UIS_dashcamStorageState 0;
BA_ "Confidence" SG_ 1056 UIS_dashcamStorageSentryMB 0;
BA_ "Confidence" SG_ 1056 UIS_dashcamStorageSavedMB 0;
BA_ "Confidence" SG_ 1056 UIS_dashcamStorageRecentMB 0;
BA_ "Confidence" SG_ 1056 UIS_dashcamStorageAvailableMB 0;
BA_ "Confidence" SG_ 1056 UIS_dashcamState 0;
BA_ "Confidence" SG_ 1056 UIS_dasAutonomyControlMessageMia 1;
BA_ "SystemSignalLongSymbol" SG_ 1056 UIS_dasAutonomyControlMessageMia "UIS_dasAutonomyControlMessageMiaInDriverlessTakeover";
BA_ "Confidence" SG_ 1056 UIS_cpuTemperature 0;
BA_ "SystemSignalLongSymbol" SG_ 1056 UIS_compositorRenderMinRenderTim "UIS_compositorRenderMinRenderTime";
BA_ "SystemSignalLongSymbol" SG_ 1056 UIS_compositorRenderMaxRenderTim "UIS_compositorRenderMaxRenderTime";
BA_ "SystemSignalLongSymbol" SG_ 1056 UIS_compositorRenderGpuPercentag "UIS_compositorRenderGpuPercentage";
BA_ "SystemSignalLongSymbol" SG_ 1056 UIS_compositorRenderAvgRenderTim "UIS_compositorRenderAvgRenderTime";
BA_ "Confidence" SG_ 1056 UIS_compositorFrameMonitorState 1;
BA_ "Confidence" SG_ 1056 UIS_clusterMemUsage 0;
BA_ "Confidence" SG_ 1056 UIS_clusterDisplayState 0;
BA_ "Confidence" SG_ 1056 UIS_clusterCPUUsage 0;
BA_ "Confidence" SG_ 1056 UIS_chargeOnSolarNoChargeReason 0;
BA_ "Confidence" SG_ 1056 UIS_chargeLocationId 0;
BA_ "Confidence" SG_ 1056 UIS_centerDisplayState 0;
BA_ "Confidence" SG_ 1056 UIS_centerDisplayEvent 0;
BA_ "Confidence" SG_ 1056 UIS_cellularLinkManagerState 0;
BA_ "Confidence" SG_ 1056 UIS_cellularConnectivityStatus 0;
BA_ "Confidence" SG_ 1056 UIS_carAssistState 0;
BA_ "Confidence" SG_ 1056 UIS_carAssistSessionCount 0;
BA_ "Confidence" SG_ 1056 UIS_carAssistMicMuted 0;
BA_ "Confidence" SG_ 1056 UIS_carAssistMicAlsaRms 0;
BA_ "Confidence" SG_ 1056 UIS_carAssistErrorCode 0;
BA_ "Confidence" SG_ 1056 UIS_cameraSelectableRenderState 0;
BA_ "Confidence" SG_ 1056 UIS_cameraSelectablePipeline 0;
BA_ "Confidence" SG_ 1056 UIS_cameraSelectablePacketState 0;
BA_ "Confidence" SG_ 1056 UIS_cameraRearViewStreamMissing 1;
BA_ "Confidence" SG_ 1056 UIS_cameraRearViewRenderState 0;
BA_ "Confidence" SG_ 1056 UIS_cameraRearViewPopup 1;
BA_ "Confidence" SG_ 1056 UIS_cameraRearViewPipeline 1;
BA_ "Confidence" SG_ 1056 UIS_cameraRearViewPacketState 0;
BA_ "Confidence" SG_ 1056 UIS_cameraRRepeaterStreamMissing 0;
BA_ "Confidence" SG_ 1056 UIS_cameraRRepeaterRenderState 0;
BA_ "Confidence" SG_ 1056 UIS_cameraRRepeaterPopup 0;
BA_ "Confidence" SG_ 1056 UIS_cameraRRepeaterPipeline 0;
BA_ "Confidence" SG_ 1056 UIS_cameraRRepeaterPacketState 0;
BA_ "Confidence" SG_ 1056 UIS_cameraRDownwardRenderState 0;
BA_ "Confidence" SG_ 1056 UIS_cameraRDownwardPipeline 1;
BA_ "Confidence" SG_ 1056 UIS_cameraRDownwardPacketState 0;
BA_ "Confidence" SG_ 1056 UIS_cameraLRepeaterStreamMissing 0;
BA_ "Confidence" SG_ 1056 UIS_cameraLRepeaterRenderState 0;
BA_ "Confidence" SG_ 1056 UIS_cameraLRepeaterPopup 0;
BA_ "Confidence" SG_ 1056 UIS_cameraLRepeaterPipeline 0;
BA_ "Confidence" SG_ 1056 UIS_cameraLRepeaterPacketState 0;
BA_ "Confidence" SG_ 1056 UIS_cameraLDownwardRenderState 0;
BA_ "Confidence" SG_ 1056 UIS_cameraLDownwardPipeline 1;
BA_ "Confidence" SG_ 1056 UIS_cameraLDownwardPacketState 0;
BA_ "Confidence" SG_ 1056 UIS_cameraFrontStreamMissing 1;
BA_ "Confidence" SG_ 1056 UIS_cameraFrontRenderState 0;
BA_ "Confidence" SG_ 1056 UIS_cameraFrontPopup 1;
BA_ "Confidence" SG_ 1056 UIS_cameraFrontPipeline 1;
BA_ "Confidence" SG_ 1056 UIS_cameraFrontPacketState 0;
BA_ "Confidence" SG_ 1056 UIS_cameraBackupStreamQuality 1;
BA_ "Confidence" SG_ 1056 UIS_cameraBackupStreamMissing 0;
BA_ "Confidence" SG_ 1056 UIS_cameraBackupRenderState 0;
BA_ "Confidence" SG_ 1056 UIS_cameraBackupPopup 0;
BA_ "Confidence" SG_ 1056 UIS_cameraBackupPipeline 0;
BA_ "Confidence" SG_ 1056 UIS_cameraBackupPacketState 0;
BA_ "Confidence" SG_ 1056 UIS_pmSuspendHookIndex 1;
BA_ "Confidence" SG_ 1056 UIS_cameraBackupFramerate 0;
BA_ "Confidence" SG_ 1056 UIS_boardTemperature 0;
BA_ "Confidence" SG_ 1056 UIS_bluetoothState 0;
BA_ "Confidence" SG_ 1056 UIS_bluetoothStackState 0;
BA_ "Confidence" SG_ 1056 UIS_bluetoothStackRearState 0;
BA_ "Confidence" SG_ 1056 UIS_bluetoothPairResult 0;
BA_ "Confidence" SG_ 1056 UIS_bluetoothMemUsage 0;
BA_ "Confidence" SG_ 1056 UIS_bluetoothConnectionState 0;
BA_ "Confidence" SG_ 1056 UIS_bluetoothCPUUsage 0;
BA_ "Confidence" SG_ 1056 UIS_bluetoothAutoconnectAttempts 0;
BA_ "Confidence" SG_ 1056 UIS_bluetoothAutoconnectActive 0;
BA_ "Confidence" SG_ 1056 UIS_bluetoothAutoConnectionState 0;
BA_ "Confidence" SG_ 1056 UIS_backlightUserRequest 0;
BA_ "Confidence" SG_ 1056 UIS_audioVolumeLevel 0;
BA_ "Confidence" SG_ 1056 UIS_audioType 0;
BA_ "Confidence" SG_ 1056 UIS_audioState 0;
BA_ "Confidence" SG_ 1056 UIS_audioSource 0;
BA_ "Confidence" SG_ 1056 UIS_audioPWSGain 0;
BA_ "Confidence" SG_ 1056 UIS_audioMediaPlaying 0;
BA_ "Confidence" SG_ 1056 UIS_audioMediaBrowsing 0;
BA_ "Confidence" SG_ 1056 UIS_audioA2BRediscoveryCount 0;
BA_ "Confidence" SG_ 1056 UIS_apeHardwareMinorVersion 0;
BA_ "Confidence" SG_ 1056 UIS_activeAppView 0;
BA_ "Confidence" SG_ 1056 UIS_CamViewerServiceEnabled 0;
BA_ "Confidence" SG_ 979 UI_airbagCutoffSwState 0;
BA_ "GenSigSNA" SG_ 979 UI_airbagCutoffSwState "2";
BA_ "Confidence" SG_ 979 UI_warningIndicatorStatus 1;
BA_ "GenSigSNA" SG_ 979 UI_warningIndicatorStatus "3";
BA_ "Confidence" SG_ 1523 UI_alertID 1;
BA_ "Confidence" SG_ 1523 UI_alertState 1;
BA_ "Confidence" SG_ 1523 UI_a009_squashfsDevice 1;
BA_ "Confidence" SG_ 1523 UI_a036_audioWatchdogReason 1;
BA_ "SystemSignalLongSymbol" SG_ 1523 UI_a045_ManualECallButtonDisconn "UI_a045_ManualECallButtonDisconnected";
BA_ "Confidence" SG_ 1523 UI_a087_BmpResetType 1;
BA_ "Confidence" SG_ 1523 UI_a131_DisplayPortFailureType 1;
BA_ "Confidence" SG_ 1523 UI_a147_whichASIL 1;
BA_ "Confidence" SG_ 1523 UI_a147_errorCode 1;
BA_ "Confidence" SG_ 1523 UI_a148_sleepType 1;
BA_ "Confidence" SG_ 1523 UI_a148_lastFailedPmSuspendDev 1;
BA_ "Confidence" SG_ 1523 UI_a149_displayType 1;
BA_ "Confidence" SG_ 1523 UI_a149_displaySeat 1;
BA_ "Confidence" SG_ 1523 UI_a149_errorCode 1;
BA_ "Confidence" SG_ 1523 UI_a153_processName 1;
BA_ "Confidence" SG_ 1523 UI_a153_restartReason 1;
BA_ "Confidence" SG_ 1523 UI_a158_UsbDeviceMountErrorCode 1;
BA_ "Confidence" SG_ 1523 UI_a165_fsCorruptedDevice 1;
BA_ "Confidence" SG_ 1523 UI_a166_fsErrorDevice 1;
BA_ "Confidence" SG_ 1523 UI_a167_processId 1;
BA_ "Confidence" SG_ 1523 UI_a173_errorCode 1;
BA_ "Confidence" SG_ 1523 UI_a173_lastFailedPmSuspendDev 1;
BA_ "Confidence" SG_ 1523 UI_a176_PrimaryAntenna 1;
BA_ "Confidence" SG_ 1523 UI_a176_SecondaryAntenna 1;
BA_ "Confidence" SG_ 1523 UI_a176_TertiaryAntenna 1;
BA_ "Confidence" SG_ 1523 UI_a177_errorCode 1;
BA_ "Confidence" SG_ 1523 UI_a177_errorSource 1;
BA_ "Confidence" SG_ 1523 UI_a192_AudioRebootState 1;
BA_ "Confidence" SG_ 1523 UI_a204_ModemSleepFailureReason 1;
BA_ "SystemSignalLongSymbol" SG_ 1523 UI_a208_mqttClientDisconnectReas "UI_a208_mqttClientDisconnectReason";
BA_ "Confidence" SG_ 1523 UI_a214_lastFailedPmSuspendDev 1;
BA_ "Confidence" SG_ 1523 UI_a216_circuitProblem 1;
BA_ "Confidence" SG_ 1523 UI_a216_circuitNode 1;
BA_ "Confidence" SG_ 1523 UI_a217_cgroupName 1;
BA_ "Confidence" SG_ 1523 UI_a220_errorCode 1;
BA_ "Confidence" SG_ 1523 UI_a221_errorCode 1;
BA_ "Confidence" SG_ 1523 UI_a221_networkErrorCode 1;
BA_ "GenSigSNA" SG_ 1523 UI_a221_networkErrorCode "500";
BA_ "Confidence" SG_ 1523 UI_a222_errorCode 1;
BA_ "Confidence" SG_ 1523 UI_a223_database 1;
BA_ "Confidence" SG_ 1523 UI_a229_errorCode 1;
BA_ "Confidence" SG_ 1523 UI_a231_sleepType 1;
BA_ "Confidence" SG_ 1523 UI_a232_processExited 1;
BA_ "Confidence" SG_ 1523 UI_a232_processSignal 1;
BA_ "Confidence" SG_ 1523 UI_a240_ethErrorType 1;
BA_ "SystemSignalLongSymbol" SG_ 1523 UI_a242_ConnectivityFaultInjecte "UI_a242_ConnectivityFaultInjected";
BA_ "SystemSignalLongSymbol" SG_ 1523 UI_a242_ConnectivityHWFaultInjec "UI_a242_ConnectivityHWFaultInjected";
BA_ "SystemSignalLongSymbol" SG_ 1523 UI_a242_CenterDispStatusFaultInj "UI_a242_CenterDispStatusFaultInjected";
BA_ "Confidence" SG_ 1523 UI_a247_displayType 1;
BA_ "Confidence" SG_ 1523 UI_a247_displaySeat 1;
BA_ "Confidence" SG_ 1523 UI_a257_ModemRebootReason 1;
BA_ "Confidence" SG_ 1523 UI_a257_ModemRebootEthPresent 1;
BA_ "Confidence" SG_ 1523 UI_a261_bluetoothStackPanicReaso 1;
BA_ "SystemSignalLongSymbol" SG_ 1523 UI_a261_bluetoothStackPanicReaso "UI_a261_bluetoothStackPanicReason";
BA_ "Confidence" SG_ 1523 UI_a274_hintCardType 1;
BA_ "Confidence" SG_ 1523 UI_a274_hintCardDismissOutcome 1;
BA_ "SystemSignalLongSymbol" SG_ 291 UI_a037_AudioWatchdogXrunStormEr "UI_a037_AudioWatchdogXrunStormError";
BA_ "SystemSignalLongSymbol" SG_ 291 UI_a038_AudioWatchdogA2bI2cLocku "UI_a038_AudioWatchdogA2bI2cLockupError";
BA_ "SystemSignalLongSymbol" SG_ 291 UI_a048_AudioPremiumAmpCheckFail "UI_a048_AudioPremiumAmpCheckFailed";
BA_ "SystemSignalLongSymbol" SG_ 291 UI_a056_ManualECallButtonDisconn "UI_a056_ManualECallButtonDisconnected";
BA_ "SystemSignalLongSymbol" SG_ 292 UI_a078_DashcamUsbDriveUnmountab "UI_a078_DashcamUsbDriveUnmountable";
BA_ "SystemSignalLongSymbol" SG_ 292 UI_a082_NumModemRebootStuckInECa "UI_a082_NumModemRebootStuckInECall";
BA_ "SystemSignalLongSymbol" SG_ 292 UI_a083_ECallProxyWatchdogTrigge "UI_a083_ECallProxyWatchdogTriggered";
BA_ "SystemSignalLongSymbol" SG_ 292 UI_a096_VideodPipelineIssueDetec "UI_a096_VideodPipelineIssueDetected";
BA_ "SystemSignalLongSymbol" SG_ 292 UI_a105_firmwareReinstallRequest "UI_a105_firmwareReinstallRequested";
BA_ "SystemSignalLongSymbol" SG_ 292 UI_a107_DashcamUsbDriveTooBigFor "UI_a107_DashcamUsbDriveTooBigForVfatFsck";
BA_ "SystemSignalLongSymbol" SG_ 292 UI_a108_DashcamUsbDriveGettingFu "UI_a108_DashcamUsbDriveGettingFull";
BA_ "SystemSignalLongSymbol" SG_ 292 UI_a111_DashcamUsbDriveNotSuperS "UI_a111_DashcamUsbDriveNotSuperSpeed";
BA_ "SystemSignalLongSymbol" SG_ 292 UI_a113_DashcamHasOnboardSentryC "UI_a113_DashcamHasOnboardSentryClips";
BA_ "SystemSignalLongSymbol" SG_ 292 UI_a114_drivingVisualizationDegr "UI_a114_drivingVisualizationDegraded";
BA_ "SystemSignalLongSymbol" SG_ 292 UI_a120_nvmePCIeLinkErrorDetecte "UI_a120_nvmePCIeLinkErrorDetected";
VAL_ 1056 UIS_logMux 451 "CamViewerServiceEnabled" 450 "activeAppView" 449 "amdSocPkgPower" 448 "apeHardwareMinorVersion" 447 "audioA2BRediscoveryCount" 446 "audioMediaBrowsing" 445 "audioMediaPlaying" 444 "audioPWSGain" 443 "audioSource" 442 "audioState" 441 "audioType" 440 "audioVolumeLevel" 439 "backlightUserRequest" 438 "bifrostCPUUsage" 437 "bifrostMemUsage" 436 "bifrostOdinEngineRequests" 435 "bifrostOdinEngineUp" 434 "bluetoothAutoConnectionState" 433 "bluetoothAutoconnectActive" 432 "bluetoothAutoconnectAttempts" 431 "bluetoothCPUUsage" 430 "bluetoothConnectionState" 429 "bluetoothMemUsage" 428 "bluetoothPairResult" 427 "bluetoothStackRearState" 426 "bluetoothStackState" 425 "bluetoothState" 424 "boardTemperature" 423 "bootCount" 422 "camBackupDecodeAvgFrametime" 421 "camBackupDecodeFramecount" 420 "camBackupDecodeMaxFrametime" 419 "camBackupDecodeMinFrametime" 418 "cameraBackupFramerate" 417 "cameraBackupLateFrames" 416 "pmSuspendHookIndex" 415 "cameraBackupMaxFrametime" 414 "cameraBackupPacketState" 413 "cameraBackupPipeline" 412 "cameraBackupPopup" 411 "cameraBackupRenderState" 410 "cameraBackupStreamMissing" 409 "cameraBackupStreamQuality" 408 "cameraFrontPacketState" 407 "cameraFrontPipeline" 406 "cameraFrontPopup" 405 "cameraFrontRenderState" 404 "cameraFrontStreamMissing" 403 "cameraLDownwardPacketState" 402 "cameraLDownwardPipeline" 401 "cameraLDownwardRenderState" 400 "cameraLRepeaterFramerate" 399 "cameraLRepeaterLateFrames" 398 "cameraLRepeaterMaxFrametime" 397 "cameraLRepeaterPacketState" 396 "cameraLRepeaterPipeline" 395 "cameraLRepeaterPopup" 394 "cameraLRepeaterRenderState" 393 "cameraLRepeaterStreamMissing" 392 "cameraRDownwardPacketState" 391 "cameraRDownwardPipeline" 390 "cameraRDownwardRenderState" 389 "cameraRRepeaterFramerate" 388 "cameraRRepeaterLateFrames" 387 "cameraRRepeaterMaxFrametime" 386 "cameraRRepeaterPacketState" 385 "cameraRRepeaterPipeline" 384 "cameraRRepeaterPopup" 383 "cameraRRepeaterRenderState" 382 "cameraRRepeaterStreamMissing" 381 "cameraRearViewPacketState" 380 "cameraRearViewPipeline" 379 "cameraRearViewPopup" 378 "cameraRearViewRenderState" 377 "cameraRearViewStreamMissing" 376 "cameraSelectablePacketState" 375 "cameraSelectablePipeline" 374 "cameraSelectableRenderState" 373 "carAssistErrorCode" 372 "carAssistMicAlsaRms" 371 "carAssistMicMuted" 370 "carAssistSessionCount" 369 "carAssistState" 341 "cellularConnectivityStatus" 340 "cellularLinkManagerState" 339 "centerDispAsilA_lsb" 338 "centerDispAsilA_msb" 337 "centerDispAsilB_lsb" 336 "centerDispAsilB_msb" 335 "centerDisplayEvent" 334 "centerDisplayState" 333 "ceruleanx8664CPUUsage" 332 "ceruleanx8664MemUsage" 331 "chargeLocationId" 330 "chargeOnSolarNoChargeReason" 329 "chromiumadapterCPUUsage" 328 "chromiumadapterMemUsage" 327 "clusterCPUUsage" 326 "clusterDisplayState" 325 "clusterFramesOver100Ms" 324 "clusterFramesOver200Ms" 323 "clusterMaxFrametime" 322 "clusterMeanFPS" 321 "clusterMemUsage" 320 "cobaltlinuxCPUUsage" 319 "cobaltlinuxMemUsage" 318 "compositorFrameMonitorState" 317 "compositorRenderAvgRenderTime" 316 "compositorRenderFrameCount" 315 "compositorRenderFrameRate" 314 "compositorRenderGpuPercentage" 313 "compositorRenderMaxFrameTime" 312 "compositorRenderMaxRenderTime" 311 "compositorRenderMinFrameTime" 310 "compositorRenderMinRenderTime" 309 "connectedToInternet" 308 "cpuTemperature" 307 "dasAutonomyControlMessageMiaInDriverlessTakeover" 306 "dashcamOnboardAvailableMB" 305 "dashcamOnboardMB" 304 "dashcamOnboardSavePressCount" 303 "dashcamOnboardTransferCount" 302 "dashcamSavedToOnboardCount" 301 "dashcamSavedToSavedCount" 300 "dashcamSavedToSentryCount" 299 "dashcamState" 298 "dashcamStorageAvailableMB" 297 "dashcamStorageRecentMB" 296 "dashcamStorageSavedMB" 295 "dashcamStorageSentryMB" 294 "dashcamStorageState" 293 "dashcamTransferCount" 292 "dashcamTransferFileCount" 291 "dashcamTransferRateMBps" 290 "dashcamTransferSizeMB" 289 "dashcamTransferTimeMs" 288 "dashcamviewerCPUUsage" 287 "dashcamviewerMemUsage" 286 "developerMode" 285 "dgpuTemperature" 284 "dmCenterAsilCalibrationSync" 283 "dmCenterAsilFirmwareStatus" 282 "dmCenterAsilOpenFlag" 281 "dmCenterAsilResumeFlag" 280 "dmCenterAsilShortFlag" 279 "dmCenterBacklightControlDeferred" 278 "dmCenterBacklightDevExists" 277 "dmCenterBacklightDutyCycle" 276 "dmCenterBacklightFault" 275 "dmCenterBacklightNits" 274 "dmCenterBacklightPowerLevel" 273 "dmCenterConnected" 272 "dmCenterEnabled" 271 "dmCenterLinkCheckOk" 270 "dmCenterMOsdExactCrcCheck" 269 "dmCenterMOsdVideoCrcData" 268 "dmCenterModeSettingStatus" 267 "dmCenterOsdDayNightState" 266 "dmCenterOsdDisplayedState" 265 "dmCenterPowerState" 264 "dmCenterSOsdExactCrcCheck" 263 "dmCenterSOsdVideoCrcData" 262 "dmCenterTouchDeviceExists" 261 "dmCenterTouchIrqCount" 260 "dmGatewayLinkWedged" 259 "dmIcuAsilFirmwareStatus" 258 "dmIcuAsilOpenFlag" 257 "dmIcuAsilResumeFlag" 256 "dmIcuAsilShortFlag" 255 "dmIcuBacklightDevExists" 254 "dmIcuBacklightDutyCycle" 253 "dmIcuBacklightFault" 252 "dmIcuBacklightNits" 251 "dmIcuBacklightPowerLevel" 250 "dmIcuConnected" 249 "dmIcuEnabled" 248 "dmIcuLinkCheckOk" 247 "dmIcuPowerState" 246 "dmIcuTouchIrqCount" 245 "dmRearAsilStatusLsb" 244 "dmRearAsilStatusMsb" 243 "dmRearBacklightDevExists" 242 "dmRearBacklightDutyCycle" 241 "dmRearBacklightFault" 240 "dmRearBacklightNits" 239 "dmRearBacklightPowerLevel" 238 "dmRearConnected" 237 "dmRearEnabled" 236 "dmRearLinkCheckOk" 235 "dmRearPowerState" 234 "dmRearTouchDeviceExists" 233 "dumTclipClipCount" 232 "dumTclipSuccessfulUploadCount" 231 "dumTclipTransferCount" 230 "dumTclipUploadActive" 229 "dumTclipUploadState" 228 "dynamicTriggersCampaignState" 227 "dynamicTriggersHRLServiceState" 226 "dynamicTriggersOutputManagerServiceState" 225 "dynamicTriggersTelemetryServiceState" 224 "embeddedGameName" 223 "embeddedGameState" 222 "estimatedOccupancyCount" 221 "featureSuperchargingEnabled" 220 "firmwareReleaseScope" 219 "godotCPUUsage" 218 "godotMemUsage" 217 "godot_MEMORY_DYNAMIC" 216 "godot_MEMORY_STATIC" 215 "godot_TIME_FPS" 214 "godot_TIME_PROCESS" 213 "gpsmanagerCPUUsage" 212 "gpsmanagerMemUsage" 211 "gtwSocUartRxStatBadChecksum" 210 "gtwSocUartRxStatBadTooBig" 209 "gtwSocUartRxStatBadTooSmall" 208 "gtwSocUartRxStatHandleErr" 207 "gtwSocUartRxStatHeartbeats" 206 "gtwSocUartRxStatMsgErr" 205 "gtwSocUartRxStatUnhandled" 204 "gtwSocUartRxStatValidPackets" 203 "gtwSocUartTxStatAnsMismatch" 202 "gtwSocUartTxStatBadTooBig" 201 "gtwSocUartTxStatNacks" 200 "gtwSocUartTxStatPackets" 199 "gtwSocUartTxStatTimeouts" 198 "headsetConnectionState" 197 "headsetPairResult" 196 "hermesclientCPUUsage" 195 "hermesclientMemUsage" 194 "hermesdynamicCPUUsage" 193 "hermesdynamicMemUsage" 192 "hicarAudioSetupState" 191 "hicarAudioTeardownState" 190 "hicarCallState" 189 "hicarConnectionState" 188 "hicarDataReceiveType" 187 "hicarErrorCode" 186 "hicarEventCode" 185 "hicarServiceState" 184 "homelinkState" 183 "igpuTemperature" 182 "inSuperchargerGeofence" 181 "limex8664CPUUsage" 180 "limex8664MemUsage" 179 "mediaImageCacheCost" 178 "mediaImageCacheSize" 177 "mediaNeedAuthToken" 176 "mediaPlaybackStatus" 175 "mediaserveCPUUsage" 174 "mediaserveMemUsage" 173 "mirrorGeofenceActive" 172 "modemBusyActive" 171 "modemECallppAvail" 170 "mounterdDashcamCapacityGB" 169 "mounterdDeviceCount" 168 "mounterdEncryptionCapacityGB" 167 "mounterdFilesystemCountExfat" 166 "mounterdFilesystemCountExt3" 165 "mounterdFilesystemCountExt4" 164 "mounterdFilesystemCountFat32" 163 "mounterdFrontHubConnected" 162 "mounterdFrontHubDisconnected" 161 "mounterdMountCountTotal" 160 "mounterdState" 159 "muteNavVolume" 158 "navAudioVolume" 157 "navServiceError" 156 "netCellRxCount" 155 "netCellRxRate" 154 "netCellTxCount" 153 "netCellTxRate" 152 "netEthRxCount" 151 "netEthRxDroppedCount" 150 "netEthRxDroppedRate" 149 "netEthRxErrorCount" 148 "netEthRxErrorRate" 147 "netEthRxRate" 146 "netEthTxCount" 145 "netEthTxRate" 144 "netWifiRxCount" 143 "netWifiRxRate" 142 "netWifiTxCount" 141 "netWifiTxRate" 140 "nuanceserverCPUUsage" 139 "nuanceserverMemUsage" 138 "numCorrMemErrorsECC" 137 "numUncorrMemErrorsECC" 136 "nvmeDataUnitsWritten100mb" 135 "nvmePercentLifetimeUsed" 134 "nvmeTemperature" 133 "odinAuthCount" 132 "odinAuthFailCount" 131 "odinCPUUsage" 130 "odinEcuLogForceTriggerUploadState" 129 "odinEcuLogUploadState" 128 "odinFileSystemState" 127 "odinGatewayConnectionState" 126 "odinHermesConnectionState" 125 "odinHrlLogUploadState" 124 "odinHrlUploadLimits" 123 "odinListTasksCmdDurationMs" 122 "odinListTasksCmdResult" 121 "odinMemUsage" 120 "odinNetworkFailCount" 119 "odinNetworkStartCount" 118 "odinOrchestratorFailCount" 117 "odinOrchestratorStartCount" 116 "odinPeriodicTaskState" 115 "odinProcessState" 114 "odinStatusCmdDurationMs" 113 "odinStatusCmdResult" 112 "polytopiax8664CPUUsage" 111 "polytopiax8664MemUsage" 110 "powerManagerState" 109 "psiCpuSome" 108 "psiIOFull" 107 "psiIOSome" 106 "psiMemFull" 105 "psiMemSome" 104 "qtcarCPUUsage" 103 "qtcarMemUsage" 102 "radioserveCPUUsage" 101 "radioserveMemUsage" 100 "rearDisplayState" 99 "rearDisplayUserPresent" 98 "releasenotesCPUUsage" 97 "releasenotesMemUsage" 96 "remoteRequestType" 95 "robotaxiModeActive" 94 "scheduleChargeEndTime" 93 "scheduleChargeStartTime" 92 "scheduledChargingMode" 91 "sentryIncidentCount" 90 "sentryNeedsNap" 89 "sentryState" 88 "serverCPUUsage" 87 "serverMemUsage" 86 "serviceMode" 85 "serviceModePlus" 84 "settingsAutoTurnSignal" 83 "slackerLoginResult" 82 "sleepCount" 81 "sleepState" 80 "sleepTime" 79 "sleepType" 78 "softwareInstallPopupStatus" 77 "softwareUpdatePrimDownload" 76 "softwareUpdateState" 75 "solitaireCPUUsage" 74 "solitaireMemUsage" 73 "speechrecoCPUUsage" 72 "speechrecoMemUsage" 71 "spotifyserverCPUUsage" 70 "spotifyserverMemUsage" 69 "sudokuCPUUsage" 68 "sudokuMemUsage" 67 "superchargePaymentNeeded" 66 "suspensionGeofence" 65 "systemMemSwapUsage" 64 "systemUptime" 63 "systemWakeTime" 62 "tegraModemManState" 61 "teleopAvgPacketDelta" 60 "teleopMaxPacketDelta" 59 "teleopMinPacketDelta" 58 "teleopPacketDrops" 57 "teleopPhoneCallActive" 56 "teleopStreamXrunCount" 55 "teslaMediaCacheCost" 54 "teslaMediaCacheSize" 53 "teslachromiumCPUUsage" 52 "teslachromiumMemUsage" 51 "testDriveMode" 50 "thermalProfile" 49 "thermalResistance" 48 "tmserverCPUUsage" 47 "tmserverMemUsage" 46 "touchEventsAggCount" 45 "tunerCurrentAntenna1" 44 "tunerCurrentAntenna2" 43 "tunerTemperatureCelsius" 42 "tunerTemperatureFahrenheit" 41 "tunerVoltage1V8" 40 "tunerVoltage3V3" 39 "tunerVoltageAntenna1" 38 "tunerVoltageAntenna2" 37 "tunerVoltageMQS" 36 "tunerVoltageOperation" 35 "tunerVoltageUBatt" 34 "uiFramesOver100Ms" 33 "uiFramesOver200Ms" 32 "uiFrametimeGearShiftDToR" 31 "uiFrametimeGearShiftPToR" 30 "uiMaxFrametime" 29 "uiMeanFPS" 28 "uiQtCarSwapUsage" 27 "uiQtCarUptime" 26 "valetMode" 25 "valhallaserverCPUUsage" 24 "valhallaserverMemUsage" 23 "vehicleCPUUsage" 22 "vehicleMemUsage" 21 "videodCPUUsage" 20 "videodMemUsage" 19 "vmtouchCPUUsage" 18 "vmtouchMemUsage" 17 "webbrowserCPUUsage" 16 "webbrowserMemUsage" 15 "wifiAutoJoinLowRSSI" 14 "wifiBars" 13 "wifiStackReady" 12 "wifiStackState" 11 "wifiTemperature" 10 "zramCompressedSize" 9 "zramCompressionRatio" 8 "zramFailedReads" 7 "zramFailedWrites" 6 "zramInvalidIO" 5 "zramNotifyFree" 4 "zramOriginalSize" 3 "zramReadIO" 2 "zramReadTicks" 1 "zramWriteIO" 0 "zramWriteTicks" ;
VAL_ 1056 UIS_wifiStackState 17 "WL_RESET_CONNMAN" 16 "WL_RUNNING_LOCAL" 15 "WL_CAPTIVE" 14 "WL_DISCONNECTING" 13 "WL_RUNNING" 12 "WL_WAITING_ONLINE" 11 "WL_CHECKING" 10 "WL_CONFIGURING" 9 "WL_CONNECTING" 8 "WL_SELECTING_NETWORK" 7 "WL_WAITING_AUTOCONNECT" 6 "WL_SEARCHING" 5 "WL_POWERING_ON" 4 "WL_DISABLED_WAIT" 3 "WL_POWERING_OFF" 2 "WL_WAITING_TECHNOLOGY" 1 "WL_RESETTING" 0 "DEFAULT" ;
VAL_ 1056 UIS_wifiStackReady 1 "TRUE" 0 "FALSE" ;
VAL_ 1056 UIS_wifiAutoJoinLowRSSI 1 "TRUE" 0 "FALSE" ;
VAL_ 1056 UIS_valetMode 1 "TRUE" 0 "FALSE" ;
VAL_ 1056 UIS_thermalProfile 11 "FACTORY_HOT" 10 "FACTORY_WARM" 9 "FACTORY_IDLE" 8 "FACTORY_COLD" 7 "INFOTAINMENT_OVERHEAT" 6 "INFOTAINMENT_THROTTLE" 5 "INFOTAINMENT_THRESHOLD" 4 "INFOTAINMENT_HOT" 3 "INFOTAINMENT_WARM" 2 "INFOTAINMENT_IDLE" 1 "INFOTAINMENT_COLD" 0 "SNA" ;
VAL_ 1056 UIS_testDriveMode 1 "ENABLED" 0 "DISABLED" ;
VAL_ 1056 UIS_tegraModemManState 20 "INVALID" 19 "CHECKINGMODEM" 18 "CHECKINGPORTS" 17 "STOPPINGLINK" 16 "UNCONFIGURINGLINK" 15 "RUNNINGSTATUS" 14 "RUNNING" 13 "CHECKINGLINK" 12 "CONFIGURINGLINK" 11 "RETRYINGLINK" 10 "STARTINLINK" 9 "PRECONDITIONINGLINK" 8 "INITIALIZING2" 7 "CHECKINGANTENNA" 6 "ENABLINGSIM" 5 "INITIALIZING1" 4 "RECOVERING" 3 "WAKING" 2 "SLEEPING" 1 "RESTARTING" 0 "ABORTINGLINK" ;
VAL_ 1056 UIS_suspensionGeofence 1 "REQUESTED" 0 "REMOVED" ;
VAL_ 1056 UIS_softwareUpdateState 11 "POST_INSTALL_START" 10 "COMPLETE" 9 "GATEWAY_DONE" 8 "GATEWAY_START" 7 "APE_B" 6 "APE" 5 "STAGED" 4 "GAME" 3 "SECONDARY" 2 "GOOD_SIG" 1 "PRIMARY" 0 "INIT" ;
VAL_ 1056 UIS_softwareUpdatePrimDownload 3 "FAILURE" 2 "SUCCESS" 1 "IN_PROGRESS" 0 "IDLE" ;
VAL_ 1056 UIS_softwareInstallPopupStatus 3 "INSTALLING" 2 "PRESENT" 1 "COUNTDOWN" 0 "NONE" ;
VAL_ 1056 UIS_sleepType 4 "Unknown" 3 "ModernStandby" 2 "S2Idle" 1 "S3" 0 "Shallow" ;
VAL_ 1056 UIS_sleepState 3 "Wake" 2 "Sleep" 1 "Run" 0 "Boot" ;
VAL_ 1056 UIS_slackerLoginResult 5000 "SLACKER_LOGIN_CREDENTIALS_MISSING" 444 "SLACKER_LOGIN_USER_BUMPED" 412 "SLACKER_LOGIN_TOKEN_INVALID_TIMESTAMP" 409 "SLACKER_LOGIN_TOKEN_REVOKED_KEY" 403 "SLACKER_LOGIN_CAPTCHA_REQUIRED" 401 "SLACKER_LOGIN_INCORRECT_CREDENTIALS" 400 "SLACKER_LOGIN_TOKEN_INVALID_SIGNATURE" 6 "SLACKER_LOGIN_BAD_ACCOUNT_LEVEL" 5 "SLACKER_LOGIN_OTHER_ERROR" 4 "SLACKER_LOGIN_NET_ERROR" 3 "SLACKER_LOGIN_TOKEN_UNKNOWN_ERROR" 2 "SLACKER_LOGIN_SUCCESS" 1 "SLACKER_LOGIN_SERVERTIME_FAILED" ;
VAL_ 1056 UIS_settingsAutoTurnSignal 1 "AUTO_CANCEL" 0 "OFF" ;
VAL_ 1056 UIS_sentryState 5 "QUIET" 4 "PANIC" 3 "AWARE" 2 "ARMED" 1 "IDLE" 0 "OFF" ;
VAL_ 1056 UIS_scheduledChargingMode 3 "TIME_WINDOW" 2 "END_BY" 1 "START_AT" 0 "OFF" ;
VAL_ 1056 UIS_remoteRequestType 106 "NAV_GPS_DESTINATION_REQUEST" 105 "TESLA_AUTH_RESPONSE" 104 "GET_MESSAGE" 103 "SET_LIGHTBAR_DITCH" 102 "SET_LIGHTBAR_MIDDLE" 101 "SET_LIGHTBAR_BRIGHTNESS" 100 "REMOVE_PRECONDITION_SCHEDULE" 99 "ADD_PRECONDITION_SCHEDULE" 98 "REMOVE_CHARGE_SCHEDULE" 97 "ADD_CHARGE_SCHEDULE" 96 "SET_REAR_ZONE_LIGHT_REQUEST" 95 "SET_FRONT_ZONE_LIGHT_REQUEST" 94 "SET_TENT_MODE_REQUEST" 93 "SET_POWERSHARE_REQUEST" 92 "SET_POWERSHARE_DISCHARGE_LIMIT" 91 "SET_POWERSHARE_FEATURE" 90 "NAVIGATION_WAYPOINTS_REQUEST" 89 "VEHICLE_CONTROL_RESET_PIN_TO_DRIVE_ADMIN" 88 "SET_TRUCK_BED_LIGHT_BRIGHTNESS" 87 "SET_TRUCK_BED_LIGHT_AUTO_STATE" 86 "SET_TRAILER_LIGHT_TEST_START_STOP" 85 "SET_POWER_FEED_SOC_LIMIT" 84 "SET_POWER_FEED_TIMER" 83 "SET_POWER_FEED_ON_OFF" 82 "SET_OUTLET_SOC_LIMIT" 81 "SET_OUTLET_TIMER" 80 "SET_OUTLETS_ON_OFF" 79 "DRIVING_CLEAR_SPEED_LIMIT_PIN_ADMIN" 78 "VEHICLE_CONTROL_RESET_PIN_TO_DRIVE" 77 "VEHICLE_CONTROL_SET_PIN_TO_DRIVE" 76 "RESERVED_SEVENTY_SIX" 75 "GET_CHARGE_ON_SOLAR_FEATURE" 74 "UPDATE_CHARGE_ON_SOLAR_FEATURE" 73 "GET_MANAGED_CHARGING_SITES" 72 "ERASE_USER_DATA" 71 "STW_HEAT_LEVEL" 70 "AUTO_STW_HEAT" 69 "NAVIGATION_ROUTE" 68 "REMOVE_MANAGED_CHARGING_SITE" 67 "ADD_MANAGED_CHARGING_SITE" 66 "SET_COP_TEMP" 65 "GUEST_MODE" 64 "BOOMBOX" 63 "BLUETOOTH_CLASSIC_PAIRING_REQUEST" 62 "CHARGE_PORT_DOOR_OPEN" 61 "CHARGE_PORT_DOOR_CLOSE" 60 "RESERVED_SIXTY" 59 "RESERVED_FIFTY_NINE" 58 "TAKE_DRIVENOTE" 57 "VIDEO_REQUEST" 56 "GET_RATE_TARIFF" 55 "RESERVED_FIFTY_FIVE" 54 "SET_VEHICLE_NAME" 53 "NAVIGATION_GPS_REQUEST" 52 "PSEUDONYM_SYNC_REQUEST" 51 "PII_KEY_REQUEST" 50 "SET_CABIN_OVERHEAT_PROTECTION" 49 "HVAC_SEAT_COOLER_ACTIONS" 48 "AUTO_SEAT_CLIMATE" 47 "DASHCAM_SAVE_CLIP" 46 "PING" 45 "HVAC_RECIRCULATION" 44 "HVAC_CLIMATE_KEEPER" 43 "SET_CHARGING_AMPS" 42 "SCHEDULED_DEPARTURE" 41 "SCHEDULED_CHARGING" 40 "VITALS_ACK" 39 "VITALS_SUBSCRIPTION" 38 "VEHICLE_DATA_ACK" 37 "VEHICLE_DATA_SUBSCRIPTION" 36 "HVAC_SEAT_HEATER_ACTIONS" 35 "HVAC_BIO_WEAPON_MODE" 34 "VEHICLE_CONTROL_WINDOW" 33 "VEHICLE_CONTROL_TRIGGER_HOMELINK" 32 "VEHICLE_CONTROL_SUNROOF_OPEN_CLOSE" 31 "VEHICLE_CONTROL_SET_VALET_MODE" 30 "VEHICLE_CONTROL_SET_SENTRY_MODE" 29 "VEHICLE_CONTROL_SCHEDULE_SOFTWARE_UPDATE" 28 "VEHICLE_CONTROL_RESET_VALET_PIN" 27 "VEHICLE_CONTROL_HONK_HORN" 26 "VEHICLE_CONTROL_FLASH_LIGHTS" 25 "VEHICLE_CONTROL_CANCEL_SOFTWARE_UPDATE" 24 "UI_SET_UPCOMING_CALENDAR_ENTRIES" 23 "GET_NEARBY_CHARGING_SITES" 22 "NAVIGATION_SUPERCHARGER_REQUEST" 21 "NAVIGATION_REQUEST" 20 "MEDIA_PREVIOUS_TRACK" 19 "MEDIA_NEXT_TRACK" 18 "MEDIA_PREVIOUS_FAVORITE" 17 "MEDIA_NEXT_FAVORITE" 16 "MEDIA_UPDATE_VOLUME" 15 "MEDIA_PLAY" 14 "HVAC_TEMPERATURE_ADJUSTMENT" 13 "HVAC_STEERING_WHEEL_HEATER" 12 "HVAC_SET_PRECONDITIONING_MAX" 11 "RESERVED_ELEVEN" 10 "HVAC_AUTO" 9 "DRIVING_SPEED_LIMIT" 8 "DRIVING_SET_SPEED_LIMIT" 7 "DRIVING_CLEAR_SPEED_LIMIT_PIN" 6 "CHARGING_START_STOP" 5 "CHARGING_SET_LIMIT" 4 "STREAM_MESSAGE" 3 "CREATE_STREAM_SESSION" 2 "REMOTE_START_DRIVE" 1 "GET_VEHICLE_DATA" 0 "UNKNOWN" ;
VAL_ 1056 UIS_rearDisplayUserPresent 1 "TRUE" 0 "FALSE" ;
VAL_ 1056 UIS_rearDisplayState 9 "ENTERTAINMENT" 8 "DOG" 7 "SENTRY" 6 "LOCK" 5 "CHARGING" 4 "DRIVING" 3 "ON" 2 "ACCESSORY" 1 "DIM" 0 "OFF" ;
VAL_ 1056 UIS_powerManagerState 31 "PMS_ENTERINGROBOTAXILOADSHED" 30 "PMS_ROBOTAXILOADSHEDDING" 29 "PMS_UPLOADDATA" 28 "PMS_EXTREMELOADSHEDDING" 27 "PMS_ENTERINGEXTREMELOADSHED" 26 "PMS_PREPARINGSLEEP" 25 "PMS_ENTERINGLOADSHED" 24 "PMS_SENTRYACTIVE" 23 "PMS_EXITINGLOADSHED" 22 "PMS_LOADSHEDDING" 21 "PMS_EXITINGSENTRY" 20 "PMS_SENTRYARMED" 19 "PMS_ENTERINGSENTRY" 18 "PMS_UNKNOWN_SNA" 17 "PMS_EXITINGSLEEP" 16 "PMS_READYFORSLEEP" 15 "PMS_WAITINGONRAILS" 14 "PMS_PERFORMANCE" 13 "PMS_HIGHPOWERSTARTED" 12 "PMS_HIGHPOWERSTOPPING" 11 "PMS_HIGHPOWERSTARTING" 10 "PMS_REBOOT" 9 "PMS_ENTERINGSLEEP" 8 "PMS_ALLTUCKEDIN" 7 "PMS_CHARGING" 6 "PMS_AUDIOSTOPPED" 5 "PMS_AUDIOSTOPPING" 4 "PMS_POWERBROWNOUT" 3 "PMS_AUDIOSTARTING" 2 "PMS_ACCDELAY" 1 "PMS_FULLPOWER" 0 "PMS_CHECKING" ;
VAL_ 1056 UIS_odinStatusCmdResult 2 "EXCEPTION" 1 "FAIL" 0 "PASS" ;
VAL_ 1056 UIS_odinProcessState 4 "UNKNOWN" 3 "RUNNING_NETWORK_AND_ORCHESTRATOR" 2 "RUNNING_ORCHESTRATOR" 1 "RUNNING_NETWORK" 0 "IDLE" ;
VAL_ 1056 UIS_odinPeriodicTaskState 6 "QUEUED_FAILED" 5 "CANCELLED" 4 "FAILED" 3 "TIMEOUT" 2 "SUCCESS" 1 "ENQUEUED" 0 "IDLE" ;
VAL_ 1056 UIS_odinListTasksCmdResult 2 "EXCEPTION" 1 "FAIL" 0 "PASS" ;
VAL_ 1056 UIS_odinHrlUploadLimits 1 "CELL_DAILY_UPLOAD_LIMIT_REACHED" 0 "DAILY_UPLOAD_LIMIT_REACHED" ;
VAL_ 1056 UIS_odinHrlLogUploadState 4 "HRL_FILE_UPLOADED" 3 "HRL_FILE_UPLOAD_FAILED" 2 "HRL_FILE_TRANSFER_FAILED" 1 "HRL_FILE_TRANSFERRED" 0 "SERVICE_STARTED" ;
VAL_ 1056 UIS_odinHermesConnectionState 3 "CONNECTION_ERROR" 2 "CONNECTING" 1 "CONNECTED" 0 "DISCONNECTED" ;
VAL_ 1056 UIS_odinGatewayConnectionState 2 "CONNECTION_ERROR" 1 "CONNECTED" 0 "DISCONNECTED" ;
VAL_ 1056 UIS_odinFileSystemState 4 "DIR_SIZE_LIMIT_SURPASSED" 3 "OVERSIZED_FILE" 2 "DIR_DELETED" 1 "FILE_DELETED" 0 "IDLE" ;
VAL_ 1056 UIS_odinEcuLogUploadState 5 "FAILURE" 4 "COMPLETE" 3 "UPLOADING" 2 "GET_DATA" 1 "POLLING" 0 "IDLE" ;
VAL_ 1056 UIS_odinEcuLogForceTriggerUpload 1 "REQUESTED" 0 "IDLE" ;
VAL_ 1056 UIS_mounterdState 9 "MOUNTING_STEAM" 8 "MOUNTING_LIGHTSHOW" 7 "MOUNTING_UPDATE" 6 "MOUNTING_MEDIA" 5 "MOUNTING_ENCRYPTION" 4 "MOUNTING_DASHCAM" 3 "UNMOUNTING" 2 "IDLE" 1 "TERMINATED" 0 "INVALID" ;
VAL_ 1056 UIS_modemECallppAvail 1 "ENABLED" 0 "DISABLED" ;
VAL_ 1056 UIS_modemBusyActive 1 "RUNNING" 0 "OFF" ;
VAL_ 1056 UIS_mirrorGeofenceActive 1 "TRUE" 0 "FALSE" ;
VAL_ 1056 UIS_mediaPlaybackStatus 2 "PAUSED" 1 "PLAYING" 0 "STOPPED" ;
VAL_ 1056 UIS_mediaNeedAuthToken 1 "TRUE" 0 "FALSE" ;
VAL_ 1056 UIS_inSuperchargerGeofence 1 "TRUE" 0 "FALSE" ;
VAL_ 1056 UIS_homelinkState 23 "HW_ERROR" 22 "UNIVERSAL_RECEIVER_ERROR" 21 "UNIVERSAL_RECEIVER_SUCCESS" 20 "UNIVERSAL_RECEIVER_WAIT" 19 "DEFAULT_FAIL" 18 "DEFAULT_SUCCESS" 17 "DEFAULT_WAIT" 16 "STANDARD_FAIL" 15 "STANDARD_SUCCESS" 14 "STANDARD_WAIT" 13 "CLEAR_FAIL" 12 "CLEAR_SUCCESS" 11 "CLEAR_WAIT" 10 "TIMEOUT" 9 "LEARN_FAIL" 8 "LEARN_CANCLE" 7 "LEARN_SUCCESS_NOT_ROLLING" 6 "LEARN_SUCCESS_ROLLING" 5 "LEARN_TEST" 4 "LEARN_SUCCESS" 3 "LEARN_WAIT" 2 "PROGRAM_WAIT" 1 "TRANSMITTING" 0 "IDLE" ;
VAL_ 1056 UIS_hicarEventCode 9 "APPLIST_UPDATED" 8 "PROJECTION_BACKGROUND" 7 "PROJECTION_FOREGROUND" 6 "CALL_METADATA_SUPPORTED" 5 "MEDIA_METADATA_SUPPORTED" 4 "NAVIGATION_METADATA_SUPPORTED" 3 "SPEECH_STOPPED" 2 "SPEECH_STARTED" 1 "NAVIGATION_STOPPED" 0 "NAVIGATION_STARTED" ;
VAL_ 1056 UIS_hicarErrorCode 0 "AUDIO_LATENCY" ;
VAL_ 1056 UIS_hicarConnectionState 4 "DISCONNECTING" 3 "CONNECTED" 2 "WIFI_CONNECTING" 1 "BR_CONNECTING" 0 "DISCONNECTED" ;
VAL_ 1056 UIS_hicarCallState 8 "DISCONNECTING" 7 "DISCONNECTED" 6 "WAITING" 5 "INCOMING" 4 "ALERTING" 3 "DIALING" 2 "HOLDING" 1 "ACTIVE" 0 "IDLE" ;
VAL_ 1056 UIS_hicarAudioTeardownState 3 "DEFAULT" 2 "PHONE_CALL" 1 "NAVIGATION" 0 "MEDIA" ;
VAL_ 1056 UIS_hicarAudioSetupState 3 "DEFAULT" 2 "PHONE_CALL" 1 "NAVIGATION" 0 "MEDIA" ;
VAL_ 1056 UIS_headsetPairResult 23 "HID_PAIRED" 22 "HID_MAX_NR_OF_CONNS" 21 "HID_PAGE_TIMEOUT" 20 "HID_OETC_USER" 19 "HID_REJ_BY_REMOTE_NO_RES" 18 "HID_LMP_RESPONSE_TIMEOUT" 17 "HID_AUTH_FAILURE" 16 "HID_KEY_MISSING" 15 "HID_NO_RESPONSE" 14 "HID_ALREADY_REQUESTED_BY_REMOTE" 13 "HID_UNKNOWN" 12 "HID_UNPAIRED" 11 "PAIRED" 10 "MAX_NR_OF_CONNS" 9 "PAGE_TIMEOUT" 8 "OETC_USER" 7 "REJ_BY_REMOTE_NO_RES" 6 "LMP_RESPONSE_TIMEOUT" 5 "AUTH_FAILURE" 4 "KEY_MISSING" 3 "NO_RESPONSE" 2 "ALREADY_REQUESTED_BY_REMOTE" 1 "UNKNOWN" 0 "UNPAIRED" ;
VAL_ 1056 UIS_headsetConnectionState 77 "HID_ERROR_UNKNOWN" 76 "HID_ERROR_ANTENNA_DISCONNECTED" 75 "HID_CONNECTED" 74 "HID_CONNECT_CANCELLED" 73 "HID_CONNECT_PROFILE_UNAVAILABLE" 72 "HID_CONNECT_INVALID_ARGUMENT" 71 "HID_CONNECT_ADAPTER_OFF" 70 "HID_CONNECT_NOT_SUPPORTED" 69 "HID_CONNECT_ALREADY_CONN" 68 "HID_CONNECT_DEVICE_NOT_FOUND_NO_RESOURCES" 67 "HID_CONNECT_DEVICE_NOT_FOUND_PAGE_TIMEOUT" 66 "HID_CONNECT_DEVICE_NOT_FOUND" 65 "HID_CONNECT_FAILED_REMOTE_TERMINATED" 64 "HID_CONNECT_FAILED_NO_RESOURCES" 63 "HID_CONNECT_FAILED_CONNECTION_TIMEOUT" 62 "HID_CONNECT_FAILED" 61 "HID_CONNECT_SDP_FAILURE" 60 "HID_CONNECT_PIN_MISSING" 59 "HID_CONNECT_PAGE_TIMEOUT" 58 "HID_CONNECT_REJ_BY_REMOTE_NO_RES" 57 "HID_CONNECT_MAX_NR_OF_CONNS" 56 "HID_CONNECT_CONTROLLER_BUSY" 55 "HID_CONNECT_CONN_TIMEOUT" 54 "HID_CONNECT_MAX_NR_OF_ACL" 53 "HID_CONNECT_LMP_RESPONSE_TIMEOUT" 52 "HID_CONNECT_HOST_TIMEOUT" 51 "HID_CONNECT_UNKNOWN_FAILURE" 50 "HID_DISCONNECT_UNKNOWN" 49 "HID_DISCONNECT_OETC_POWERING_OFF" 48 "HID_DISCONNECT_OETC_LOW_RESOURCE" 47 "HID_DISCONNECT_REJ_BY_REMOTE_SEC" 46 "HID_DISCONNECT_AUTH_FAIL" 45 "HID_DISCONNECT_LMP_RESPONSE_TIMEOUT" 44 "HID_DISCONNECT_OETC_USER" 43 "HID_DISCONNECT_CONN_TIMEOUT" 42 "HID_DISCONNECT_CONN_TERM_LOCAL_HOST" 41 "HID_DISCONNECT_LINKLOSS" 40 "HID_DISCONNECT_FROM_REMOTE" 39 "HID_DISCONNECTED" 38 "ERROR_UNKNOWN" 37 "ERROR_ANTENNA_DISCONNECTED" 36 "CONNECTED" 35 "CONNECT_CANCELLED" 34 "CONNECT_PROFILE_UNAVAILABLE" 33 "CONNECT_INVALID_ARGUMENT" 32 "CONNECT_ADAPTER_OFF" 31 "CONNECT_NOT_SUPPORTED" 30 "CONNECT_ALREADY_CONN" 29 "CONNECT_DEVICE_NOT_FOUND_NO_RESOURCES" 28 "CONNECT_DEVICE_NOT_FOUND_PAGE_TIMEOUT" 27 "CONNECT_DEVICE_NOT_FOUND" 26 "CONNECT_FAILED_REMOTE_TERMINATED" 25 "CONNECT_FAILED_NO_RESOURCES" 24 "CONNECT_FAILED_CONNECTION_TIMEOUT" 23 "CONNECT_FAILED" 22 "CONNECT_SDP_FAILURE" 21 "CONNECT_PIN_MISSING" 20 "CONNECT_PAGE_TIMEOUT" 19 "CONNECT_REJ_BY_REMOTE_NO_RES" 18 "CONNECT_MAX_NR_OF_CONNS" 17 "CONNECT_CONTROLLER_BUSY" 16 "CONNECT_CONN_TIMEOUT" 15 "CONNECT_MAX_NR_OF_ACL" 14 "CONNECT_LMP_RESPONSE_TIMEOUT" 13 "CONNECT_HOST_TIMEOUT" 12 "CONNECT_UNKNOWN_FAILURE" 11 "DISCONNECT_UNKNOWN" 10 "DISCONNECT_OETC_POWERING_OFF" 9 "DISCONNECT_OETC_LOW_RESOURCE" 8 "DISCONNECT_REJ_BY_REMOTE_SEC" 7 "DISCONNECT_AUTH_FAIL" 6 "DISCONNECT_LMP_RESPONSE_TIMEOUT" 5 "DISCONNECT_OETC_USER" 4 "DISCONNECT_CONN_TIMEOUT" 3 "DISCONNECT_CONN_TERM_LOCAL_HOST" 2 "DISCONNECT_LINKLOSS" 1 "DISCONNECT_FROM_REMOTE" 0 "DISCONNECTED" ;
VAL_ 1056 UIS_firmwareReleaseScope 2 "PROD" 1 "DEV" 0 "UNKNOWN" ;
VAL_ 1056 UIS_embeddedGameState 2 "FROZEN" 1 "PLAYING" 0 "STOPPED" ;
VAL_ 1056 UIS_embeddedGameName 2 "POLYTOPIA" 1 "SOLITAIRE" 0 "NONE" ;
VAL_ 1056 UIS_dynamicTriggersTelemetryServ 4 "REGISTERED" 3 "UPLOADED" 2 "UPLOAD_FAILED" 1 "REGISTRATION_FAILED" 0 "IDLE" ;
VAL_ 1056 UIS_dynamicTriggersOutputManager 4 "REGISTERED" 3 "UPLOADED" 2 "UPLOAD_FAILED" 1 "REGISTRATION_FAILED" 0 "IDLE" ;
VAL_ 1056 UIS_dynamicTriggersHRLServiceSta 3 "COLLECTING" 2 "COLLECTED" 1 "FAILED" 0 "IDLE" ;
VAL_ 1056 UIS_dynamicTriggersCampaignState 9 "COLLECTING_OUTPUTS" 8 "COOLDOWN" 7 "EVALUATING" 6 "HAMMERED" 5 "EXPIRED" 4 "COMPLETED" 3 "STARTED" 2 "TRIGGERED" 1 "DESCHEDULED" 0 "SNA" ;
VAL_ 1056 UIS_dumTclipUploadState 7 "TclipStateDone" 6 "TclipStateUploading" 5 "TclipStateWaiting" 4 "TclipStateTransferring" 3 "TclipStatePolling" 2 "TclipStateChecking" 1 "TclipStateIdle" 0 "TclipStateSNA" ;
VAL_ 1056 UIS_dmRearPowerState 1 "ON" 0 "OFF" ;
VAL_ 1056 UIS_dmRearLinkCheckOk 1 "PASSED" 0 "FAILED" ;
VAL_ 1056 UIS_dmRearBacklightPowerLevel 2 "HIGH_POWER" 1 "LOW_POWER" 0 "OFF" ;
VAL_ 1056 UIS_dmRearBacklightDevExists 1 "PASSED" 0 "FAILED" ;
VAL_ 1056 UIS_dmIcuPowerState 1 "ON" 0 "OFF" ;
VAL_ 1056 UIS_dmIcuLinkCheckOk 1 "PASSED" 0 "FAILED" ;
VAL_ 1056 UIS_dmIcuBacklightPowerLevel 2 "HIGH_POWER" 1 "LOW_POWER" 0 "OFF" ;
VAL_ 1056 UIS_dmIcuBacklightDevExists 1 "PASSED" 0 "FAILED" ;
VAL_ 1056 UIS_dmIcuAsilResumeFlag 4 "ACI_ERROR_RESET" 3 "SOFTWARE_RESET" 2 "REBOOT_RESET" 1 "WATCHDOG_RESET" 0 "GLOBAL_RESET" ;
VAL_ 1056 UIS_dmIcuAsilFirmwareStatus 3 "NORMAL_RUN" 2 "CALIBRATION_DONE" 1 "CALIBRATION" 0 "INITIAL_STAGE" ;
VAL_ 1056 UIS_dmCenterSOsdExactCrcCheck 2 "PASS" 1 "EXPECT_MATCH_FAIL" 0 "EXPECT_MISMATCH_FAIL" ;
VAL_ 1056 UIS_dmCenterPowerState 1 "ON" 0 "OFF" ;
VAL_ 1056 UIS_dmCenterOsdDisplayedState 1 "SHOWING" 0 "HIDDEN" ;
VAL_ 1056 UIS_dmCenterOsdDayNightState 1 "DAY" 0 "NIGHT" ;
VAL_ 1056 UIS_dmCenterModeSettingStatus 1 "PASSED" 0 "FAILED" ;
VAL_ 1056 UIS_dmCenterMOsdExactCrcCheck 2 "PASS" 1 "EXPECT_MATCH_FAIL" 0 "EXPECT_MISMATCH_FAIL" ;
VAL_ 1056 UIS_dmCenterLinkCheckOk 1 "PASSED" 0 "FAILED" ;
VAL_ 1056 UIS_dmCenterBacklightPowerLevel 2 "HIGH_POWER" 1 "LOW_POWER" 0 "OFF" ;
VAL_ 1056 UIS_dmCenterBacklightDevExists 1 "PASSED" 0 "FAILED" ;
VAL_ 1056 UIS_dmCenterAsilResumeFlag 4 "ACI_ERROR_RESET" 3 "SOFTWARE_RESET" 2 "REBOOT_RESET" 1 "WATCHDOG_RESET" 0 "GLOBAL_RESET" ;
VAL_ 1056 UIS_dmCenterAsilFirmwareStatus 3 "NORMAL_RUN" 2 "CALIBRATION_DONE" 1 "CALIBRATION" 0 "INITIAL_STAGE" ;
VAL_ 1056 UIS_dmCenterAsilCalibrationSync 1 "IN_SYNC" 0 "OUT_OF_SYNC" ;
VAL_ 1056 UIS_dashcamStorageState 8 "RECENT_BUFFER_DURATION_REDUCED" 7 "SLOW" 6 "READ_ONLY" 5 "FULL" 4 "GETTING_FULL" 3 "ERROR" 2 "READY" 1 "REMOVED" 0 "INVALID" ;
VAL_ 1056 UIS_dashcamState 7 "STREAMING" 6 "SAVING" 5 "PAUSED" 4 "RECORDING" 3 "STOPPED" 2 "ERROR" 1 "TERMINATED" 0 "INVALID" ;
VAL_ 1056 UIS_dasAutonomyControlMessageMia 1 "TRUE" 0 "FALSE" ;
VAL_ 1056 UIS_compositorFrameMonitorState 6 "DISCONNECTED" 5 "OK" 4 "STALLED" 3 "STALLING" 2 "CORRUPT_TIMECODE" 1 "UNKNOWN_FAILURE" 0 "UNKNOWN" ;
VAL_ 1056 UIS_clusterDisplayState 9 "ENTERTAINMENT" 8 "DOG" 7 "SENTRY" 6 "LOCK" 5 "CHARGING" 4 "DRIVING" 3 "ON" 2 "ACCESSORY" 1 "DIM" 0 "OFF" ;
VAL_ 1056 UIS_chargeOnSolarNoChargeReason 3 "ALTERNATIVE_VEHICLE_CHARGE_PRIORITY" 2 "GRID_EXPORT_PRIORITY" 1 "POWERWALL_CHRAGE_PRIORITY" 0 "INSUFFICIENT_SOLAR" ;
VAL_ 1056 UIS_centerDisplayState 9 "ENTERTAINMENT" 8 "DOG" 7 "SENTRY" 6 "LOCK" 5 "CHARGING" 4 "DRIVING" 3 "ON" 2 "ACCESSORY" 1 "DIM" 0 "OFF" ;
VAL_ 1056 UIS_centerDisplayEvent 21 "CPD_TRIGGERED" 20 "CAR_LOCKED" 19 "ENTERTAINMENT_OFF" 18 "ALL_STATES_EXCEPT_ENTERTAINMENT_TURNED_ON" 17 "IC_HAZARDS_OFF_DOOR_CLOSED_NO_OCCUPANTS" 16 "IC_HAZARDS_ON" 15 "ALL_DOORS_CLOSED_NO_OCCUPANTS_CHARGE_ACTIVE" 14 "TIMEOUT" 13 "DOOR_HANDLE_PULLED" 12 "ALL_STATES_EXCEPT_SENTRY" 11 "SENTRY_PANIC_ENDED" 10 "POWER_OFF_REQUEST" 9 "DRIVE_RAIL_OFF_NO_DRIVER_PRESENT" 8 "DRIVE_RAIL_OFF_DOOR_OPEN" 7 "DRIVE_RAIL_OFF_DRIVE_PRESENT" 6 "POWER_ON_REQUEST" 5 "DOOR_OPENED" 4 "ALL_STATES_EXCEPT_ENTERTAINMENT_DRIVE_RAIL_TURNED_ON" 3 "ALL_DOORS_CLOSED_NO_OCCUPANTS" 2 "PASSED_SPEED_THRESHOLD" 1 "SHIFTED_P_TO_N" 0 "OTHER" ;
VAL_ 1056 UIS_cellularLinkManagerState 16 "INVALID" 15 "RUNNING" 14 "DISCONNECTING" 13 "ROAMINGDISALLOWED" 12 "ENTERINGAIRPLANEMODE" 11 "CHECKING" 10 "RETRYING" 9 "CONFIGURING" 8 "CONNECTING" 7 "OFONOMODEMRELOADING" 6 "SEARCHING" 5 "CONFIGURINGAPN" 4 "QUERYDIAGNOSTIC" 3 "STARTING" 2 "UPDATING" 1 "RESETTING" 0 "RECOVERING" ;
VAL_ 1056 UIS_cellularConnectivityStatus 1 "CONNECTED" 0 "DISCONNECTED" ;
VAL_ 1056 UIS_carAssistState 5 "GROK" 4 "DICTATION" 3 "COMMAND" 2 "ERROR" 1 "IDLE" 0 "DISABLED" ;
VAL_ 1056 UIS_carAssistMicMuted 1 "TRUE" 0 "FALSE" ;
VAL_ 1056 UIS_carAssistErrorCode 17 "CLIENT_LOGGED_OUT_TOKEN_EXPIRED" 16 "CLIENT_PROVIDER_RATE_LIMTED" 15 "CLIENT_PROVIDER_AT_CAPACITY" 14 "CLIENT_ANON_USAGE_LIMITED" 13 "CLIENT_PREM_CONN" 12 "CLIENT_SPEECH" 11 "CLIENT_REMOTE" 10 "CLIENT_DBUS" 9 "CLIENT_DISCONNECTED" 8 "CLIENT_CONNECTIVITY" 7 "CLIENT_AUDIO" 6 "CLIENT_ERROR" 5 "COMMAND_NOT_IMPLEMENTED" 4 "COMMAND_NOT_AVAILABLE" 3 "COMMAND_NOT_UNDERSTOOD" 2 "REMOTE_ERROR" 1 "REMOTE_UNKNOWN" 0 "NONE" ;
VAL_ 1056 UIS_cameraSelectableRenderState 2 "ACTIVE" 1 "REQUESTED" 0 "INACTIVE" ;
VAL_ 1056 UIS_cameraSelectablePipeline 4 "PLAYING" 3 "PAUSED" 2 "READY" 1 "NULL" 0 "SLEEP" ;
VAL_ 1056 UIS_cameraSelectablePacketState 2 "RECEIVING" 1 "MISSING" 0 "CHECKING" ;
VAL_ 1056 UIS_cameraRearViewStreamMissing 1 "MISSING" 0 "ACTIVE" ;
VAL_ 1056 UIS_cameraRearViewRenderState 2 "ACTIVE" 1 "REQUESTED" 0 "INACTIVE" ;
VAL_ 1056 UIS_cameraRearViewPopup 1 "OPEN" 0 "CLOSED" ;
VAL_ 1056 UIS_cameraRearViewPipeline 4 "PLAYING" 3 "PAUSED" 2 "READY" 1 "NULL" 0 "SLEEP" ;
VAL_ 1056 UIS_cameraRearViewPacketState 2 "RECEIVING" 1 "MISSING" 0 "CHECKING" ;
VAL_ 1056 UIS_cameraRRepeaterStreamMissing 1 "MISSING" 0 "ACTIVE" ;
VAL_ 1056 UIS_cameraRRepeaterRenderState 2 "ACTIVE" 1 "REQUESTED" 0 "INACTIVE" ;
VAL_ 1056 UIS_cameraRRepeaterPopup 1 "OPEN" 0 "CLOSED" ;
VAL_ 1056 UIS_cameraRRepeaterPipeline 4 "PLAYING" 3 "PAUSED" 2 "READY" 1 "NULL" 0 "SLEEP" ;
VAL_ 1056 UIS_cameraRRepeaterPacketState 2 "RECEIVING" 1 "MISSING" 0 "CHECKING" ;
VAL_ 1056 UIS_cameraRDownwardRenderState 2 "ACTIVE" 1 "REQUESTED" 0 "INACTIVE" ;
VAL_ 1056 UIS_cameraRDownwardPipeline 4 "PLAYING" 3 "PAUSED" 2 "READY" 1 "NULL" 0 "SLEEP" ;
VAL_ 1056 UIS_cameraRDownwardPacketState 2 "RECEIVING" 1 "MISSING" 0 "CHECKING" ;
VAL_ 1056 UIS_cameraLRepeaterStreamMissing 1 "MISSING" 0 "ACTIVE" ;
VAL_ 1056 UIS_cameraLRepeaterRenderState 2 "ACTIVE" 1 "REQUESTED" 0 "INACTIVE" ;
VAL_ 1056 UIS_cameraLRepeaterPopup 1 "OPEN" 0 "CLOSED" ;
VAL_ 1056 UIS_cameraLRepeaterPipeline 4 "PLAYING" 3 "PAUSED" 2 "READY" 1 "NULL" 0 "SLEEP" ;
VAL_ 1056 UIS_cameraLRepeaterPacketState 2 "RECEIVING" 1 "MISSING" 0 "CHECKING" ;
VAL_ 1056 UIS_cameraLDownwardRenderState 2 "ACTIVE" 1 "REQUESTED" 0 "INACTIVE" ;
VAL_ 1056 UIS_cameraLDownwardPipeline 4 "PLAYING" 3 "PAUSED" 2 "READY" 1 "NULL" 0 "SLEEP" ;
VAL_ 1056 UIS_cameraLDownwardPacketState 2 "RECEIVING" 1 "MISSING" 0 "CHECKING" ;
VAL_ 1056 UIS_cameraFrontStreamMissing 1 "MISSING" 0 "ACTIVE" ;
VAL_ 1056 UIS_cameraFrontRenderState 2 "ACTIVE" 1 "REQUESTED" 0 "INACTIVE" ;
VAL_ 1056 UIS_cameraFrontPopup 1 "OPEN" 0 "CLOSED" ;
VAL_ 1056 UIS_cameraFrontPipeline 4 "PLAYING" 3 "PAUSED" 2 "READY" 1 "NULL" 0 "SLEEP" ;
VAL_ 1056 UIS_cameraFrontPacketState 2 "RECEIVING" 1 "MISSING" 0 "CHECKING" ;
VAL_ 1056 UIS_cameraBackupStreamQuality 4 "EXCELLENT" 3 "GOOD" 2 "FAIR" 1 "POOR" 0 "UNKNOWN" ;
VAL_ 1056 UIS_cameraBackupStreamMissing 1 "MISSING" 0 "ACTIVE" ;
VAL_ 1056 UIS_cameraBackupRenderState 2 "ACTIVE" 1 "REQUESTED" 0 "INACTIVE" ;
VAL_ 1056 UIS_cameraBackupPopup 1 "OPEN" 0 "CLOSED" ;
VAL_ 1056 UIS_cameraBackupPipeline 4 "PLAYING" 3 "PAUSED" 2 "READY" 1 "NULL" 0 "SLEEP" ;
VAL_ 1056 UIS_cameraBackupPacketState 2 "RECEIVING" 1 "MISSING" 0 "CHECKING" ;
VAL_ 1056 UIS_pmSuspendHookIndex 99 "PM_SUSPEND_END" 98 "Kernel" 95 "Timesync" 90 "LED" 80 "Button" 70 "NVME" 69 "Memory" 61 "Cameras" 50 "Modem" 40 "Bluetooth" 30 "Wifi" 25 "Hermes" 20 "USB" 10 "Audio" 9 "BluetoothRear" 5 "DGPU" 2 "Post" 1 "Steam" 0 "PM_SUSPEND_START" ;
VAL_ 1056 UIS_bluetoothState 11 "CONNECTED" 10 "CONN_MAP" 9 "CONN_PBAP" 8 "CONN_A2DP" 7 "CONN_HFP" 6 "CONN_SPP" 5 "CONN_ACL" 4 "CONNECTING" 3 "PAIRING" 2 "DISCOVERY_STOP" 1 "DISCOVERY_START" 0 "DISCONNECTED" ;
VAL_ 1056 UIS_bluetoothStackState 4 "ON_BLUEZ" 3 "ON_SYNERGY" 2 "ON_LGIT" 1 "ON" 0 "OFF" ;
VAL_ 1056 UIS_bluetoothStackRearState 4 "ON_BLUEZ" 3 "ON_SYNERGY" 2 "ON_LGIT" 1 "ON" 0 "OFF" ;
VAL_ 1056 UIS_bluetoothPairResult 23 "HID_PAIRED" 22 "HID_MAX_NR_OF_CONNS" 21 "HID_PAGE_TIMEOUT" 20 "HID_OETC_USER" 19 "HID_REJ_BY_REMOTE_NO_RES" 18 "HID_LMP_RESPONSE_TIMEOUT" 17 "HID_AUTH_FAILURE" 16 "HID_KEY_MISSING" 15 "HID_NO_RESPONSE" 14 "HID_ALREADY_REQUESTED_BY_REMOTE" 13 "HID_UNKNOWN" 12 "HID_UNPAIRED" 11 "PAIRED" 10 "MAX_NR_OF_CONNS" 9 "PAGE_TIMEOUT" 8 "OETC_USER" 7 "REJ_BY_REMOTE_NO_RES" 6 "LMP_RESPONSE_TIMEOUT" 5 "AUTH_FAILURE" 4 "KEY_MISSING" 3 "NO_RESPONSE" 2 "ALREADY_REQUESTED_BY_REMOTE" 1 "UNKNOWN" 0 "UNPAIRED" ;
VAL_ 1056 UIS_bluetoothConnectionState 77 "HID_ERROR_UNKNOWN" 76 "HID_ERROR_ANTENNA_DISCONNECTED" 75 "HID_CONNECTED" 74 "HID_CONNECT_CANCELLED" 73 "HID_CONNECT_PROFILE_UNAVAILABLE" 72 "HID_CONNECT_INVALID_ARGUMENT" 71 "HID_CONNECT_ADAPTER_OFF" 70 "HID_CONNECT_NOT_SUPPORTED" 69 "HID_CONNECT_ALREADY_CONN" 68 "HID_CONNECT_DEVICE_NOT_FOUND_NO_RESOURCES" 67 "HID_CONNECT_DEVICE_NOT_FOUND_PAGE_TIMEOUT" 66 "HID_CONNECT_DEVICE_NOT_FOUND" 65 "HID_CONNECT_FAILED_REMOTE_TERMINATED" 64 "HID_CONNECT_FAILED_NO_RESOURCES" 63 "HID_CONNECT_FAILED_CONNECTION_TIMEOUT" 62 "HID_CONNECT_FAILED" 61 "HID_CONNECT_SDP_FAILURE" 60 "HID_CONNECT_PIN_MISSING" 59 "HID_CONNECT_PAGE_TIMEOUT" 58 "HID_CONNECT_REJ_BY_REMOTE_NO_RES" 57 "HID_CONNECT_MAX_NR_OF_CONNS" 56 "HID_CONNECT_CONTROLLER_BUSY" 55 "HID_CONNECT_CONN_TIMEOUT" 54 "HID_CONNECT_MAX_NR_OF_ACL" 53 "HID_CONNECT_LMP_RESPONSE_TIMEOUT" 52 "HID_CONNECT_HOST_TIMEOUT" 51 "HID_CONNECT_UNKNOWN_FAILURE" 50 "HID_DISCONNECT_UNKNOWN" 49 "HID_DISCONNECT_OETC_POWERING_OFF" 48 "HID_DISCONNECT_OETC_LOW_RESOURCE" 47 "HID_DISCONNECT_REJ_BY_REMOTE_SEC" 46 "HID_DISCONNECT_AUTH_FAIL" 45 "HID_DISCONNECT_LMP_RESPONSE_TIMEOUT" 44 "HID_DISCONNECT_OETC_USER" 43 "HID_DISCONNECT_CONN_TIMEOUT" 42 "HID_DISCONNECT_CONN_TERM_LOCAL_HOST" 41 "HID_DISCONNECT_LINKLOSS" 40 "HID_DISCONNECT_FROM_REMOTE" 39 "HID_DISCONNECTED" 38 "ERROR_UNKNOWN" 37 "ERROR_ANTENNA_DISCONNECTED" 36 "CONNECTED" 35 "CONNECT_CANCELLED" 34 "CONNECT_PROFILE_UNAVAILABLE" 33 "CONNECT_INVALID_ARGUMENT" 32 "CONNECT_ADAPTER_OFF" 31 "CONNECT_NOT_SUPPORTED" 30 "CONNECT_ALREADY_CONN" 29 "CONNECT_DEVICE_NOT_FOUND_NO_RESOURCES" 28 "CONNECT_DEVICE_NOT_FOUND_PAGE_TIMEOUT" 27 "CONNECT_DEVICE_NOT_FOUND" 26 "CONNECT_FAILED_REMOTE_TERMINATED" 25 "CONNECT_FAILED_NO_RESOURCES" 24 "CONNECT_FAILED_CONNECTION_TIMEOUT" 23 "CONNECT_FAILED" 22 "CONNECT_SDP_FAILURE" 21 "CONNECT_PIN_MISSING" 20 "CONNECT_PAGE_TIMEOUT" 19 "CONNECT_REJ_BY_REMOTE_NO_RES" 18 "CONNECT_MAX_NR_OF_CONNS" 17 "CONNECT_CONTROLLER_BUSY" 16 "CONNECT_CONN_TIMEOUT" 15 "CONNECT_MAX_NR_OF_ACL" 14 "CONNECT_LMP_RESPONSE_TIMEOUT" 13 "CONNECT_HOST_TIMEOUT" 12 "CONNECT_UNKNOWN_FAILURE" 11 "DISCONNECT_UNKNOWN" 10 "DISCONNECT_OETC_POWERING_OFF" 9 "DISCONNECT_OETC_LOW_RESOURCE" 8 "DISCONNECT_REJ_BY_REMOTE_SEC" 7 "DISCONNECT_AUTH_FAIL" 6 "DISCONNECT_LMP_RESPONSE_TIMEOUT" 5 "DISCONNECT_OETC_USER" 4 "DISCONNECT_CONN_TIMEOUT" 3 "DISCONNECT_CONN_TERM_LOCAL_HOST" 2 "DISCONNECT_LINKLOSS" 1 "DISCONNECT_FROM_REMOTE" 0 "DISCONNECTED" ;
VAL_ 1056 UIS_bluetoothAutoConnectionState 3 "MANUAL_CONNECT_REQUESTED" 2 "GAVE_UP" 1 "CONNECTED" 0 "IDLE" ;
VAL_ 1056 UIS_audioType 4 "BASE_WITH_PREMIUM200" 3 "PREMIUM" 2 "BASE" 1 "NO_A2B" 0 "INVALID" ;
VAL_ 1056 UIS_audioState 7 "SLEEPING" 6 "AUDIO_NOT_PUMPING" 5 "A2B_REDISCOVERY" 4 "HFP_PUMPING" 3 "AUDIO_PUMPING" 2 "UNINITIALIZING" 1 "INITIALIZING" 0 "TERMINATED" ;
VAL_ 1056 UIS_audioSource 5 "NONE" 4 "PHONE_RX" 3 "BLUETOOTH" 2 "MICROPHONE" 1 "TUNER" 0 "MEDIA" ;
VAL_ 1056 UIS_audioMediaPlaying 39 "SODA_MUSIC" 38 "CARAOKE" 37 "KUGOU" 36 "YOUTUBE_MUSIC" 35 "YUNTING" 34 "AMAZON_MUSIC" 33 "AUDIBLE" 32 "APPLE_PODCASTS" 31 "APPLE_MUSIC" 30 "MINI_PROGRAMS" 29 "SEARCH" 28 "HOME_APPS" 27 "RECENTS_FAVORITES" 26 "TOYBOX" 25 "TUTORIAL" 24 "THEATER" 23 "BROWSER" 22 "GAME" 21 "NET_EASE_MUSIC" 20 "ONLINE_RADIO" 19 "XIMALAYA" 18 "QQ_MUSIC2" 17 "QQ_MUSIC1" 16 "TIDAL" 15 "SIRIUS_XM" 14 "STINGRAY" 13 "TUNE_IN" 12 "EU_RADIO" 11 "US_RADIO" 10 "SPOTIFY" 9 "SLACKER" 8 "BLUETOOTH" 7 "USB" 6 "DAB" 5 "XM" 4 "FM" 3 "AM" 2 "UNKNOWN" 1 "DEPRECATED" 0 "NONE" ;
VAL_ 1056 UIS_audioMediaBrowsing 39 "SODA_MUSIC" 38 "CARAOKE" 37 "KUGOU" 36 "YOUTUBE_MUSIC" 35 "YUNTING" 34 "AMAZON_MUSIC" 33 "AUDIBLE" 32 "APPLE_PODCASTS" 31 "APPLE_MUSIC" 30 "MINI_PROGRAMS" 29 "SEARCH" 28 "HOME_APPS" 27 "RECENTS_FAVORITES" 26 "TOYBOX" 25 "TUTORIAL" 24 "THEATER" 23 "BROWSER" 22 "GAME" 21 "NET_EASE_MUSIC" 20 "ONLINE_RADIO" 19 "XIMALAYA" 18 "QQ_MUSIC2" 17 "QQ_MUSIC1" 16 "TIDAL" 15 "SIRIUS_XM" 14 "STINGRAY" 13 "TUNE_IN" 12 "EU_RADIO" 11 "US_RADIO" 10 "SPOTIFY" 9 "SLACKER" 8 "BLUETOOTH" 7 "USB" 6 "DAB" 5 "XM" 4 "FM" 3 "AM" 2 "UNKNOWN" 1 "DEPRECATED" 0 "NONE" ;
VAL_ 1056 UIS_activeAppView 67 "SODA_MUSIC" 66 "HICAR" 65 "CARAOKE_WEB" 64 "KUGOU" 63 "YOUTUBE_MUSIC" 62 "YUNTING" 61 "ONLINE_RADIO" 60 "AMAZON_MUSIC" 59 "AUDIBLE" 58 "APPLE_PODCASTS" 57 "ONBOARDING_MANUAL" 56 "APPLE_MUSIC" 55 "ZOOM" 54 "MINI_PROGRAMS" 53 "CADMIUM" 52 "MESSAGES" 51 "NAV_MEDIA" 50 "BACKGAMMON" 49 "SKETCH_PAD" 48 "ARCADE" 47 "XIMALAYA" 46 "BLUETOOTH" 45 "CHESS" 44 "NETEASE" 43 "OWNERS_MANUAL" 42 "QQMUSIC" 41 "RELEASE_NOTES" 40 "SONIC" 39 "USB" 38 "THEATER" 37 "TIDAL" 36 "TUNEIN" 35 "CARAOKE" 34 "STREAMING" 33 "RADIO" 32 "SPOTIFY" 31 "CAMERA" 30 "CHARGE" 29 "MEDIA" 28 "ENTERTAINMENT" 27 "WEB" 26 "CALENDAR" 25 "TOYBOX" 24 "PHONE" 23 "ENERGY" 22 "TUTORIAL" 21 "CERULEAN" 20 "TOPAZ" 19 "DASHCAM" 18 "CARBONADO" 17 "THEATERVIEW" 16 "MAMBU" 15 "COBALT" 14 "TESLATARI" 13 "SERVICE_APPS" 12 "LIME" 11 "TEARDROP" 10 "NAV" 9 "PURPLE" 8 "CALICO" 7 "CARWASH" 6 "2048" 5 "CONTROLS" 4 "COLORIZER" 3 "XM" 2 "DEVELOPMENT" 1 "NONE" 0 "UNKNOWN" ;
VAL_ 979 UI_airbagCutoffSwState 2 "SNA" 1 "PASSENGER_AIRBAG_OFF" 0 "PASSENGER_AIRBAG_ON" ;
VAL_ 979 UI_warningIndicatorStatus 3 "SNA" 1 "WARNING_LAMP_ON" 0 "WARNING_LAMP_OFF" ;
VAL_ 1523 UI_alertID 278 "a278_gpsHwDegraded" 277 "a277_PONRPopupShown" 276 "a276_PrivateNetworkProfileActive" 275 "a275_ADDWFaulted" 274 "a274_ContextualHintCardEvent" 273 "a273_AudioDbusFailure" 272 "a272_eapTlsCSRFailure" 266 "a266_DashcamRecentBufferDurationReduced" 265 "a265_USBHostControllerUnrecoverable" 264 "a264_invalidEpaRange" 263 "a263_ecuLogUploadFailure" 261 "a261_bluetoothStackPanic" 260 "a260_sapWrongChannel" 259 "a259_sapChannelMismatch" 258 "a258_sapFailedToPowerOn" 257 "a257_modemRebooting" 256 "a256_sapFailedToEnable" 255 "a255_apbCertificateExpired" 254 "a254_appCertificateExpired" 253 "a253_maintenanceHistoryRecorded" 252 "a252_TPMErrorReceive" 247 "a247_StalklessDisplayBacklightFailure" 246 "a246_gpuFenceTimeout" 245 "a245_taskHung" 244 "a244_segfault" 243 "a243_pmDisplayCheckFailure" 242 "a242_uiHealthFaultInjectionActive" 241 "a241_AxCPError" 240 "a240_ethError" 238 "a238_ModemConfigMismatch" 237 "a237_ClipUploadActive" 236 "a236_ModemOnResetState" 235 "a235_AMDI2C1Timeout" 234 "a234_AMDI2C0Timeout" 233 "a233_ModemRFFailure" 232 "a232_processExitError" 231 "a231_SleepCancelled" 230 "a230_ModemSimCardMismatch" 229 "a229_SerDesError" 228 "a228_pipewireXrunBurst" 226 "a226_largePhoneContactSync" 225 "a225_clusterDisplayDisconnected" 224 "a224_centerDisplayDisconnected" 223 "a223_databaseError" 222 "a222_QtCarRestart" 221 "a221_NavigationServiceError" 220 "a220_MediaBrowseError" 219 "a219_CompositorWatchdog" 218 "a218_AudiodNoAudioDevices" 217 "a217_CgroupMemoryPressure" 216 "a216_AudioA2bCircuitProblem" 215 "a215_compositorStallDetected" 214 "a214_pmHelperFailure" 213 "a213_ISADisabled" 212 "a212_AEBSFaulted" 211 "a211_AEBSDisabled" 210 "a210_CellularCSRegFail" 209 "a209_dataCallDisconnected" 208 "a208_mqttClientDisconnected" 206 "a206_ModemMIAAfterWake" 205 "a205_ModemSleepSignalMismatch" 204 "a204_ModemSleepFailure" 202 "a202_sysMemoryIncorrect" 201 "a201_rearDisplayDisconnected" 200 "a200_UIFirmwareVersionMismatch" 199 "a199_HighAPedalDetectedAtCollision" 198 "a198_IncompatibleBTUSBHubHardware" 197 "a197_AMDI2C1BusInoperable" 196 "a196_AMDI2C3BusInoperable" 195 "a195_gtwMfdUdpApiFired" 194 "a194_AudioweaverRestarted" 193 "a193_TcuRNandFwVersionMismatch" 192 "a192_AudioWatchdogReboot" 191 "a191_TunerUpdateFailed" 190 "a190_TunerMIA" 189 "a189_TunerWatchdogReset" 188 "a188_TunerFirmwareMismatchedAPI" 187 "a187_TunerFirmwareMismatchedVersion" 186 "a186_ELKSUnavailable" 185 "a185_ELKSDisabled" 184 "a184_ISAFaulted" 183 "a183_DDAWFaulted" 182 "a182_VideoPipelineOverrun" 181 "a181_ModemFirmwareVersionMismatch" 180 "a180_AudiodInputRestarted" 178 "a178_irqDisabled" 177 "a177_MediaPlayerFailure" 176 "a176_CellularAntennaAlert" 174 "a174_HistorySaveLoop" 173 "a173_pmSuspendFailure" 172 "a172_GraphicsLoadShedUIFailure" 171 "a171_GraphicsLoadShedRequested" 170 "a170_AMDdGPULoadShedFailure" 169 "a169_SteamLoadShedFailure" 168 "a168_dgpuPowerOnSelfTestFailure" 167 "a167_CgroupOverMemKill" 166 "a166_fsError" 165 "a165_fsCorrupted" 164 "a164_AudiodConnTimeout" 163 "a163_QtCarVehicleExitError" 162 "a162_voiceRecClipsUploaded" 161 "a161_ECallTemporarilyUnavailable" 160 "a160_SystemWatchdogFailure" 159 "a159_AudioHeartbeatFailure" 158 "a158_UsbDeviceMountError" 157 "a157_MCUActiveCoolingRequested" 156 "a156_UsbFrontHubInstallMismatch" 155 "a155_UsbFrontHubUnavailable" 154 "a154_AudiodBufferError" 153 "a153_serviceRestarted" 152 "a152_infoThrottling" 151 "a151_carComputerThermalProblem" 150 "a150_infoCPURunningHot" 149 "a149_DisplayCheckFailure" 148 "a148_SleepFailure" 147 "a147_ASILGlobalError" 146 "a146_nvmeNeedsReplacement" 145 "a145_nvmeUnsafeShutdown" 144 "a144_nvmeWarning" 143 "a143_FPSCrawling" 142 "a142_CorrectableMemoryError" 141 "a141_falconDoorOpen" 140 "a140_NeverSleepActive" 139 "a139_postponedConfigChange" 138 "a138_applyingConfigChange" 137 "a137_ServiceShellActiveConnection" 136 "a136_warnSettingsConfExists" 135 "a135_warnRunOverlayExists" 134 "a134_DashcamUsbDriveNoMedium" 133 "a133_AdspWatchdogRecoveryFailed" 132 "a132_AdspWatchdogRecoveryTriggered" 131 "a131_DisplayPortFailure" 130 "a130_QtCarClusterExitError" 129 "a129_dgpuOperationFailure" 128 "a128_dgpuNotDetected" 126 "a126_UsbErrorDriveCorrupt" 125 "a125_AMDI2C1TxRxAborted" 124 "a124_AMDI2C0TxRxAborted" 123 "a123_AMDI2C1LostArbitration" 122 "a122_AMDI2C0LostArbitration" 121 "a121_nvmeSmartLogCritical" 120 "a120_nvmePCIeLinkErrorDetected" 119 "a119_nvmeBlockDeviceMissing" 118 "a118_NVMeReset" 117 "a117_VehicleSelfTestRunning" 116 "a116_UncorrectableMemoryError" 115 "a115_IrisEDLMode" 114 "a114_drivingVisualizationDegraded" 113 "a113_DashcamHasOnboardSentryClips" 112 "a112_badUSBDevice" 111 "a111_DashcamUsbDriveNotSuperSpeed" 110 "a110_DashcamUsbDriveCorrupt" 109 "a109_DashcamUsbDriveTooSmall" 108 "a108_DashcamUsbDriveGettingFull" 107 "a107_DashcamUsbDriveTooBigForVfatFsck" 106 "a106_rebootBackstopTriggered" 105 "a105_firmwareReinstallRequested" 104 "a104_DashcamUsbDriveMissing" 103 "a103_UsbHubNotEnumerating" 102 "a102_A2bDiscoveryFailed" 101 "a101_wifiStackProblem" 100 "a100_eMMCFTLError" 99 "a099_eMMCStatusError" 98 "a098_DiskCheckFailure" 97 "a097_AudiodRestarted" 96 "a096_VideodPipelineIssueDetected" 95 "a095_CidStorageRunningLow" 94 "a094_ModemPowerOnFailure" 93 "a093_updateEnded" 92 "a092_updateStarted" 91 "a091_VehicleLinkStall" 90 "a090_RadioPingFailError" 89 "a089_RadioReset" 88 "a088_CellRemovableSimMissing" 87 "a087_BmpReset" 86 "a086_TouchEnumerationError" 85 "a085_DeserializerError" 84 "a084_SerializerError" 83 "a083_ECallProxyWatchdogTriggered" 82 "a082_NumModemRebootStuckInECall" 81 "a081_CellModemSearchExpired" 80 "a080_DashcamUsbDriveSlow" 79 "a079_DashcamUsbDriveFull" 78 "a078_DashcamUsbDriveUnmountable" 77 "a077_AudioA2bMicChannelSwap" 76 "a076_NumFalseManualECalls" 75 "a075_BackupCameraInitError" 74 "a074_EMMCHangDetected" 73 "a073_ECallDigitalMicFailed" 72 "a072_ECallAnalogMicFailed" 71 "a071_VideoPipelineError" 70 "a070_VideoPipelineWarning" 69 "a069_VideoUDPTimeout" 68 "a068_VideoUnexpectedExit" 67 "a067_WarnOnI915" 66 "a066_GpuHangDetected" 65 "a065_WiFiRecoveryReset" 64 "a064_ModemFirmwareTestFailed" 63 "a063_CellularTestFailed" 62 "a062_ENSTestFailed" 61 "a061_SIMTestFailed" 60 "a060_ECallMicDisconnected" 59 "a059_ECallSpeakerDisconnected" 58 "a058_GPSAntennaDisconnected" 57 "a057_CellAntennaDisconnected" 56 "a056_ManualECallButtonDisconnected" 55 "a055_ManualECallDisabled" 54 "a054_AudioBoostPowerBad" 53 "a053_QtCarExitError" 52 "a052_KernelPanicReported" 51 "a051_BackupCameraFrameTimeout" 50 "a050_BackupCameraIPUTimeout" 49 "a049_BrakeShiftRequired" 48 "a048_AudioPremiumAmpCheckFailed" 47 "a047_CellRoamingDisallowed" 46 "a046_BackupCameraStreamError" 45 "a045_ECallSystemCheckFailed" 44 "a044_AudioDmesgDspException" 43 "a043_InvalidMapDataOverride" 42 "a042_AudioDmesgRtThrottling" 41 "a041_AudioDmesgXrun" 40 "a040_HomelinkTransmit" 39 "a039_AudioA2bNeedRediscovery" 38 "a038_AudioWatchdogA2bI2cLockupError" 37 "a037_AudioWatchdogXrunStormError" 36 "a036_AudioWatchdog" 35 "a035_FrunkOpenChime" 34 "a034_WakeupProblem" 33 "a033_ApTrialExpired" 32 "a032_CellModemRecoveryResets" 31 "a031_BrakeFluidLow" 30 "a030_ModemVMCrash" 29 "a029_ModemMIA" 28 "a028_FrontTrunkPopupClosed" 27 "a027_AutoSteerMIA" 26 "a026_ModemResetLoopDetected" 24 "a024_WifiInternetCheckFailed" 23 "a023_CellInternetCheckFailed" 22 "a022_ApeFusesEtc" 21 "a021_RearSeatbeltUnbuckled" 20 "a020_SteeringReduced" 19 "a019_ParkBrakeFault" 18 "a018_SlipStartOn" 17 "a017_TPMSSystemFault" 16 "a016_TPMSTemperatureWarning" 15 "a015_TPMSOverPressureWarning" 14 "a014_TPMSSoftWarning" 13 "a013_TPMSHardWarning" 12 "a012_NotOnPrivateProperty" 11 "a011_IncorrectMap" 10 "a010_MapsMissing" 9 "a009_SquashfsError" 8 "a008_TouchScreenError" 7 "a007_SoftPackConfigMismatch" 6 "a006_RemoteServiceAlert" 5 "a005_HeadlightsOnDoorOpen" 4 "a004_FrunkOpen" 3 "a003_TrunkOpen" 2 "a002_DoorOpen" 1 "a001_DriverDoorOpen" 0 "ALERT_DO_NOT_USE_ZERO" ;
VAL_ 1523 UI_alertState 1 "SET" 0 "CLEARED" ;
VAL_ 1523 UI_a009_squashfsDevice 9 "FS_ROOTFS" 8 "FS_TSLA_VAR" 7 "FS_BMAP" 6 "FS_AMAP" 5 "FS_HOME" 4 "FS_APPS_USR" 3 "FS_APPS_VAR" 2 "FS_VAR" 1 "FS_LOG" 0 "Unknown" ;
VAL_ 1523 UI_a036_audioWatchdogReason 5 "EXCEPTION_DETECTED" 4 "TDA7802_CANNOT_CONFIGURE_AMP" 3 "TDA7802_CANNOT_OPEN_CODEC_NEG_110" 2 "IPC_DELETE_PIPELINE_FAILED_NEG_110" 1 "IPC_SET_DX_FAILED_NEG_110" 0 "DISABLING_IRQ_NUM_25" ;
VAL_ 1523 UI_a087_BmpResetType 5 "WATCHDOG" 4 "POWER_ON" 3 "WARM" 2 "COLD" 1 "GLOBAL" 0 "UNKNOWN" ;
VAL_ 1523 UI_a131_DisplayPortFailureType 1 "DPCD_READ_FAILURE" 0 "UNKNOWN_LANE_TRAIN_FAILURE" ;
VAL_ 1523 UI_a147_whichASIL 1 "A" 0 "B" ;
VAL_ 1523 UI_a147_errorCode 24 "TOUCH_PLL_WATCHDOG" 23 "DISPLAY_PLL_WATCHDOG" 22 "PANEL_BROKEN" 21 "FLASH_CRC" 20 "LVDS_FAIL_SAFE" 19 "LVDS_DLL_LOCK" 18 "NO_HS_DE" 17 "NO_VS" 16 "NO_CLOCK" 15 "SOURCE" 14 "GATE" 13 "OVER_TEMP" 12 "VGL_OVD" 11 "VGH_OVD" 10 "AVEE_OVD" 9 "AVVD_OVD" 8 "VCOM_OVD" 7 "VDDI_OVD" 6 "VGL_LVD" 5 "VGH_LVD" 4 "AVEE_LVD" 3 "AVDD_LVD" 2 "VCOM_LVD" 1 "VDDI_LVD" 0 "UNKNOWN" ;
VAL_ 1523 UI_a148_sleepType 4 "Unknown" 3 "ModernStandby" 2 "S2Idle" 1 "S3" 0 "Shallow" ;
VAL_ 1523 UI_a148_lastFailedPmSuspendDev 18 "Timesync" 17 "LED" 16 "Button" 15 "NVME" 14 "Hermes" 13 "Cameras" 12 "Modem" 11 "Bluetooth" 10 "Wifi" 9 "USB" 8 "Audio" 7 "BluetoothRear" 6 "DGPU" 5 "Post" 4 "Memory" 3 "UsbMsd" 2 "Steam" 1 "Unknown" 0 "None" ;
VAL_ 1523 UI_a149_displayType 9 "MY_DP_P103" 8 "CT_DP_185" 7 "M3_DP_P882" 6 "SX_HDMI_R94" 5 "M3_HDMI_E2X" 4 "M3_HDMI_P88" 3 "SX_HDMI_8" 2 "SX_HDMI_11" 1 "SX_DP_17" 0 "Unknown" ;
VAL_ 1523 UI_a149_displaySeat 3 "Rear" 2 "Cluster" 1 "Center" 0 "Unknown" ;
VAL_ 1523 UI_a149_errorCode 21 "UnknownDisplay" 20 "EdidRead" 19 "EepromRead" 18 "I2CRebootRequested" 17 "HDMIFrequencyChanged" 16 "ASILStatusFault" 15 "OsdCrcFailedToEnable" 14 "OsdCrcI2CReadWriteFailure" 13 "OsdCrcSecondaryTconMismatch" 12 "OsdCrcMainTconMismatch" 11 "PowerControl" 10 "TouchStatus" 9 "GammaControl" 8 "GatewayWedged" 7 "ResetFailure" 6 "SerDesLink" 5 "LaneTraining" 4 "BacklightEnumeration" 3 "BacklightMismatch" 2 "BacklightPower" 1 "BacklightControl" 0 "Unknown" ;
VAL_ 1523 UI_a153_processName 13 "QTCAR" 12 "QTCAR_ACCOUNTMANAGER" 11 "QTCAR_AUDIOD" 10 "QTCAR_BLUETOOTH" 9 "QTCAR_CARSERVER" 8 "QTCAR_CLUSTER" 7 "QTCAR_CONNMAN" 6 "QTCAR_EVLOGSERVICE" 5 "QTCAR_GPSMANAGER" 4 "QTCAR_MEDIASERVER" 3 "QTCAR_SPEECH_RECOGNIZER" 2 "QTCAR_SPOTIFYSERVER" 1 "QTCAR_VEHICLE" 0 "UNKNOWN" ;
VAL_ 1523 UI_a153_restartReason 3 "OVER_MEM" 2 "DEAD" 1 "LOST_SHARED_MEM" 0 "UNKNOWN" ;
VAL_ 1523 UI_a158_UsbDeviceMountErrorCode 30 "READ_ONLY_FILE_SYSTEM" 22 "INVALID_ARGUMENT" 19 "NO_SUCH_DEVICE" 16 "DEVICE_OR_RESOURCE_BUSY" 13 "PERMISSION_DENIED" 12 "OUT_OF_MEMORY" 6 "NO_SUCH_DEVICE_OR_ADDRESS" 5 "IO_ERROR" 2 "NO_SUCH_FILE_OR_DIRECTORY" ;
VAL_ 1523 UI_a165_fsCorruptedDevice 9 "FS_ROOTFS" 8 "FS_TSLA_VAR" 7 "FS_BMAP" 6 "FS_AMAP" 5 "FS_HOME" 4 "FS_APPS_USR" 3 "FS_APPS_VAR" 2 "FS_VAR" 1 "FS_LOG" 0 "Unknown" ;
VAL_ 1523 UI_a166_fsErrorDevice 9 "FS_ROOTFS" 8 "FS_TSLA_VAR" 7 "FS_BMAP" 6 "FS_AMAP" 5 "FS_HOME" 4 "FS_APPS_USR" 3 "FS_APPS_VAR" 2 "FS_VAR" 1 "FS_LOG" 0 "Unknown" ;
VAL_ 1523 UI_a167_processId 27 "unreal_apviz_mem" 26 "infoz_temp_monitor" 25 "alertd" 24 "tunaman" 23 "hermes_log" 22 "thermald" 21 "apviz_assetgen_mem" 20 "apviz_controls_mem" 19 "apviz_mem" 18 "dashcam_viewer" 17 "qtcar_radioserver" 16 "mediaserver" 15 "hermes_fleet_streaming" 14 "hermes_dynamic_triggers" 13 "chromium_odin" 12 "chromium_odin_gpu" 11 "chromium_app" 10 "chromium_app_gpu" 9 "chromium_fullscreen" 8 "chromium_fullscreen_gpu" 7 "chromium" 6 "chromium_gpu" 5 "valhalla_server" 4 "QtCarSpeechReco" 3 "QtCarGpsManager" 2 "QtCarTMServer" 1 "QtCar" 0 "Unknown" ;
VAL_ 1523 UI_a173_errorCode 2 "MODEM" 1 "RESERVED" 0 "NONE" ;
VAL_ 1523 UI_a173_lastFailedPmSuspendDev 18 "Timesync" 17 "LED" 16 "Button" 15 "NVME" 14 "Hermes" 13 "Cameras" 12 "Modem" 11 "Bluetooth" 10 "Wifi" 9 "USB" 8 "Audio" 7 "BluetoothRear" 6 "DGPU" 5 "Post" 4 "Memory" 3 "UsbMsd" 2 "Steam" 1 "Unknown" 0 "None" ;
VAL_ 1523 UI_a176_PrimaryAntenna 5 "SHORTED" 4 "OPEN" 3 "NORMAL" 2 "UNKNOWN" 1 "NOT_POWERED" 0 "INITIALIZING" ;
VAL_ 1523 UI_a176_SecondaryAntenna 5 "SHORTED" 4 "OPEN" 3 "NORMAL" 2 "UNKNOWN" 1 "NOT_POWERED" 0 "INITIALIZING" ;
VAL_ 1523 UI_a176_TertiaryAntenna 5 "SHORTED" 4 "OPEN" 3 "NORMAL" 2 "UNKNOWN" 1 "NOT_POWERED" 0 "INITIALIZING" ;
VAL_ 1523 UI_a177_errorCode 18 "LICENSE_ERROR" 17 "WIDEVINE_CDM_EXPIRED" 16 "ACTIVE_PHONE_CALL" 15 "PLAYBACK_ERROR" 14 "WIFI_REQUIRED" 13 "UNSPECIFIED_ERROR" 12 "PLAYING_ON_ANOTHER_DEVICE" 11 "FAILED_TO_LOAD_TRACKS" 10 "INVALID_STREAM" 9 "INVALID_URL" 8 "EXPLICIT_CONTENT" 7 "STREAMING_DISABLED" 6 "NO_RESPONSE_FROM_MEDIA_SERVER" 5 "BITRATE_TOO_HIGH" 4 "NO_INTERNET" 3 "NETWORK_ERROR" 2 "NO_STATION" 1 "NO_PLAYER" 0 "NO_ERROR" ;
VAL_ 1523 UI_a177_errorSource 39 "SODA_MUSIC" 38 "CARAOKE" 37 "KUGOU" 36 "YOUTUBE_MUSIC" 35 "YUNTING" 34 "AMAZON_MUSIC" 33 "AUDIBLE" 32 "APPLE_PODCASTS" 31 "APPLE_MUSIC" 30 "MINI_PROGRAMS" 29 "SEARCH" 28 "HOME_APPS" 27 "RECENTS_FAVORITES" 26 "TOYBOX" 25 "TUTORIAL" 24 "THEATER" 23 "BROWSER" 22 "GAME" 21 "NET_EASE_MUSIC" 20 "ONLINE_RADIO" 19 "XIMALAYA" 18 "QQ_MUSIC2" 17 "QQ_MUSIC1" 16 "TIDAL" 15 "SIRIUS_XM" 14 "STINGRAY" 13 "TUNE_IN" 12 "EU_RADIO" 11 "US_RADIO" 10 "SPOTIFY" 9 "SLACKER" 8 "BLUETOOTH" 7 "USB" 6 "DAB" 5 "XM" 4 "FM" 3 "AM" 2 "UNKNOWN" 1 "DEPRECATED" 0 "NONE" ;
VAL_ 1523 UI_a192_AudioRebootState 9 "REBOOTED_CRITICAL_KERNEL_ERROR" 8 "REBOOTED_KERNEL_ERROR" 7 "BLOCKED_REASON_CAR_NOT_PARKED" 6 "BLOCKED_REASON_REBOOT_TIME_EXPIRED" 5 "BLOCKED_REASON_REBOOT_COMMAND_FAILED" 4 "BLOCKED_REASON_SOFTWARE_UPDATE_IN_PROGRESS" 3 "BLOCKED_REASON_GATEWAY_UPDATE_IN_PROGRESS" 2 "BLOCKED_REASON_TOWING_MODE_REQUESTED" 1 "BLOCKED_REASON_AUDIO_POWER_ISSUE_DETECTED" 0 "BLOCKED_REASON_UNEXPECTED_AUDIO_STATE" ;
VAL_ 1523 UI_a204_ModemSleepFailureReason 5 "MODEM_FAILURE" 4 "ADSP_FAILURE" 3 "SLEEP_CANCELLED" 2 "ALREADY_ASLEEP" 1 "ETHERNET_FAILURE" 0 "NO_ERROR" ;
VAL_ 1523 UI_a214_lastFailedPmSuspendDev 18 "Timesync" 17 "LED" 16 "Button" 15 "NVME" 14 "Hermes" 13 "Cameras" 12 "Modem" 11 "Bluetooth" 10 "Wifi" 9 "USB" 8 "Audio" 7 "BluetoothRear" 6 "DGPU" 5 "Post" 4 "Memory" 3 "UsbMsd" 2 "Steam" 1 "Unknown" 0 "None" ;
VAL_ 1523 UI_a216_circuitProblem 42 "NON_LOCALIZED_SHORT_TO_VBAT" 41 "NON_LOCALIZED_SHORT_TO_GND" 15 "INDETERMINATE_FAULT" 13 "CABLE_REVERSE_CONNECTED" 12 "CABLE_DISCONNECTED_OR_OPEN_CIRCUIT" 11 "CABLE_SHORTED_TOGETHER" 10 "CABLE_SHORTED_TO_VBAT" 9 "CABLE_SHORTED_TO_GND" ;
VAL_ 1523 UI_a216_circuitNode 3 "UNKNOWN" 2 "AMP" 1 "MIC" 0 "MASTER" ;
VAL_ 1523 UI_a217_cgroupName 27 "unreal_apviz_mem" 26 "infoz_temp_monitor" 25 "alertd" 24 "tunaman" 23 "hermes_log" 22 "thermald" 21 "apviz_assetgen_mem" 20 "apviz_controls_mem" 19 "apviz_mem" 18 "dashcam_viewer" 17 "qtcar_radioserver" 16 "mediaserver" 15 "hermes_fleet_streaming" 14 "hermes_dynamic_triggers" 13 "chromium_odin" 12 "chromium_odin_gpu" 11 "chromium_app" 10 "chromium_app_gpu" 9 "chromium_fullscreen" 8 "chromium_fullscreen_gpu" 7 "chromium" 6 "chromium_gpu" 5 "valhalla_server" 4 "QtCarSpeechReco" 3 "QtCarGpsManager" 2 "QtCarTMServer" 1 "QtCar" 0 "Unknown" ;
VAL_ 1523 UI_a220_errorCode 11 "UPDATE_REQUIRED" 10 "CONTENT_BLOCKED" 9 "SERVICE_UNAVAILABLE" 8 "INTERNAL_SERVER_ERROR" 7 "TOO_MANY_REQUESTS" 6 "TIMEOUT" 5 "NOT_FOUND" 4 "FORBIDDEN" 3 "UNAUTHORIZED" 2 "BAD_REQUEST" 1 "INTERNAL_ERROR" 0 "NETWORK_ERROR" ;
VAL_ 1523 UI_a221_errorCode 12 "SERVER_ERROR" 11 "NETWORK_ERROR" 10 "SIMULATE_NAV_SERVICE_FAILURE" 9 "PARSE_VALHALLA_ATTRIBUTES_FAILURE" 8 "MAP_OVERRIDE_ERROR" 7 "NO_ROUTE_ERROR" 6 "PARSE_GRPC_ERROR" 5 "VOYAGER_TRIP_PLAN_NOT_POSSIBLE_ERROR" 4 "RESPONSE_STATUS_ERROR" 3 "INCOMPLETE_RESPONSE" 2 "PARSE_VALHALLA_ROUTE_FAILURE" 1 "DECODE_PROTOBUF_FAILURE" 0 "UNKNOWN_FAILURE" ;
VAL_ 1523 UI_a221_networkErrorCode 500 "SNA" 499 "UNKNOWN_SERVER_ERROR" 403 "SERVICE_UNAVAILABLE_ERROR" 402 "OPERATION_NOT_IMPLEMENTED_ERROR" 401 "INTERNAL_SERVER_ERROR" 399 "PROTOCOL_FAILURE" 302 "PROTOCOL_INVALID_OPERATION_ERROR" 301 "PROTOCOL_UNKNOWN_ERROR" 299 "UNKNOWN_CONTENT_ERROR" 207 "CONTENT_GONE_ERROR" 206 "CONTENT_CONFLICT_ERROR" 205 "CONTENT_RE_SEND_ERROR" 204 "AUTHENTICATION_REQUIRED_ERROR" 203 "CONTENT_NOT_FOUND_ERROR" 202 "CONTENT_OPERATION_NOT_PERMITTED_ERROR" 201 "CONTENT_ACCESS_DENIED" 199 "UNKNOWN_PROXY_ERROR" 105 "PROXY_AUTHENTICATION_REQUIRED_ERROR" 104 "PROXY_TIMEOUT_ERROR" 103 "PROXY_NOT_FOUND_ERROR" 102 "PROXY_CONNECTION_CLOSED_ERROR" 101 "PROXY_CONNECTION_REFUSED_ERROR" 99 "UNKNOWN_NETWORK_ERROR" 11 "INSECURE_REDIRECT_ERROR" 10 "TOO_MANY_REDIRECTS_ERROR" 9 "BACKGROUND_REQUEST_NOT_ALLOWED_ERROR" 8 "NETWORK_SESSION_FAILED_ERROR" 7 "TEMPORARY_NETWORK_FAILURE_ERROR" 6 "SSL_HANDSHAKE_FAILED_ERROR" 5 "OPERATION_CANCELED_ERROR" 4 "TIMEOUT_ERROR" 3 "HOST_NOT_FOUND_ERROR" 2 "REMOTE_HOST_CLOSED_ERROR" 1 "CONNECTION_REFUSED_ERROR" 0 "NO_ERROR" ;
VAL_ 1523 UI_a222_errorCode 11 "TIMED_OUT" 10 "OVER_GEM_OBJECT_MEMORY" 9 "OVER_MEMORY" 8 "LOST_SHARED_MEMORY" 7 "MANUAL" 6 "START_FTRACE_SNIFFING" 5 "CHANGED_TEXT_ACCESSIBILITY_OPTION" 4 "EXIT_TRANSPORT_MODE" 3 "ENTER_TRANSPORT_MODE" 2 "CUSTOMER_MODE_REQUESTED" 1 "LANGUAGE_CHANGED" 0 "OTHER" ;
VAL_ 1523 UI_a223_database 39 "APP_PUSH_NOTIFICATION" 38 "RADIO_SERVER_SETTINGS" 37 "TM_SERVER_SETTINGS" 36 "SPOTIFY_SERVER_SETTINGS" 35 "RELEASE_NOTES_SETTINGS" 34 "QTCAR_VEHICLE_POWER_SETTINGS" 33 "QTCAR_ENERGY_MONITOR_SETTINGS" 32 "ENERGY_CONSUMPTION" 31 "QTCAR_DV_SERVER_SETTINGS" 30 "QTCAR_CONNMAN_SETTINGS" 29 "QTCAR_AUDIOD_SETTINGS" 28 "OWNERS_MANUAL_SETTINGS" 27 "OWNERS_MANUAL_ADAPTER_SETTINGS" 26 "QTCAR_MONITOR_SETTINGS" 25 "QTCAR_MEDIA_SERVER2_SETTINGS" 24 "QTCAR_GPS_MANAGER_SETTINGS" 23 "QTCAR_FIRMWARE_INSTALL_SETTINGS" 22 "QTCAR_ECALL_CLIENT_SETTINGS" 21 "DASHCAM_VIEWER_SETTINGS" 20 "QTCAR_CONN_METRICS_SETTINGS" 19 "ACCOUNT_MANAGER_SETTINGS" 18 "BT_DEVICES" 17 "CALENDAR" 16 "NUANCE_SERVER_SETTINGS" 15 "PHONEBOOK_V2" 14 "QTCAR_BLUETOOTH_SETTINGS" 13 "QTCAR_EVLOG_SERVICE_SETTINGS" 12 "QTCAR_SERVER_SETTINGS" 11 "QTCAR_SETTINGS" 10 "QTCAR_SPEECH_RECOGNIZER_SETTINGS" 9 "QTCAR_VEHICLE_SETTINGS" 8 "VEHICLE_DATAKEYS" 7 "MSG_TRACK" 6 "PLACES_RECOMMENDATION" 5 "VEHICLE_LOG2" 4 "PROFILE_FRECENCY" 3 "PROFILE_PLACES_RECENT" 2 "PLACES_RECENT" 1 "FRECENCY" 0 "UNKNOWN" ;
VAL_ 1523 UI_a229_errorCode 13 "HDMI_FREQ" 12 "LINK_DETECT" 11 "SIGNAL_DETECT" 10 "TMDS_CLOCK" 9 "RX_FIVE_V_DETECT" 8 "INIT_DONE" 7 "CFG_CKSUM" 6 "FPD_THREE_LINK_RDY" 5 "FPD_THREE_TX_STS" 4 "TMDS_VALID" 3 "HDMI_PLL_LOCK" 2 "FREQ_STABLE" 1 "CLOCK_RECV" 0 "DL_MODE" ;
VAL_ 1523 UI_a231_sleepType 4 "Unknown" 3 "ModernStandby" 2 "S2Idle" 1 "S3" 0 "Shallow" ;
VAL_ 1523 UI_a232_processExited 24 "SPOTIFY_SERVER" 23 "QTCAR" 22 "QTCAR_CLUSTER" 21 "QTCAR_VEHICLE" 20 "QTCAR_BLUETOOTH" 19 "QTCAR_CONNMAN" 18 "QTCAR_DVSERVER" 17 "QTCAR_EVLOGSERVICE" 16 "QTCAR_FIRMWAREINSTALL" 15 "QTCAR_MEDIASERVERV2" 14 "QTCAR_RADIOSERVER" 13 "QTCAR_SIMSERVICE" 12 "QTCAR_SPEECHRECOGNIZER" 11 "QTCAR_STARTUP" 10 "QTCAR_TMSERVER" 9 "QTCAR_AUDIOD" 8 "QTCAR_CHECKINTERNET" 7 "QTCAR_ECALLCLIENT" 6 "QTCAR_ENERGYMONITOR" 5 "QTCAR_GPSMANAGER" 4 "QTCAR_MONITOR" 3 "QTCAR_SERVER" 2 "QTCAR_VEHICLEPOWER" 1 "UNKNOWN" ;
VAL_ 1523 UI_a232_processSignal 11 "SEGMENTATION_FAULT" 8 "FLOATING_POINT_EXCEPTION" 7 "BUS_ERROR" 6 "ABORT" 4 "ILLEGAL_INSTRUCTION" 1 "UNKNOWN" ;
VAL_ 1523 UI_a240_ethErrorType 6 "TX_FLOOD" 5 "RX_FLOOD" 4 "TX_OVERRUN" 3 "RX_OVERRUN" 2 "TX_ERROR" 1 "RX_ERROR" 0 "UNKNOWN" ;
VAL_ 1523 UI_a247_displayType 9 "MY_DP_P103" 8 "CT_DP_185" 7 "M3_DP_P882" 6 "SX_HDMI_R94" 5 "M3_HDMI_E2X" 4 "M3_HDMI_P88" 3 "SX_HDMI_8" 2 "SX_HDMI_11" 1 "SX_DP_17" 0 "Unknown" ;
VAL_ 1523 UI_a247_displaySeat 3 "Rear" 2 "Cluster" 1 "Center" 0 "Unknown" ;
VAL_ 1523 UI_a257_ModemRebootReason 4 "HARD_REBOOT_GPIO_FAIL" 3 "HARD_REBOOT_A2B_FAIL" 2 "HARD_REBOOT_FALLBACK" 1 "HARD_REBOOT" 0 "GRACEFUL_REBOOT" ;
VAL_ 1523 UI_a257_ModemRebootEthPresent 1 "NO_ETH" 0 "WITH_ETH" ;
VAL_ 1523 UI_a261_bluetoothStackPanicReaso 46 "SM_INVALID_STATE" 45 "SM_ACL_NOT_IN_PAIRING_LIST" 44 "SM_INVALID_RPA_TYPE" 43 "SM_RANDOM_GENERATION_FAILURE" 42 "SM_PAIRING_SANITY_FAILURE" 41 "SM_MARSHAL_UNMARSHAL_INVALID_STATE" 40 "SDM_CIS_INSTANCE_NOT_FOUND" 39 "SDM_MARSHAL_UNMARSHAL_INVALID_STATE" 38 "RFCOMM_MARSHAL_UNMARSHAL_INVALID_STATE" 37 "L2CAP_MARSHAL_UNMARSHAL_INVALID_STATE" 36 "L2CAP_FLOW_CTRL_INSTANCE_SANITY_FAILED" 35 "L2CAP_CONFIG_BUF_NULL" 34 "L2CAP_MALLOC_FAILED" 33 "L2CAP_MBLK_DATA_LEN_MTU_MISMATCH" 32 "L2CAP_INVALID_CID" 31 "L2CAP_READ_CONFTAB_FAILED" 30 "DM_MULTIPLE_ACL_LIST_FOUND" 29 "DM_MARSHAL_UNMARSHAL_INVALID_STATE" 28 "BLUESTACK_UNEXPECTED_HCI_COMMAND_COMPLETE" 27 "HCISHIM_HCI_SEND_FAILED" 26 "DM_AE_SET_SCAN_PARAM_FAILED" 25 "DM_AE_INVALID_ADV_HANDLE" 24 "DM_CLIENT_ACL_NULL" 23 "DM_ACL_SANITY_FAILED" 22 "INVALID_TIMER_ID" 21 "TRANSPORT_UNRESPONSIVE" 20 "ATT_FIXED_CID_REG_FAILED" 19 "DM_INVALID_HANDLE" 18 "ATT_INVALID_TYPE" 17 "ATT_INVALID_STATE" 16 "SM_L2CAP_HANDLER" 15 "INVALID_ULP_BUFFER_SIZE_RESPONSE" 14 "DM_ACL_LOCKS_EXHAUSED" 13 "RFCOMM_STREAM_MISMATCH" 12 "RFCOMM_L2CAP_REGISTER_FAILED" 11 "MBLK_CREATE_FAILURE" 10 "RFCOMM_INVALID_TIMER_CONTEXT" 9 "RFCOMM_INVALID_TIMER_TYPE" 8 "RFCOMM_TIMER_ALREADY_STARTED" 7 "MBLK_DISCARD_TAIL_ERROR" 6 "MBLK_MSGFRAG_COALESCE_FAILURE" 5 "HEAP_EXHAUSTION" 4 "INVALID_ESCO_TX_INTERVAL" 3 "INVALID_BLUESTACK_PRIMITIVE" 2 "L2CAP_HCI_DATA_CREDITS_INCONSISTENT" 1 "MBLK_MAP_ERROR" 0 "UNKNOWN" ;
VAL_ 1523 UI_a274_hintCardType 10 "FSD_TRIAL" 9 "ACTIVATE_FSD_LANE_KEEP_ASSIST" 8 "ACTIVATE_FSD_DROWSY_DRIVER" 7 "ACTIVATE_FSD_ON_HIGHWAY" 6 "ACTIVATE_FSD_IN_TRAFFIC" 5 "START_FSD_FROM_PARK" 4 "ENABLE_FSD" 3 "END_TO_END_FSD_HIGHWAY_A_PEDAL" 2 "END_TO_END_FSD_HIGHWAY" 1 "ACTIVATE_FSD" 0 "UNKNOWN" ;
VAL_ 1523 UI_a274_hintCardDismissOutcome 4 "CONDITION_DISMISSED" 3 "SWIPED_AWAY" 2 "TIMED_OUT" 1 "SUCCESSFUL" 0 "UNKNOWN" ;
